VERSION "dbc-export 1 2025.20.8"

NS_ :

BS_:

BU_: ADSP APB APP APS APSB BB BMS CC CMP CMPD CP DAS DI DIF DIR DPB EPAS3P EPAS3S EPASTP EPASTS EPBL EPBR ESP EVSE FC GTW HCML HCMR HVP IBST ICR IDB LS OCS1P PARK PCS PM PMF PMR PNCD PTC RADC RCM RCM2 RCM3 RCU SCCM SCM SCS SDCR TAS TCU TPMS TRCM UI UIS UMC USM VC VCFRONT VCLEFT VCRIGHT VCSEC VEH

BO_ 609 VCFRONT_12VBatteryStatus: 8 VCFRONT
 SG_ VCFRONT_12VBatteryStatusIndex M : 0|3@1+ (1,0) [0|7] "" Vector__XXX
 SG_ VCFRONT_good12VforUpdate : 46|1@1+ (1,0) [0|1] "" Vector__XXX
 SG_ VCFRONT_LVLoadRequest : 47|1@1+ (1,0) [0|1] "" Vector__XXX
 SG_ VCFRONT_12VBatteryStatusCounter : 52|4@1+ (1,0) [0|15] "" Vector__XXX
 SG_ VCFRONT_12VBatteryStatusChecksum : 56|8@1+ (1,0) [0|255] "" Vector__XXX
 SG_ VCFRONT_batterySupportRequest m1 : 3|1@1+ (1,0) [0|1] "" Vector__XXX
 SG_ VCFRONT_batterySMState m1 : 4|4@1+ (1,0) [0|15] "" Vector__XXX
 SG_ VCFRONT_eFuseRecoveryStateDBG m1 : 8|3@1+ (1,0) [0|7] "" Vector__XXX
 SG_ VCFRONT_batteryLINScheduleDBG m1 : 11|3@1+ (1,0) [0|7] "" Vector__XXX
 SG_ VCFRONT_resistanceEstimationTest m1 : 14|2@1+ (1,0) [0|3] "" Vector__XXX
 SG_ VCFRONT_IBSCurrent m1 : 16|16@1- (0.005,0) [-163.84|163.835] "A" Vector__XXX
 SG_ VCFRONT_IBSVoltage m1 : 32|14@1+ (0.005443676,0) [0|65.535] "V" Vector__XXX
 SG_ VCFRONT_reverseBatteryFault m1 : 48|1@1+ (1,0) [0|1] "" Vector__XXX
 SG_ VCFRONT_LVBatterySupported m1 : 49|1@1+ (1,0) [0|1] "" Vector__XXX
 SG_ VCFRONT_LVBatteryCannotSupportVe m1 : 50|1@1+ (1,0) [0|1] "" Vector__XXX
 SG_ VCFRONT_goodTemp12VforUpdate m1 : 51|1@1+ (1,0) [0|1] "" Vector__XXX
 SG_ VCFRONT_12VBatteryTargetVoltage m2 : 3|13@1+ (0.01,0) [0|65.535] "V" Vector__XXX
 SG_ VCFRONT_IBSTemperature m2 : 16|11@1+ (0.1,-24) [-24|124] "degC" Vector__XXX
 SG_ VCFRONT_currentSensorMismatchLea m2 : 27|7@1+ (2,0) [0|254] "PCT" Vector__XXX
 SG_ VCFRONT_LVBatteryEnergyRemaining m2 : 37|7@1+ (1,0) [0|127] "%" Vector__XXX
 SG_ VCFRONT_LVBatteryStatusForDrive m2 : 44|2@1+ (1,0) [0|3] "" Vector__XXX
 SG_ VCFRONT_LVBatteryType m2 : 48|3@1+ (1,0) [0|7] "" Vector__XXX
 SG_ VCFRONT_resistanceEstimationNeed m2 : 51|1@1+ (1,0) [0|1] "" Vector__XXX
 SG_ VCFRONT_IBSVoltageFiltered m3 : 3|14@1+ (0.005443676,0) [0|65.535] "V" Vector__XXX
 SG_ VCFRONT_LVBMS_LVBusVoltageSource m3 : 17|2@1+ (1,0) [0|3] "" Vector__XXX
 SG_ VCFRONT_LVBMS_LVPackCurrentSourc m3 : 19|2@1+ (1,0) [0|3] "" Vector__XXX
 SG_ VCFRONT_LVBatterySupportRqrdTrig m3 : 24|14@1+ (1,0) [0|16383] "" Vector__XXX
 SG_ VCFRONT_goodForPCSPowerCycleLeak m3 : 40|5@1+ (0.0005,0) [0|0.0155] "Ah" Vector__XXX
 SG_ VCFRONT_LVBusControlsFutile m3 : 45|1@1+ (1,0) [0|1] "" Vector__XXX
 SG_ VCFRONT_resistanceEstimatio_0001 m3 : 48|1@1+ (1,0) [0|1] "" Vector__XXX
 SG_ VCFRONT_resistanceEstimatio_0002 m3 : 49|1@1+ (1,0) [0|1] "" Vector__XXX
 SG_ VCFRONT_goodLVChargeForUpdate m3 : 50|1@1+ (1,0) [0|1] "" Vector__XXX
 SG_ VCFRONT_opportunisticDCRTestNeed m3 : 51|1@1+ (1,0) [0|1] "" Vector__XXX
 SG_ VCFRONT_voltageProfile m4 : 3|2@1+ (1,0) [0|3] "" Vector__XXX
 SG_ VCFRONT_IBSAmpHours m4 : 5|14@1- (0.005,0) [-40.96|40.955] "Ah" Vector__XXX
 SG_ VCFRONT_IBSVoltageRawDBG m4 : 19|14@1+ (0.005443676,0) [0|65.535] "V" Vector__XXX
 SG_ VCFRONT_LVBatteryLINCommsDetecte m4 : 33|1@1+ (1,0) [0|1] "" Vector__XXX
 SG_ VCFRONT_voltageSensorMismatchLea m4 : 34|7@1+ (2,0) [0|254] "PCT" Vector__XXX
 SG_ VCFRONT_LVBatteryFctryLimOverrid m4 : 50|1@1+ (1,0) [0|1] "" Vector__XXX
 SG_ VCFRONT_LVBatterySPICommsDetecte m4 : 51|1@1+ (1,0) [0|1] "" Vector__XXX
 SG_ VCFRONT_targetCurrent m5 : 3|11@1+ (0.125,-127) [0|120] "A" Vector__XXX
 SG_ VCFRONT_PCSMia m5 : 14|1@1+ (1,0) [0|1] "" Vector__XXX
 SG_ VCFRONT_chargeNeeded m5 : 15|1@1+ (1,0) [0|1] "" Vector__XXX
 SG_ VCFRONT_voltageControlLoopIntegr m5 : 16|14@1+ (0.006,0) [0|65.535] "V" Vector__XXX
 SG_ VCFRONT_currentControlLoopIntegr m5 : 30|14@1+ (0.006,0) [0|65.535] "V" Vector__XXX

BO_ 1847 VCFRONT_LVBMS_info: 8 VCFRONT
 SG_ VCFRONT_LVBMS_InfoIndex M : 0|8@1+ (1,0) [0|255] "" Vector__XXX
 SG_ VCFRONT_LVBMS_PcbaId m0 : 8|16@1+ (1,0) [0|65535] "" Vector__XXX
 SG_ VCFRONT_LVBMS_AssemblyId m0 : 24|16@1+ (1,0) [0|65535] "" Vector__XXX
 SG_ VCFRONT_LVBMS_SubUsageId m0 : 40|16@1+ (1,0) [0|65535] "" Vector__XXX
 SG_ VCFRONT_LVBMS_UsageId m1 : 8|16@1+ (1,0) [0|65535] "" Vector__XXX
 SG_ VCFRONT_LVBMS_AppCRC m1 : 24|32@1+ (1,0) [0|4294967295] "" Vector__XXX
 SG_ VCFRONT_LVBMS_FWBuildType m3 : 8|8@1+ (1,0) [0|255] "" Vector__XXX

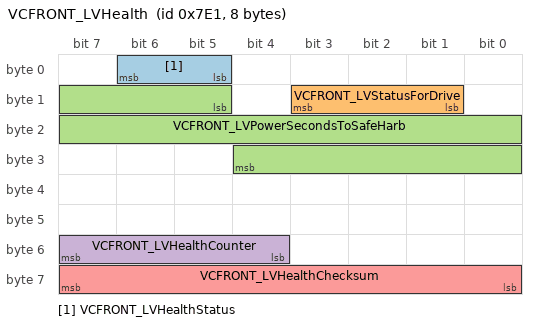
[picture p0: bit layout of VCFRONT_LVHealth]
BO_ 2017 VCFRONT_LVHealth: 8 VCFRONT
 SG_ VCFRONT_LVHealthStatus : 5|2@1+ (1,0) [0|3] "" Vector__XXX
 SG_ VCFRONT_LVStatusForDrive : 9|3@1+ (1,0) [0|7] "" Vector__XXX
 SG_ VCFRONT_LVPowerSecondsToSafeHarb : 13|16@1+ (1,0) [0|65535] "" Vector__XXX
 SG_ VCFRONT_LVHealthCounter : 52|4@1+ (1,0) [0|15] "" Vector__XXX
 SG_ VCFRONT_LVHealthChecksum : 56|8@1+ (1,0) [0|255] "" Vector__XXX

BO_ 2016 VCFRONT_LVHealthDebug: 8 VCFRONT
 SG_ VCFRONT_LVHealthDebugIndex M : 0|4@1+ (1,0) [0|15] "" Vector__XXX
 SG_ VCFRONT_LVHEALTH_placeholder m0 : 8|1@1+ (1,0) [0|1] "" Vector__XXX
 SG_ VCFRONT_LVHEALTH_activeDecelEner m0 : 9|1@1+ (1,0) [0|1] "" Vector__XXX
 SG_ VCFRONT_LVHEALTH_criticalPullove m0 : 10|1@1+ (1,0) [0|1] "" Vector__XXX
 SG_ VCFRONT_LVHEALTH_revBattEFuseOff m0 : 11|1@1+ (1,0) [0|1] "" Vector__XXX
 SG_ VCFRONT_LVHEALTH_LVBMBEFuseOpen m0 : 12|1@1+ (1,0) [0|1] "" Vector__XXX
 SG_ VCFRONT_LVHEALTH_lvBatteryCommsM m0 : 13|1@1+ (1,0) [0|1] "" Vector__XXX
 SG_ VCFRONT_LVHEALTH_pcsEFuseOff m0 : 14|1@1+ (1,0) [0|1] "" Vector__XXX
 SG_ VCFRONT_LVHEALTH_pcsNotActive m0 : 15|1@1+ (1,0) [0|1] "" Vector__XXX
 SG_ VCFRONT_LVHEALTH_pcsMIA m0 : 16|1@1+ (1,0) [0|1] "" Vector__XXX
 SG_ VCFRONT_LVHEALTH_IBSMIA m0 : 17|1@1+ (1,0) [0|1] "" Vector__XXX
 SG_ VCFRONT_LVHEALTH_LVBatteryElecDi m0 : 18|1@1+ (1,0) [0|1] "" Vector__XXX
 SG_ VCFRONT_LVHEALTH_LVBatteryE_0001 m0 : 19|1@1+ (1,0) [0|1] "" Vector__XXX
 SG_ VCFRONT_LVHEALTH_pcsOpenCircuit m0 : 20|1@1+ (1,0) [0|1] "" Vector__XXX
 SG_ VCFRONT_LVHEALTH_activeDecelPowe m0 : 21|1@1+ (1,0) [0|1] "" Vector__XXX
 SG_ VCFRONT_LVHEALTH_lvBatteryCapabi m0 : 22|1@1+ (1,0) [0|1] "" Vector__XXX
 SG_ VCFRONT_LVHEALTH_lvBatteryConfig m0 : 23|1@1+ (1,0) [0|1] "" Vector__XXX
 SG_ VCFRONT_LVHEALTH_lvBatteryImpeda m0 : 24|1@1+ (1,0) [0|1] "" Vector__XXX

BO_ 545 VCFRONT_LVPowerState: 8 VCFRONT
 SG_ VCFRONT_LVPowerStateIndex M : 0|5@1+ (1,0) [0|31] "" Vector__XXX
 SG_ VCFRONT_vehiclePowerState : 5|2@1+ (1,0) [0|3] "" Vector__XXX
 SG_ VCFRONT_inAccessoryPlus : 50|1@1+ (1,0) [0|1] "" Vector__XXX
 SG_ VCFRONT_LVShuttingDown : 51|1@1+ (1,0) [0|1] "" Vector__XXX
 SG_ VCFRONT_LVPowerStateCounter : 52|4@1+ (1,0) [0|15] "" Vector__XXX
 SG_ VCFRONT_LVPowerStateChecksum : 56|8@1+ (1,0) [0|255] "" Vector__XXX
 SG_ VCFRONT_cpLVRequest m1 : 8|2@1+ (1,0) [0|3] "" Vector__XXX
 SG_ VCFRONT_epasLVState m1 : 10|2@1+ (1,0) [0|3] "" Vector__XXX
 SG_ VCFRONT_hvcLVRequest m1 : 12|2@1+ (1,0) [0|3] "" Vector__XXX
 SG_ VCFRONT_tasLVState m1 : 14|2@1+ (1,0) [0|3] "" Vector__XXX
 SG_ VCFRONT_pcsLVState m1 : 16|2@1+ (1,0) [0|3] "" Vector__XXX
 SG_ VCFRONT_CMPDLVState m1 : 18|2@1+ (1,0) [0|3] "" Vector__XXX
 SG_ VCFRONT_hcmlLVState m1 : 20|2@1+ (1,0) [0|3] "" Vector__XXX
 SG_ VCFRONT_hcmrLVState m1 : 22|2@1+ (1,0) [0|3] "" Vector__XXX
 SG_ VCFRONT_MCUAudioLVState m1 : 24|2@1+ (1,0) [0|3] "" Vector__XXX
 SG_ VCFRONT_espValveLVState m1 : 26|2@1+ (1,0) [0|3] "" Vector__XXX
 SG_ VCFRONT_MCUGraphicsLVState m1 : 28|2@1+ (1,0) [0|3] "" Vector__XXX
 SG_ VC_dcdcSupportRequest m1 : 30|1@1+ (1,0) [0|1] "" Vector__XXX
 SG_ VC_hvStateRequest m1 : 31|3@1+ (1,0) [0|7] "" Vector__XXX
 SG_ VC_persistAccPowerRequestOverrid m1 : 39|1@1+ (1,0) [0|1] "" Vector__XXX
 SG_ VC_accPortPowerRequest m1 : 40|1@1+ (1,0) [0|1] "" Vector__XXX
 SG_ VC_persistAccPortPowerState m1 : 41|3@1+ (1,0) [0|7] "" Vector__XXX

BO_ 700 VCFRONT_LVThermalMotors10Hz: 8 VCFRONT
 SG_ VCFRONT_LVThermalMotorsIndex M : 0|4@1+ (1,0) [0|15] "" Vector__XXX
 SG_ VCFRONT_radiatorFanState m0 : 4|3@1+ (1,0) [0|7] "" Vector__XXX
 SG_ VCFRONT_radiatorFanTorque m0 : 8|10@1+ (0.006,-1.5) [-1.5|4.5] "Nm" Vector__XXX
 SG_ VCFRONT_radiatorFanIDc m0 : 24|7@1+ (0.5,0) [0|63] "A" Vector__XXX
 SG_ VCFRONT_mlxLINCurrentSchedule m0 : 32|2@1+ (1,0) [0|3] "" Vector__XXX
 SG_ VCFRONT_pumpPowertrainState m3 : 4|3@1+ (1,0) [0|7] "" Vector__XXX
 SG_ VCFRONT_pumpPowertrainTorque m3 : 8|10@1+ (0.006,-1.5) [-1.5|4.5] "Nm" Vector__XXX
 SG_ VCFRONT_pumpPowertrainIDc m3 : 24|7@1+ (0.5,0) [0|63] "A" Vector__XXX
 SG_ VCFRONT_pumpBatteryState m6 : 4|3@1+ (1,0) [0|7] "" Vector__XXX
 SG_ VCFRONT_pumpBatteryTorque m6 : 8|10@1+ (0.006,-1.5) [-1.5|4.5] "Nm" Vector__XXX
 SG_ VCFRONT_pumpBatteryIDc m6 : 24|7@1+ (0.5,0) [0|63] "A" Vector__XXX

BO_ 1332 VCFRONT_alertLog: 8 VCFRONT
 SG_ VCFRONT_alertID M : 0|10@1+ (1,0) [0|1023] "" Vector__XXX
 SG_ VCFRONT_alertState : 15|1@1+ (1,0) [0|1] "" Vector__XXX
 SG_ VCFRONT_a001_InternalWatchdog m1 : 16|1@1+ (1,0) [0|1] "" Vector__XXX
 SG_ VCFRONT_a002_CPUUndervoltage m2 : 16|1@1+ (1,0) [0|1] "" Vector__XXX
 SG_ VCFRONT_a002_PowerOnReset m2 : 17|1@1+ (1,0) [0|1] "" Vector__XXX
 SG_ VCFRONT_a004_APPWatchdogFaultOrM m4 : 16|1@1+ (1,0) [0|1] "" Vector__XXX
 SG_ VCFRONT_a004_DASHighLowBeamDecis m4 : 17|1@1+ (1,0) [0|1] "" Vector__XXX
 SG_ VCFRONT_a004_DASAdaptiveHighBeam m4 : 18|1@1+ (1,0) [0|1] "" Vector__XXX
 SG_ VCFRONT_a004_DASMatrixColumnMsgM m4 : 19|1@1+ (1,0) [0|1] "" Vector__XXX
 SG_ VCFRONT_a004_DASBendAngleMsgMIA m4 : 20|1@1+ (1,0) [0|1] "" Vector__XXX
 SG_ VCFRONT_a004_EPAS3PNotInSpecOrMI m4 : 21|1@1+ (1,0) [0|1] "" Vector__XXX
 SG_ VCFRONT_a008_APPWatchdogFaultOrM m8 : 16|1@1+ (1,0) [0|1] "" Vector__XXX
 SG_ VCFRONT_a008_DASHighLowBeamDecis m8 : 17|1@1+ (1,0) [0|1] "" Vector__XXX
 SG_ VCFRONT_a008_DASAdaptiveHighBeam m8 : 18|1@1+ (1,0) [0|1] "" Vector__XXX
 SG_ VCFRONT_a008_DASMatrixColumnMsgM m8 : 19|1@1+ (1,0) [0|1] "" Vector__XXX
 SG_ VCFRONT_a008_DASBendAngleMsgMIA m8 : 20|1@1+ (1,0) [0|1] "" Vector__XXX
 SG_ VCFRONT_a008_EPAS3PNotInSpecOrMI m8 : 21|1@1+ (1,0) [0|1] "" Vector__XXX
 SG_ VCFRONT_a010_UnderVoltageDetecte m10 : 16|1@1+ (1,0) [0|1] "" Vector__XXX
 SG_ VCFRONT_a010_UnderVoltageTimeout m10 : 17|1@1+ (1,0) [0|1] "" Vector__XXX
 SG_ VCFRONT_a015_NVMMMemOverflow m15 : 16|1@1+ (1,0) [0|1] "" Vector__XXX
 SG_ VCFRONT_a015_NVMMFilesystemError m15 : 17|1@1+ (1,0) [0|1] "" Vector__XXX
 SG_ VCFRONT_a015_NVMMRecordIDError m15 : 18|1@1+ (1,0) [0|1] "" Vector__XXX
 SG_ VCFRONT_a057_VEH_cpControl m57 : 16|1@1+ (1,0) [0|1] "" Vector__XXX
 SG_ VCFRONT_a059_voltageDrop m59 : 16|12@1+ (0.005443676,0) [0|22.29185322] "" Vector__XXX
 SG_ VCFRONT_a059_resistanceEstimate m59 : 28|12@1+ (0.00244,0) [0|9.9918] "" Vector__XXX
 SG_ VCFRONT_a059_current m59 : 40|12@1+ (0.05,0) [0|204.75] "" Vector__XXX
 SG_ VCFRONT_a063_switchChannel m63 : 16|8@1+ (1,0) [0|255] "" Vector__XXX
 SG_ VCFRONT_a063_switchType m63 : 24|8@1+ (1,0) [0|255] "" Vector__XXX
 SG_ VCFRONT_a063_ADCVoltage m63 : 32|8@1+ (0.025,0) [0|6.375] "" Vector__XXX
 SG_ VCFRONT_a063_disconnected m63 : 40|1@1+ (1,0) [0|1] "" Vector__XXX
 SG_ VCFRONT_a063_indeterminate m63 : 41|1@1+ (1,0) [0|1] "" Vector__XXX
 SG_ VCFRONT_a063_stuckActive m63 : 42|1@1+ (1,0) [0|1] "" Vector__XXX
 SG_ VCFRONT_a063_faulted m63 : 43|1@1+ (1,0) [0|1] "" Vector__XXX
 SG_ VCFRONT_a082_RIPC_epbPrivateStat m82 : 16|1@1+ (1,0) [0|1] "" Vector__XXX
 SG_ VCFRONT_a082_RIPC_remoteHSD m82 : 17|1@1+ (1,0) [0|1] "" Vector__XXX
 SG_ VCFRONT_a082_RIPC_railStatus m82 : 18|1@1+ (1,0) [0|1] "" Vector__XXX
 SG_ VCFRONT_a082_RIPC_remoteMux m82 : 19|1@1+ (1,0) [0|1] "" Vector__XXX
 SG_ VCFRONT_a083_LIPC_epbPrivateStat m83 : 16|1@1+ (1,0) [0|1] "" Vector__XXX
 SG_ VCFRONT_a083_LIPC_remoteHSD m83 : 17|1@1+ (1,0) [0|1] "" Vector__XXX
 SG_ VCFRONT_a083_LIPC_railStatus m83 : 18|1@1+ (1,0) [0|1] "" Vector__XXX
 SG_ VCFRONT_a083_LIPC_HSDFaults m83 : 19|1@1+ (1,0) [0|1] "" Vector__XXX
 SG_ VCFRONT_a084_CH_StatusC m84 : 16|1@1+ (1,0) [0|1] "" Vector__XXX
 SG_ VCFRONT_a085_PARTY_buttonStatus m85 : 16|1@1+ (1,0) [0|1] "" Vector__XXX
 SG_ VCFRONT_a086_VEH_LVBMS_statusHig m86 : 16|1@1+ (1,0) [0|1] "" Vector__XXX
 SG_ VCFRONT_a086_VEH_LVBMS_statusLow m86 : 17|1@1+ (1,0) [0|1] "" Vector__XXX
 SG_ VCFRONT_a086_VEH_status m86 : 18|1@1+ (1,0) [0|1] "" Vector__XXX
 SG_ VCFRONT_a086_VEH_12VBatteryStatu m86 : 19|1@1+ (1,0) [0|1] "" Vector__XXX
 SG_ VCFRONT_a086_VEH_LVPowerState m86 : 20|1@1+ (1,0) [0|1] "" Vector__XXX
 SG_ VCFRONT_a086_VEH_lightStatus m86 : 21|1@1+ (1,0) [0|1] "" Vector__XXX
 SG_ VCFRONT_a086_VEH_systemStatus m86 : 22|1@1+ (1,0) [0|1] "" Vector__XXX
 SG_ VCFRONT_a086_VEH_thermalStatus m86 : 23|1@1+ (1,0) [0|1] "" Vector__XXX
 SG_ VCFRONT_a086_VEH_vehNm m86 : 24|1@1+ (1,0) [0|1] "" Vector__XXX
 SG_ VCFRONT_a087_VEH_temperature m87 : 16|1@1+ (1,0) [0|1] "" Vector__XXX
 SG_ VCFRONT_a087_VEH_thermalControl m87 : 17|1@1+ (1,0) [0|1] "" Vector__XXX
 SG_ VCFRONT_a087_VEH_torque m87 : 18|1@1+ (1,0) [0|1] "" Vector__XXX
 SG_ VCFRONT_a087_VEH_status m87 : 19|1@1+ (1,0) [0|1] "" Vector__XXX
 SG_ VCFRONT_a087_PARTY_torque m87 : 20|1@1+ (1,0) [0|1] "" Vector__XXX
 SG_ VCFRONT_a087_PARTY_status m87 : 21|1@1+ (1,0) [0|1] "" Vector__XXX
 SG_ VCFRONT_a087_PARTY_temperature m87 : 22|1@1+ (1,0) [0|1] "" Vector__XXX
 SG_ VCFRONT_a087_PARTY_thermalContro m87 : 23|1@1+ (1,0) [0|1] "" Vector__XXX
 SG_ VCFRONT_a088_VEH_temperature m88 : 16|1@1+ (1,0) [0|1] "" Vector__XXX
 SG_ VCFRONT_a088_VEH_thermalControl m88 : 17|1@1+ (1,0) [0|1] "" Vector__XXX
 SG_ VCFRONT_a088_VEH_torque m88 : 18|1@1+ (1,0) [0|1] "" Vector__XXX
 SG_ VCFRONT_a088_VEH_status m88 : 19|1@1+ (1,0) [0|1] "" Vector__XXX
 SG_ VCFRONT_a088_PARTY_torque m88 : 20|1@1+ (1,0) [0|1] "" Vector__XXX
 SG_ VCFRONT_a088_PARTY_status m88 : 21|1@1+ (1,0) [0|1] "" Vector__XXX
 SG_ VCFRONT_a088_PARTY_temperature m88 : 22|1@1+ (1,0) [0|1] "" Vector__XXX
 SG_ VCFRONT_a088_PARTY_thermalContro m88 : 23|1@1+ (1,0) [0|1] "" Vector__XXX
 SG_ VCFRONT_a089_PARTY_party1 m89 : 16|1@1+ (1,0) [0|1] "" Vector__XXX
 SG_ VCFRONT_a089_PARTY_status m89 : 17|1@1+ (1,0) [0|1] "" Vector__XXX
 SG_ VCFRONT_a089_VEH_status m89 : 18|1@1+ (1,0) [0|1] "" Vector__XXX
 SG_ VCFRONT_a089_BDY_party1 m89 : 19|1@1+ (1,0) [0|1] "" Vector__XXX
 SG_ VCFRONT_a089_BDY_status m89 : 20|1@1+ (1,0) [0|1] "" Vector__XXX
 SG_ VCFRONT_a089_CH_status m89 : 21|1@1+ (1,0) [0|1] "" Vector__XXX
 SG_ VCFRONT_a089_CH_party1 m89 : 22|1@1+ (1,0) [0|1] "" Vector__XXX
 SG_ VCFRONT_a089_CH_party3 m89 : 23|1@1+ (1,0) [0|1] "" Vector__XXX
 SG_ VCFRONT_a089_VEH_party1 m89 : 24|1@1+ (1,0) [0|1] "" Vector__XXX
 SG_ VCFRONT_a089_VEH_party3 m89 : 25|1@1+ (1,0) [0|1] "" Vector__XXX
 SG_ VCFRONT_a091_VEH_faultsAndExtras m91 : 16|1@1+ (1,0) [0|1] "" Vector__XXX
 SG_ VCFRONT_a091_VEH_info m91 : 17|1@1+ (1,0) [0|1] "" Vector__XXX
 SG_ VCFRONT_a091_VEH_state m91 : 18|1@1+ (1,0) [0|1] "" Vector__XXX
 SG_ VCFRONT_a092_VEH_restraintStatus m92 : 16|1@1+ (1,0) [0|1] "" Vector__XXX
 SG_ VCFRONT_a092_VEH_switchStatus m92 : 17|1@1+ (1,0) [0|1] "" Vector__XXX
 SG_ VCFRONT_a092_VEH_seatStatus2 m92 : 18|1@1+ (1,0) [0|1] "" Vector__XXX
 SG_ VCFRONT_a092_VEH_vehNm m92 : 19|1@1+ (1,0) [0|1] "" Vector__XXX
 SG_ VCFRONT_a093_VEH_restraintStatus m93 : 16|1@1+ (1,0) [0|1] "" Vector__XXX
 SG_ VCFRONT_a093_VEH_switchStatus m93 : 17|1@1+ (1,0) [0|1] "" Vector__XXX
 SG_ VCFRONT_a093_VEH_seatStatus2 m93 : 18|1@1+ (1,0) [0|1] "" Vector__XXX
 SG_ VCFRONT_a093_VEH_vehNm m93 : 19|1@1+ (1,0) [0|1] "" Vector__XXX
 SG_ VCFRONT_a094_VEH_sysStatus m94 : 16|1@1+ (1,0) [0|1] "" Vector__XXX
 SG_ VCFRONT_a094_PARTY_sysStatus m94 : 17|1@1+ (1,0) [0|1] "" Vector__XXX
 SG_ VCFRONT_a095_PT_ptNm m95 : 16|1@1+ (1,0) [0|1] "" Vector__XXX
 SG_ VCFRONT_a095_PT_status m95 : 17|1@1+ (1,0) [0|1] "" Vector__XXX
 SG_ VCFRONT_a096_VEH_status m96 : 16|1@1+ (1,0) [0|1] "" Vector__XXX
 SG_ VCFRONT_a096_CH_status m96 : 17|1@1+ (1,0) [0|1] "" Vector__XXX
 SG_ VCFRONT_a098_CH_torque m98 : 16|1@1+ (1,0) [0|1] "" Vector__XXX
 SG_ VCFRONT_a098_VEH_hvStatus m98 : 17|1@1+ (1,0) [0|1] "" Vector__XXX
 SG_ VCFRONT_a098_VEH_status m98 : 18|1@1+ (1,0) [0|1] "" Vector__XXX
 SG_ VCFRONT_a098_VEH_thermalControl m98 : 19|1@1+ (1,0) [0|1] "" Vector__XXX
 SG_ VCFRONT_a098_VEH_temperature m98 : 20|1@1+ (1,0) [0|1] "" Vector__XXX
 SG_ VCFRONT_a098_VEH_torque m98 : 21|1@1+ (1,0) [0|1] "" Vector__XXX
 SG_ VCFRONT_a098_PARTY_status m98 : 22|1@1+ (1,0) [0|1] "" Vector__XXX
 SG_ VCFRONT_a098_PARTY_temperature m98 : 23|1@1+ (1,0) [0|1] "" Vector__XXX
 SG_ VCFRONT_a098_PARTY_thermalContro m98 : 24|1@1+ (1,0) [0|1] "" Vector__XXX
 SG_ VCFRONT_a098_PARTY_torque m98 : 25|1@1+ (1,0) [0|1] "" Vector__XXX
 SG_ VCFRONT_a098_PT_thermalControl m98 : 26|1@1+ (1,0) [0|1] "" Vector__XXX
 SG_ VCFRONT_a098_PT_temperature m98 : 27|1@1+ (1,0) [0|1] "" Vector__XXX
 SG_ VCFRONT_a099_VEH_oocStatus m99 : 16|1@1+ (1,0) [0|1] "" Vector__XXX
 SG_ VCFRONT_a100_VEH m100 : 16|1@1+ (1,0) [0|1] "" Vector__XXX
 SG_ VCFRONT_a100_PARTY m100 : 17|1@1+ (1,0) [0|1] "" Vector__XXX
 SG_ VCFRONT_a100_PT m100 : 18|1@1+ (1,0) [0|1] "" Vector__XXX
 SG_ VCFRONT_a100_CH m100 : 19|1@1+ (1,0) [0|1] "" Vector__XXX
 SG_ VCFRONT_a100_OBD m100 : 20|1@1+ (1,0) [0|1] "" Vector__XXX
 SG_ VCFRONT_a101_VEH_state m101 : 16|1@1+ (1,0) [0|1] "" Vector__XXX
 SG_ VCFRONT_a101_PARTY_locState m101 : 17|1@1+ (1,0) [0|1] "" Vector__XXX
 SG_ VCFRONT_a101_LIPC_externalWatchd m101 : 18|1@1+ (1,0) [0|1] "" Vector__XXX
 SG_ VCFRONT_a101_VEH_locState m101 : 19|1@1+ (1,0) [0|1] "" Vector__XXX
 SG_ VCFRONT_a101_BDY_locState m101 : 20|1@1+ (1,0) [0|1] "" Vector__XXX
 SG_ VCFRONT_a102_VEH_faultsAndExtras m102 : 16|1@1+ (1,0) [0|1] "" Vector__XXX
 SG_ VCFRONT_a102_VEH_feedbackStatus m102 : 17|1@1+ (1,0) [0|1] "" Vector__XXX
 SG_ VCFRONT_a102_VEH_sensorStatus m102 : 18|1@1+ (1,0) [0|1] "" Vector__XXX
 SG_ VCFRONT_a102_VEH_rods m102 : 19|1@1+ (1,0) [0|1] "" Vector__XXX
 SG_ VCFRONT_a103_VEH_hvsNm m103 : 16|1@1+ (1,0) [0|1] "" Vector__XXX
 SG_ VCFRONT_a103_VEH_vehNm m103 : 17|1@1+ (1,0) [0|1] "" Vector__XXX
 SG_ VCFRONT_a103_VEH_status m103 : 18|1@1+ (1,0) [0|1] "" Vector__XXX
 SG_ VCFRONT_a103_PT_ptNm m103 : 19|1@1+ (1,0) [0|1] "" Vector__XXX
 SG_ VCFRONT_a103_PT_status m103 : 20|1@1+ (1,0) [0|1] "" Vector__XXX
 SG_ VCFRONT_a103_VEH_evseStatus m103 : 21|1@1+ (1,0) [0|1] "" Vector__XXX
 SG_ VCFRONT_a105_VEH_states m105 : 16|1@1+ (1,0) [0|1] "" Vector__XXX
 SG_ VCFRONT_a105_VEH_chNm m105 : 17|1@1+ (1,0) [0|1] "" Vector__XXX
 SG_ VCFRONT_a105_VEH_dampingStates m105 : 18|1@1+ (1,0) [0|1] "" Vector__XXX
 SG_ VCFRONT_a106_VEH_dcdcStatus m106 : 16|1@1+ (1,0) [0|1] "" Vector__XXX
 SG_ VCFRONT_a106_VEH_thermalControl m106 : 17|1@1+ (1,0) [0|1] "" Vector__XXX
 SG_ VCFRONT_a106_VEH_thermalInterfac m106 : 18|1@1+ (1,0) [0|1] "" Vector__XXX
 SG_ VCFRONT_a106_VEH_dcdcRailStatus m106 : 19|1@1+ (1,0) [0|1] "" Vector__XXX
 SG_ VCFRONT_a106_CH_dcdcRailStatus m106 : 20|1@1+ (1,0) [0|1] "" Vector__XXX
 SG_ VCFRONT_a106_CH_alertMatrix m106 : 21|1@1+ (1,0) [0|1] "" Vector__XXX
 SG_ VCFRONT_a107_VEH_hvsNm m107 : 16|1@1+ (1,0) [0|1] "" Vector__XXX
 SG_ VCFRONT_a107_VEH_vehNm m107 : 17|1@1+ (1,0) [0|1] "" Vector__XXX
 SG_ VCFRONT_a107_VEH_status m107 : 18|1@1+ (1,0) [0|1] "" Vector__XXX
 SG_ VCFRONT_a107_VEH_thermalStatus m107 : 19|1@1+ (1,0) [0|1] "" Vector__XXX
 SG_ VCFRONT_a107_VEH_thermalStatus2 m107 : 20|1@1+ (1,0) [0|1] "" Vector__XXX
 SG_ VCFRONT_a107_VEH_bmbMinMax m107 : 21|1@1+ (1,0) [0|1] "" Vector__XXX
 SG_ VCFRONT_a107_VEH_powerAvailable m107 : 22|1@1+ (1,0) [0|1] "" Vector__XXX
 SG_ VCFRONT_a107_PT_ptNm m107 : 23|1@1+ (1,0) [0|1] "" Vector__XXX
 SG_ VCFRONT_a107_PT_status m107 : 24|1@1+ (1,0) [0|1] "" Vector__XXX
 SG_ VCFRONT_a107_PT_thermalStatus m107 : 25|1@1+ (1,0) [0|1] "" Vector__XXX
 SG_ VCFRONT_a107_PT_socStatus m107 : 26|1@1+ (1,0) [0|1] "" Vector__XXX
 SG_ VCFRONT_a107_VEH_socStatus m107 : 27|1@1+ (1,0) [0|1] "" Vector__XXX
 SG_ VCFRONT_a107_VEH_packConfig m107 : 28|1@1+ (1,0) [0|1] "" Vector__XXX
 SG_ VCFRONT_a107_VEH_energyStatus m107 : 29|1@1+ (1,0) [0|1] "" Vector__XXX
 SG_ VCFRONT_a107_VEH_chargeInfo m107 : 30|1@1+ (1,0) [0|1] "" Vector__XXX
 SG_ VCFRONT_a108_VEH_hvStatus m108 : 16|1@1+ (1,0) [0|1] "" Vector__XXX
 SG_ VCFRONT_a108_VEH_temperature m108 : 17|1@1+ (1,0) [0|1] "" Vector__XXX
 SG_ VCFRONT_a108_VEH_thermalControl m108 : 18|1@1+ (1,0) [0|1] "" Vector__XXX
 SG_ VCFRONT_a108_VEH_torque m108 : 19|1@1+ (1,0) [0|1] "" Vector__XXX
 SG_ VCFRONT_a108_VEH_status m108 : 20|1@1+ (1,0) [0|1] "" Vector__XXX
 SG_ VCFRONT_a108_PARTY_torque m108 : 21|1@1+ (1,0) [0|1] "" Vector__XXX
 SG_ VCFRONT_a108_PARTY_status m108 : 22|1@1+ (1,0) [0|1] "" Vector__XXX
 SG_ VCFRONT_a108_PARTY_temperature m108 : 23|1@1+ (1,0) [0|1] "" Vector__XXX
 SG_ VCFRONT_a108_PARTY_thermalContro m108 : 24|1@1+ (1,0) [0|1] "" Vector__XXX
 SG_ VCFRONT_a108_PT_temperature m108 : 25|1@1+ (1,0) [0|1] "" Vector__XXX
 SG_ VCFRONT_a108_PT_thermalControl m108 : 26|1@1+ (1,0) [0|1] "" Vector__XXX
 SG_ VCFRONT_a109_PARTY_status m109 : 16|1@1+ (1,0) [0|1] "" Vector__XXX
 SG_ VCFRONT_a109_PARTY_inertial2 m109 : 17|1@1+ (1,0) [0|1] "" Vector__XXX
 SG_ VCFRONT_a109_PARTY_nearDeploy m109 : 18|1@1+ (1,0) [0|1] "" Vector__XXX
 SG_ VCFRONT_a109_PARTY_collision m109 : 19|1@1+ (1,0) [0|1] "" Vector__XXX
 SG_ VCFRONT_a109_VEH_status m109 : 20|1@1+ (1,0) [0|1] "" Vector__XXX
 SG_ VCFRONT_a109_VEH_imuOffsets m109 : 21|1@1+ (1,0) [0|1] "" Vector__XXX
 SG_ VCFRONT_a109_PARTY_inertial1 m109 : 22|1@1+ (1,0) [0|1] "" Vector__XXX
 SG_ VCFRONT_a109_BDY_imuOffsets m109 : 23|1@1+ (1,0) [0|1] "" Vector__XXX
 SG_ VCFRONT_a109_BDY_inertial1 m109 : 24|1@1+ (1,0) [0|1] "" Vector__XXX
 SG_ VCFRONT_a109_BDY_inertial2 m109 : 25|1@1+ (1,0) [0|1] "" Vector__XXX
 SG_ VCFRONT_a109_BDY_status m109 : 26|1@1+ (1,0) [0|1] "" Vector__XXX
 SG_ VCFRONT_a109_VEH_inertial1 m109 : 27|1@1+ (1,0) [0|1] "" Vector__XXX
 SG_ VCFRONT_a109_VEH_inertial2 m109 : 28|1@1+ (1,0) [0|1] "" Vector__XXX
 SG_ VCFRONT_a109_CH_inertial1 m109 : 29|1@1+ (1,0) [0|1] "" Vector__XXX
 SG_ VCFRONT_a109_CH_inertial2 m109 : 30|1@1+ (1,0) [0|1] "" Vector__XXX
 SG_ VCFRONT_a109_CH_status m109 : 31|1@1+ (1,0) [0|1] "" Vector__XXX
 SG_ VCFRONT_a110_VEH_status m110 : 16|1@1+ (1,0) [0|1] "" Vector__XXX
 SG_ VCFRONT_a110_VEH_carState m110 : 17|1@1+ (1,0) [0|1] "" Vector__XXX
 SG_ VCFRONT_a110_VEH_carConfig m110 : 18|1@1+ (1,0) [0|1] "" Vector__XXX
 SG_ VCFRONT_a110_VEH_time m110 : 19|1@1+ (1,0) [0|1] "" Vector__XXX
 SG_ VCFRONT_a110_VEH_updateStatus m110 : 20|1@1+ (1,0) [0|1] "" Vector__XXX
 SG_ VCFRONT_a110_VEH_vehNm m110 : 21|1@1+ (1,0) [0|1] "" Vector__XXX
 SG_ VCFRONT_a110_VEH_mismatchFault m110 : 22|1@1+ (1,0) [0|1] "" Vector__XXX
 SG_ VCFRONT_a110_VEH_vin m110 : 23|1@1+ (1,0) [0|1] "" Vector__XXX
 SG_ VCFRONT_a110_VEH_bmpDebug m110 : 24|1@1+ (1,0) [0|1] "" Vector__XXX
 SG_ VCFRONT_a110_VEH_gearControl m110 : 25|1@1+ (1,0) [0|1] "" Vector__XXX
 SG_ VCFRONT_a110_VEH_canLogAvailabil m110 : 26|1@1+ (1,0) [0|1] "" Vector__XXX
 SG_ VCFRONT_a110_CH_airbagCutoffStat m110 : 27|1@1+ (1,0) [0|1] "" Vector__XXX
 SG_ VCFRONT_a110_CH_carConfig m110 : 28|1@1+ (1,0) [0|1] "" Vector__XXX
 SG_ VCFRONT_a110_CH_carState m110 : 29|1@1+ (1,0) [0|1] "" Vector__XXX
 SG_ VCFRONT_a110_CH_vin m110 : 30|1@1+ (1,0) [0|1] "" Vector__XXX
 SG_ VCFRONT_a110_CH_chNm m110 : 31|1@1+ (1,0) [0|1] "" Vector__XXX
 SG_ VCFRONT_a110_CH_epochTimeGtw m110 : 32|1@1+ (1,0) [0|1] "" Vector__XXX
 SG_ VCFRONT_a111_VEH_internalStatus m111 : 16|1@1+ (1,0) [0|1] "" Vector__XXX
 SG_ VCFRONT_a111_VEH_status m111 : 17|1@1+ (1,0) [0|1] "" Vector__XXX
 SG_ VCFRONT_a111_VEH_vehNm m111 : 18|1@1+ (1,0) [0|1] "" Vector__XXX
 SG_ VCFRONT_a111_RIPC_LVPowerState m111 : 19|1@1+ (1,0) [0|1] "" Vector__XXX
 SG_ VCFRONT_a111_RIPC_epbPrivateStat m111 : 20|1@1+ (1,0) [0|1] "" Vector__XXX
 SG_ VCFRONT_a111_RIPC_railStatus m111 : 21|1@1+ (1,0) [0|1] "" Vector__XXX
 SG_ VCFRONT_a111_RIPC_remoteADC m111 : 22|1@1+ (1,0) [0|1] "" Vector__XXX
 SG_ VCFRONT_a111_RIPC_switchStatus m111 : 23|1@1+ (1,0) [0|1] "" Vector__XXX
 SG_ VCFRONT_a111_VEH_LVPowerState m111 : 24|1@1+ (1,0) [0|1] "" Vector__XXX
 SG_ VCFRONT_a111_VEH_seatStatus m111 : 25|1@1+ (1,0) [0|1] "" Vector__XXX
 SG_ VCFRONT_a111_PARTY_status m111 : 26|1@1+ (1,0) [0|1] "" Vector__XXX
 SG_ VCFRONT_a111_CH_status m111 : 27|1@1+ (1,0) [0|1] "" Vector__XXX
 SG_ VCFRONT_a112_VEH_internalStatus m112 : 16|1@1+ (1,0) [0|1] "" Vector__XXX
 SG_ VCFRONT_a112_VEH_status m112 : 17|1@1+ (1,0) [0|1] "" Vector__XXX
 SG_ VCFRONT_a112_VEH_vehNm m112 : 18|1@1+ (1,0) [0|1] "" Vector__XXX
 SG_ VCFRONT_a112_LIPC_LVPowerState m112 : 19|1@1+ (1,0) [0|1] "" Vector__XXX
 SG_ VCFRONT_a112_LIPC_epbPrivateStat m112 : 20|1@1+ (1,0) [0|1] "" Vector__XXX
 SG_ VCFRONT_a112_LIPC_railStatus m112 : 21|1@1+ (1,0) [0|1] "" Vector__XXX
 SG_ VCFRONT_a112_LIPC_remoteADC m112 : 22|1@1+ (1,0) [0|1] "" Vector__XXX
 SG_ VCFRONT_a112_LIPC_switchStatus m112 : 23|1@1+ (1,0) [0|1] "" Vector__XXX
 SG_ VCFRONT_a112_VEH_LVPowerState m112 : 24|1@1+ (1,0) [0|1] "" Vector__XXX
 SG_ VCFRONT_a112_PARTY_status m112 : 25|1@1+ (1,0) [0|1] "" Vector__XXX
 SG_ VCFRONT_a112_CH_status m112 : 26|1@1+ (1,0) [0|1] "" Vector__XXX
 SG_ VCFRONT_a114_PARTY_status m114 : 16|1@1+ (1,0) [0|1] "" Vector__XXX
 SG_ VCFRONT_a114_PARTY_wheelSpeeds m114 : 17|1@1+ (1,0) [0|1] "" Vector__XXX
 SG_ VCFRONT_a114_VEH_wheelSpeeds m114 : 18|1@1+ (1,0) [0|1] "" Vector__XXX
 SG_ VCFRONT_a114_CH_wheelSpeeds m114 : 19|1@1+ (1,0) [0|1] "" Vector__XXX
 SG_ VCFRONT_a114_PARTY_party3 m114 : 20|1@1+ (1,0) [0|1] "" Vector__XXX
 SG_ VCFRONT_a114_VEH_party3 m114 : 21|1@1+ (1,0) [0|1] "" Vector__XXX
 SG_ VCFRONT_a114_VEH_status m114 : 22|1@1+ (1,0) [0|1] "" Vector__XXX
 SG_ VCFRONT_a114_PARTY_wheelRotation m114 : 23|1@1+ (1,0) [0|1] "" Vector__XXX
 SG_ VCFRONT_a114_CH_wheelRotation m114 : 24|1@1+ (1,0) [0|1] "" Vector__XXX
 SG_ VCFRONT_a114_VEH_wheelRotation m114 : 25|1@1+ (1,0) [0|1] "" Vector__XXX
 SG_ VCFRONT_a114_PARTY_brakeTorque m114 : 26|1@1+ (1,0) [0|1] "" Vector__XXX
 SG_ VCFRONT_a114_PARTY_offsets m114 : 27|1@1+ (1,0) [0|1] "" Vector__XXX
 SG_ VCFRONT_a114_BDY_offsets m114 : 28|1@1+ (1,0) [0|1] "" Vector__XXX
 SG_ VCFRONT_a114_BDY_party3 m114 : 29|1@1+ (1,0) [0|1] "" Vector__XXX
 SG_ VCFRONT_a114_BDY_status m114 : 30|1@1+ (1,0) [0|1] "" Vector__XXX
 SG_ VCFRONT_a114_BDY_wheelRotation m114 : 31|1@1+ (1,0) [0|1] "" Vector__XXX
 SG_ VCFRONT_a114_BDY_wheelSpeeds m114 : 32|1@1+ (1,0) [0|1] "" Vector__XXX
 SG_ VCFRONT_a114_CH_party1 m114 : 33|1@1+ (1,0) [0|1] "" Vector__XXX
 SG_ VCFRONT_a114_CH_party3 m114 : 34|1@1+ (1,0) [0|1] "" Vector__XXX
 SG_ VCFRONT_a114_CH_status m114 : 35|1@1+ (1,0) [0|1] "" Vector__XXX
 SG_ VCFRONT_a115_VEH_vehNm m115 : 16|1@1+ (1,0) [0|1] "" Vector__XXX
 SG_ VCFRONT_a115_VEH_authentication m115 : 17|1@1+ (1,0) [0|1] "" Vector__XXX
 SG_ VCFRONT_a115_VEH_BLEResetRequest m115 : 18|1@1+ (1,0) [0|1] "" Vector__XXX
 SG_ VCFRONT_a115_VEH_requests m115 : 19|1@1+ (1,0) [0|1] "" Vector__XXX
 SG_ VCFRONT_a115_VEH_requests2 m115 : 20|1@1+ (1,0) [0|1] "" Vector__XXX
 SG_ VCFRONT_a115_REM_authentication m115 : 21|1@1+ (1,0) [0|1] "" Vector__XXX
 SG_ VCFRONT_a115_UI_corianderVehicle m115 : 22|1@1+ (1,0) [0|1] "" Vector__XXX
 SG_ VCFRONT_a115_CH_TPMSDisplay m115 : 23|1@1+ (1,0) [0|1] "" Vector__XXX
 SG_ VCFRONT_a116_PARTY_epbmStatus m116 : 16|1@1+ (1,0) [0|1] "" Vector__XXX
 SG_ VCFRONT_a116_VEH_vehNm m116 : 17|1@1+ (1,0) [0|1] "" Vector__XXX
 SG_ VCFRONT_a116_VEH_hvacRequest m116 : 18|1@1+ (1,0) [0|1] "" Vector__XXX
 SG_ VCFRONT_a116_VEH_hvacStatus m116 : 19|1@1+ (1,0) [0|1] "" Vector__XXX
 SG_ VCFRONT_a116_VEH_LVPowerState m116 : 20|1@1+ (1,0) [0|1] "" Vector__XXX
 SG_ VCFRONT_a116_VEH_lightStatus m116 : 21|1@1+ (1,0) [0|1] "" Vector__XXX
 SG_ VCFRONT_a116_VEH_seatStatus m116 : 22|1@1+ (1,0) [0|1] "" Vector__XXX
 SG_ VCFRONT_a116_VEH_thsStatus m116 : 23|1@1+ (1,0) [0|1] "" Vector__XXX
 SG_ VCFRONT_a116_VEH_doorStatus m116 : 24|1@1+ (1,0) [0|1] "" Vector__XXX
 SG_ VCFRONT_a116_VEH_seatHeatStatus m116 : 25|1@1+ (1,0) [0|1] "" Vector__XXX
 SG_ VCFRONT_a116_VEH_restraintStatus m116 : 26|1@1+ (1,0) [0|1] "" Vector__XXX
 SG_ VCFRONT_a116_VEH_switchStatus m116 : 27|1@1+ (1,0) [0|1] "" Vector__XXX
 SG_ VCFRONT_a116_VEH_logging1Hz m116 : 28|1@1+ (1,0) [0|1] "" Vector__XXX
 SG_ VCFRONT_a116_VEH_seatStatus2 m116 : 29|1@1+ (1,0) [0|1] "" Vector__XXX
 SG_ VCFRONT_a116_VEH_status m116 : 30|1@1+ (1,0) [0|1] "" Vector__XXX
 SG_ VCFRONT_a116_VEH_thermalCommand m116 : 31|1@1+ (1,0) [0|1] "" Vector__XXX
 SG_ VCFRONT_a116_VEH_windowStatus m116 : 32|1@1+ (1,0) [0|1] "" Vector__XXX
 SG_ VCFRONT_a116_PARTY_restraintStat m116 : 33|1@1+ (1,0) [0|1] "" Vector__XXX
 SG_ VCFRONT_a116_PARTY_doorStatus m116 : 34|1@1+ (1,0) [0|1] "" Vector__XXX
 SG_ VCFRONT_a116_BDY_epbmStatus m116 : 35|1@1+ (1,0) [0|1] "" Vector__XXX
 SG_ VCFRONT_a116_BDY_restraintStatus m116 : 36|1@1+ (1,0) [0|1] "" Vector__XXX
 SG_ VCFRONT_a117_BDY_epbmStatus m117 : 16|1@1+ (1,0) [0|1] "" Vector__XXX
 SG_ VCFRONT_a117_BDY_restraintStatus m117 : 17|1@1+ (1,0) [0|1] "" Vector__XXX
 SG_ VCFRONT_a117_VEH_prndStatus m117 : 18|1@1+ (1,0) [0|1] "" Vector__XXX
 SG_ VCFRONT_a117_PARTY_epbmStatus m117 : 19|1@1+ (1,0) [0|1] "" Vector__XXX
 SG_ VCFRONT_a117_VEH_vehNm m117 : 20|1@1+ (1,0) [0|1] "" Vector__XXX
 SG_ VCFRONT_a117_VEH_hvacBlowerFdb m117 : 21|1@1+ (1,0) [0|1] "" Vector__XXX
 SG_ VCFRONT_a117_VEH_LVPowerState m117 : 22|1@1+ (1,0) [0|1] "" Vector__XXX
 SG_ VCFRONT_a117_VEH_restraintStatus m117 : 23|1@1+ (1,0) [0|1] "" Vector__XXX
 SG_ VCFRONT_a117_VEH_lightStatus m117 : 24|1@1+ (1,0) [0|1] "" Vector__XXX
 SG_ VCFRONT_a117_VEH_seatStatus m117 : 25|1@1+ (1,0) [0|1] "" Vector__XXX
 SG_ VCFRONT_a117_BDY_falconSwitchSta m117 : 26|1@1+ (1,0) [0|1] "" Vector__XXX
 SG_ VCFRONT_a117_VEH_doorStatus m117 : 27|1@1+ (1,0) [0|1] "" Vector__XXX
 SG_ VCFRONT_a117_VEH_doorStatus2 m117 : 28|1@1+ (1,0) [0|1] "" Vector__XXX
 SG_ VCFRONT_a117_VEH_windowStatus m117 : 29|1@1+ (1,0) [0|1] "" Vector__XXX
 SG_ VCFRONT_a117_VEH_switchStatus m117 : 30|1@1+ (1,0) [0|1] "" Vector__XXX
 SG_ VCFRONT_a117_VEH_intrusionSensor m117 : 31|1@1+ (1,0) [0|1] "" Vector__XXX
 SG_ VCFRONT_a117_VEH_liftgateStatus m117 : 32|1@1+ (1,0) [0|1] "" Vector__XXX
 SG_ VCFRONT_a117_VEH_seatStatus2 m117 : 33|1@1+ (1,0) [0|1] "" Vector__XXX
 SG_ VCFRONT_a117_PARTY_restraintStat m117 : 34|1@1+ (1,0) [0|1] "" Vector__XXX
 SG_ VCFRONT_a117_VEH_thermalStatus m117 : 35|1@1+ (1,0) [0|1] "" Vector__XXX
 SG_ VCFRONT_a117_PARTY_doorStatus m117 : 36|1@1+ (1,0) [0|1] "" Vector__XXX
 SG_ VCFRONT_a117_VEH_status m117 : 37|1@1+ (1,0) [0|1] "" Vector__XXX
 SG_ VCFRONT_a117_PARTY_prndStatus m117 : 38|1@1+ (1,0) [0|1] "" Vector__XXX
 SG_ VCFRONT_a118_VEH_vehNm m118 : 16|1@1+ (1,0) [0|1] "" Vector__XXX
 SG_ VCFRONT_a118_VEH_lighting m118 : 17|1@1+ (1,0) [0|1] "" Vector__XXX
 SG_ VCFRONT_a118_VEH_sensors m118 : 18|1@1+ (1,0) [0|1] "" Vector__XXX
 SG_ VCFRONT_a118_VEH_status m118 : 19|1@1+ (1,0) [0|1] "" Vector__XXX
 SG_ VCFRONT_a118_VEH_okToUseHighPwr m118 : 20|1@1+ (1,0) [0|1] "" Vector__XXX
 SG_ VCFRONT_a118_VEH_LVPowerState m118 : 21|1@1+ (1,0) [0|1] "" Vector__XXX
 SG_ VCFRONT_a118_VEH_coolant m118 : 22|1@1+ (1,0) [0|1] "" Vector__XXX
 SG_ VCFRONT_a118_VEH_vehicleStatus m118 : 23|1@1+ (1,0) [0|1] "" Vector__XXX
 SG_ VCFRONT_a118_VEH_12VBatteryStatu m118 : 24|1@1+ (1,0) [0|1] "" Vector__XXX
 SG_ VCFRONT_a118_VEH_systemStatus m118 : 25|1@1+ (1,0) [0|1] "" Vector__XXX
 SG_ VCFRONT_a118_PARTY_LVPowerState m118 : 26|1@1+ (1,0) [0|1] "" Vector__XXX
 SG_ VCFRONT_a118_PARTY_outputPowerSt m118 : 27|1@1+ (1,0) [0|1] "" Vector__XXX
 SG_ VCFRONT_a118_PARTY_vehicleTime m118 : 28|1@1+ (1,0) [0|1] "" Vector__XXX
 SG_ VCFRONT_a118_VEH_thermalCommand m118 : 29|1@1+ (1,0) [0|1] "" Vector__XXX
 SG_ VCFRONT_a118_CH_LVPowerState m118 : 30|1@1+ (1,0) [0|1] "" Vector__XXX
 SG_ VCFRONT_a118_PARTY_sensors m118 : 31|1@1+ (1,0) [0|1] "" Vector__XXX
 SG_ VCFRONT_a118_CH_sensors m118 : 32|1@1+ (1,0) [0|1] "" Vector__XXX
 SG_ VCFRONT_a118_VEH_interNodeResist m118 : 33|1@1+ (1,0) [0|1] "" Vector__XXX
 SG_ VCFRONT_a118_CH_lighting m118 : 34|1@1+ (1,0) [0|1] "" Vector__XXX
 SG_ VCFRONT_a118_VEH_lightStatus m118 : 35|1@1+ (1,0) [0|1] "" Vector__XXX
 SG_ VCFRONT_a118_PARTY_vehNm m118 : 36|1@1+ (1,0) [0|1] "" Vector__XXX
 SG_ VCFRONT_a118_CH_12VBatteryStatus m118 : 37|1@1+ (1,0) [0|1] "" Vector__XXX
 SG_ VCFRONT_a118_CH_LVBMS_statusHigh m118 : 38|1@1+ (1,0) [0|1] "" Vector__XXX
 SG_ VCFRONT_a118_CH_alertMatrix m118 : 39|1@1+ (1,0) [0|1] "" Vector__XXX
 SG_ VCFRONT_a118_BDY_outputPowerStat m118 : 40|1@1+ (1,0) [0|1] "" Vector__XXX
 SG_ VCFRONT_a118_BDY_vehicleTime m118 : 41|1@1+ (1,0) [0|1] "" Vector__XXX
 SG_ VCFRONT_a118_PARTY_AP_vehicleSta m118 : 42|1@1+ (1,0) [0|1] "" Vector__XXX
 SG_ VCFRONT_a118_BDY_AP_vehicleState m118 : 43|1@1+ (1,0) [0|1] "" Vector__XXX
 SG_ VCFRONT_a119_VEH_steerAngle m119 : 16|1@1+ (1,0) [0|1] "" Vector__XXX
 SG_ VCFRONT_a119_VEH_leftStalk m119 : 17|1@1+ (1,0) [0|1] "" Vector__XXX
 SG_ VCFRONT_a119_VEH_rightStalk m119 : 18|1@1+ (1,0) [0|1] "" Vector__XXX
 SG_ VCFRONT_a119_PARTY_rightStalk m119 : 19|1@1+ (1,0) [0|1] "" Vector__XXX
 SG_ VCFRONT_a119_CH_steerAngle m119 : 20|1@1+ (1,0) [0|1] "" Vector__XXX
 SG_ VCFRONT_a119_PARTY_steerAngle m119 : 21|1@1+ (1,0) [0|1] "" Vector__XXX
 SG_ VCFRONT_a120_PARTY_chassisCntl m120 : 16|1@1+ (1,0) [0|1] "" Vector__XXX
 SG_ VCFRONT_a120_VEH_systemStatus m120 : 17|1@1+ (1,0) [0|1] "" Vector__XXX
 SG_ VCFRONT_a120_CH_chassisCntl m120 : 18|1@1+ (1,0) [0|1] "" Vector__XXX
 SG_ VCFRONT_a120_PARTY_systemStatus m120 : 19|1@1+ (1,0) [0|1] "" Vector__XXX
 SG_ VCFRONT_a120_PARTY_torque m120 : 20|1@1+ (1,0) [0|1] "" Vector__XXX
 SG_ VCFRONT_a120_VEH_torque m120 : 21|1@1+ (1,0) [0|1] "" Vector__XXX
 SG_ VCFRONT_a120_PARTY_locStatus m120 : 22|1@1+ (1,0) [0|1] "" Vector__XXX
 SG_ VCFRONT_a120_PARTY_speed m120 : 23|1@1+ (1,0) [0|1] "" Vector__XXX
 SG_ VCFRONT_a120_VEH_speed m120 : 24|1@1+ (1,0) [0|1] "" Vector__XXX
 SG_ VCFRONT_a120_PARTY_status m120 : 25|1@1+ (1,0) [0|1] "" Vector__XXX
 SG_ VCFRONT_a120_PT_speed m120 : 26|1@1+ (1,0) [0|1] "" Vector__XXX
 SG_ VCFRONT_a120_PT_systemStatus m120 : 27|1@1+ (1,0) [0|1] "" Vector__XXX
 SG_ VCFRONT_a120_PARTY_vehicleEstima m120 : 28|1@1+ (1,0) [0|1] "" Vector__XXX
 SG_ VCFRONT_a120_VEH_aggregatedAxleS m120 : 29|1@1+ (1,0) [0|1] "" Vector__XXX
 SG_ VCFRONT_a120_PARTY_aggregatedAxl m120 : 30|1@1+ (1,0) [0|1] "" Vector__XXX
 SG_ VCFRONT_a120_VEH_systemPower m120 : 31|1@1+ (1,0) [0|1] "" Vector__XXX
 SG_ VCFRONT_a120_PT_systemPower m120 : 32|1@1+ (1,0) [0|1] "" Vector__XXX
 SG_ VCFRONT_a120_PARTY_stalklessInte m120 : 33|1@1+ (1,0) [0|1] "" Vector__XXX
 SG_ VCFRONT_a120_CH_speed m120 : 34|1@1+ (1,0) [0|1] "" Vector__XXX
 SG_ VCFRONT_a120_VEH_estimatedBrakeT m120 : 35|1@1+ (1,0) [0|1] "" Vector__XXX
 SG_ VCFRONT_a120_PARTY_prndControl m120 : 36|1@1+ (1,0) [0|1] "" Vector__XXX
 SG_ VCFRONT_a120_PARTY_locStatus2 m120 : 37|1@1+ (1,0) [0|1] "" Vector__XXX
 SG_ VCFRONT_a120_VEH_chassisCntl m120 : 38|1@1+ (1,0) [0|1] "" Vector__XXX
 SG_ VCFRONT_a120_VEH_locStatus m120 : 39|1@1+ (1,0) [0|1] "" Vector__XXX
 SG_ VCFRONT_a120_VEH_locStatus2 m120 : 40|1@1+ (1,0) [0|1] "" Vector__XXX
 SG_ VCFRONT_a120_VEH_prndControl m120 : 41|1@1+ (1,0) [0|1] "" Vector__XXX
 SG_ VCFRONT_a120_VEH_vehicleEstimate m120 : 42|1@1+ (1,0) [0|1] "" Vector__XXX
 SG_ VCFRONT_a121_overCurrentError m121 : 16|1@1+ (1,0) [0|1] "" Vector__XXX
 SG_ VCFRONT_a121_fetShortCircuit m121 : 17|1@1+ (1,0) [0|1] "" Vector__XXX
 SG_ VCFRONT_a121_lockedRotor m121 : 18|1@1+ (1,0) [0|1] "" Vector__XXX
 SG_ VCFRONT_a122_junctionTempWarning m122 : 16|1@1+ (1,0) [0|1] "" Vector__XXX
 SG_ VCFRONT_a122_junctionOverTemp m122 : 17|1@1+ (1,0) [0|1] "" Vector__XXX
 SG_ VCFRONT_a122_startUpOperation m122 : 18|1@1+ (1,0) [0|1] "" Vector__XXX
 SG_ VCFRONT_a122_lossOfSpeedLock m122 : 19|1@1+ (1,0) [0|1] "" Vector__XXX
 SG_ VCFRONT_a122_vccUnderVoltage m122 : 20|1@1+ (1,0) [0|1] "" Vector__XXX
 SG_ VCFRONT_a123_overCurrentError m123 : 16|1@1+ (1,0) [0|1] "" Vector__XXX
 SG_ VCFRONT_a123_fetShortCircuit m123 : 17|1@1+ (1,0) [0|1] "" Vector__XXX
 SG_ VCFRONT_a123_lockedRotor m123 : 18|1@1+ (1,0) [0|1] "" Vector__XXX
 SG_ VCFRONT_a124_junctionTempWarning m124 : 16|1@1+ (1,0) [0|1] "" Vector__XXX
 SG_ VCFRONT_a124_junctionOverTemp m124 : 17|1@1+ (1,0) [0|1] "" Vector__XXX
 SG_ VCFRONT_a124_startUpOperation m124 : 18|1@1+ (1,0) [0|1] "" Vector__XXX
 SG_ VCFRONT_a124_lossOfSpeedLock m124 : 19|1@1+ (1,0) [0|1] "" Vector__XXX
 SG_ VCFRONT_a124_vccUnderVoltage m124 : 20|1@1+ (1,0) [0|1] "" Vector__XXX
 SG_ VCFRONT_a125_overCurrentError m125 : 16|1@1+ (1,0) [0|1] "" Vector__XXX
 SG_ VCFRONT_a125_fetShortCircuit m125 : 17|1@1+ (1,0) [0|1] "" Vector__XXX
 SG_ VCFRONT_a125_lockedRotor m125 : 18|1@1+ (1,0) [0|1] "" Vector__XXX
 SG_ VCFRONT_a126_junctionTempWarning m126 : 16|1@1+ (1,0) [0|1] "" Vector__XXX
 SG_ VCFRONT_a126_junctionOverTemp m126 : 17|1@1+ (1,0) [0|1] "" Vector__XXX
 SG_ VCFRONT_a126_startUpOperation m126 : 18|1@1+ (1,0) [0|1] "" Vector__XXX
 SG_ VCFRONT_a126_lossOfSpeedLock m126 : 19|1@1+ (1,0) [0|1] "" Vector__XXX
 SG_ VCFRONT_a126_vccUnderVoltage m126 : 20|1@1+ (1,0) [0|1] "" Vector__XXX
 SG_ VCFRONT_a127_vcleftEFuseCurrent m127 : 16|16@1+ (0.1,0) [0|6553.5] "" Vector__XXX
 SG_ VCFRONT_a127_vcleftEFuseVoltage m127 : 32|16@1+ (0.1,0) [0|6553.5] "" Vector__XXX
 SG_ VCFRONT_a127_vcleftEFuseTemp m127 : 48|11@1+ (0.125,-40) [-40|215.875] "" Vector__XXX
 SG_ VCFRONT_a127_vcleftEFuseRemainin m127 : 59|4@1+ (1,0) [0|15] "" Vector__XXX
 SG_ VCFRONT_a128_vcrightEFuseCurrent m128 : 16|16@1+ (0.1,0) [0|6553.5] "" Vector__XXX
 SG_ VCFRONT_a128_vcrightEFuseVoltage m128 : 32|16@1+ (0.1,0) [0|6553.5] "" Vector__XXX
 SG_ VCFRONT_a128_vcrightEFuseTemp m128 : 48|11@1+ (0.125,-40) [-40|215.875] "" Vector__XXX
 SG_ VCFRONT_a128_vcrightEFuseRemaini m128 : 59|4@1+ (1,0) [0|15] "" Vector__XXX
 SG_ VCFRONT_a129_pcsEFuseCurrent m129 : 16|16@1+ (0.1,0) [0|6553.5] "" Vector__XXX
 SG_ VCFRONT_a129_pcsEFuseVoltage m129 : 32|16@1+ (0.1,0) [0|6553.5] "" Vector__XXX
 SG_ VCFRONT_a129_pcsEFuseTemp m129 : 48|11@1+ (0.125,-40) [-40|215.875] "" Vector__XXX
 SG_ VCFRONT_a129_pcsEFuseRemainingRe m129 : 59|4@1+ (1,0) [0|15] "" Vector__XXX
 SG_ VCFRONT_a130_epas3pEFuseCurrent m130 : 16|16@1+ (0.1,0) [0|6553.5] "" Vector__XXX
 SG_ VCFRONT_a130_epas3pEFuseVoltage m130 : 32|16@1+ (0.1,0) [0|6553.5] "" Vector__XXX
 SG_ VCFRONT_a130_epas3pEFuseTemp m130 : 48|11@1+ (0.125,-40) [-40|215.875] "" Vector__XXX
 SG_ VCFRONT_a131_epas3sEFuseCurrent m131 : 16|16@1+ (0.1,0) [0|6553.5] "" Vector__XXX
 SG_ VCFRONT_a131_epas3sEFuseVoltage m131 : 32|16@1+ (0.1,0) [0|6553.5] "" Vector__XXX
 SG_ VCFRONT_a131_epas3sEFuseTemp m131 : 48|11@1+ (0.125,-40) [-40|215.875] "" Vector__XXX
 SG_ VCFRONT_a132_iBoosterCurrent m132 : 16|16@1+ (0.1,0) [0|6553.5] "" Vector__XXX
 SG_ VCFRONT_a132_iBoosterVoltage m132 : 32|16@1+ (0.1,0) [0|6553.5] "" Vector__XXX
 SG_ VCFRONT_a132_iBoosterEFuseTemp m132 : 48|11@1+ (0.125,-40) [-40|215.875] "" Vector__XXX
 SG_ VCFRONT_a133_espEFuseCurrent m133 : 16|16@1+ (0.1,0) [0|6553.5] "" Vector__XXX
 SG_ VCFRONT_a133_espEFuseVoltage m133 : 32|16@1+ (0.1,0) [0|6553.5] "" Vector__XXX
 SG_ VCFRONT_a133_espEFuseTemp m133 : 48|11@1+ (0.125,-40) [-40|215.875] "" Vector__XXX
 SG_ VCFRONT_a134_fusedHighCurrent m134 : 16|16@1+ (0.1,0) [0|6553.5] "" Vector__XXX
 SG_ VCFRONT_a134_fusedHighVoltage m134 : 32|16@1+ (0.1,0) [0|6553.5] "" Vector__XXX
 SG_ VCFRONT_a134_fusedHighTemp m134 : 48|11@1+ (0.125,-40) [-40|215.875] "" Vector__XXX
 SG_ VCFRONT_a134_vbatFusedEFuseRemai m134 : 59|4@1+ (1,0) [0|15] "" Vector__XXX
 SG_ VCFRONT_a136_snsShortCircuit m136 : 16|1@1+ (1,0) [0|1] "" Vector__XXX
 SG_ VCFRONT_a136_snsDisconnect m136 : 17|1@1+ (1,0) [0|1] "" Vector__XXX
 SG_ VCFRONT_a136_snsRateChangeUp m136 : 18|1@1+ (1,0) [0|1] "" Vector__XXX
 SG_ VCFRONT_a136_snsRateChangeDown m136 : 19|1@1+ (1,0) [0|1] "" Vector__XXX
 SG_ VCFRONT_a137_snsShortCircuit m137 : 16|1@1+ (1,0) [0|1] "" Vector__XXX
 SG_ VCFRONT_a137_snsDisconnect m137 : 17|1@1+ (1,0) [0|1] "" Vector__XXX
 SG_ VCFRONT_a137_snsRateChangeUp m137 : 18|1@1+ (1,0) [0|1] "" Vector__XXX
 SG_ VCFRONT_a137_snsRateChangeDown m137 : 19|1@1+ (1,0) [0|1] "" Vector__XXX
 SG_ VCFRONT_a138_snsShortCircuit m138 : 16|1@1+ (1,0) [0|1] "" Vector__XXX
 SG_ VCFRONT_a138_snsDisconnect m138 : 17|1@1+ (1,0) [0|1] "" Vector__XXX
 SG_ VCFRONT_a138_snsRateChangeUp m138 : 18|1@1+ (1,0) [0|1] "" Vector__XXX
 SG_ VCFRONT_a138_snsRateChangeDown m138 : 19|1@1+ (1,0) [0|1] "" Vector__XXX
 SG_ VCFRONT_a139_snsShortCircuit m139 : 16|1@1+ (1,0) [0|1] "" Vector__XXX
 SG_ VCFRONT_a139_snsDisconnect m139 : 17|1@1+ (1,0) [0|1] "" Vector__XXX
 SG_ VCFRONT_a139_snsRateChangeUp m139 : 18|1@1+ (1,0) [0|1] "" Vector__XXX
 SG_ VCFRONT_a139_snsRateChangeDown m139 : 19|1@1+ (1,0) [0|1] "" Vector__XXX
 SG_ VCFRONT_a140_snsShortCircuit m140 : 16|1@1+ (1,0) [0|1] "" Vector__XXX
 SG_ VCFRONT_a140_snsDisconnect m140 : 17|1@1+ (1,0) [0|1] "" Vector__XXX
 SG_ VCFRONT_a140_snsRateChangeUp m140 : 18|1@1+ (1,0) [0|1] "" Vector__XXX
 SG_ VCFRONT_a140_snsRateChangeDown m140 : 19|1@1+ (1,0) [0|1] "" Vector__XXX
 SG_ VCFRONT_a141_snsShortCircuit m141 : 16|1@1+ (1,0) [0|1] "" Vector__XXX
 SG_ VCFRONT_a141_snsDisconnect m141 : 17|1@1+ (1,0) [0|1] "" Vector__XXX
 SG_ VCFRONT_a141_snsRateChangeUp m141 : 18|1@1+ (1,0) [0|1] "" Vector__XXX
 SG_ VCFRONT_a141_snsRateChangeDown m141 : 19|1@1+ (1,0) [0|1] "" Vector__XXX
 SG_ VCFRONT_a142_driverState m142 : 16|4@1+ (1,0) [0|15] "" Vector__XXX
 SG_ VCFRONT_a142_driverThermWarn m142 : 20|1@1+ (1,0) [0|1] "" Vector__XXX
 SG_ VCFRONT_a142_driverThermShutdown m142 : 21|1@1+ (1,0) [0|1] "" Vector__XXX
 SG_ VCFRONT_a142_undervoltage m142 : 22|1@1+ (1,0) [0|1] "" Vector__XXX
 SG_ VCFRONT_a142_chargePumpUndervolt m142 : 23|1@1+ (1,0) [0|1] "" Vector__XXX
 SG_ VCFRONT_a142_isCoilOpenX m142 : 24|1@1+ (1,0) [0|1] "" Vector__XXX
 SG_ VCFRONT_a142_isCoilOpenY m142 : 25|1@1+ (1,0) [0|1] "" Vector__XXX
 SG_ VCFRONT_a142_isCoilShortXPGnd m142 : 26|1@1+ (1,0) [0|1] "" Vector__XXX
 SG_ VCFRONT_a142_isCoilShortXPVbb m142 : 27|1@1+ (1,0) [0|1] "" Vector__XXX
 SG_ VCFRONT_a142_isCoilShortXNGnd m142 : 28|1@1+ (1,0) [0|1] "" Vector__XXX
 SG_ VCFRONT_a142_isCoilShortXNVbb m142 : 29|1@1+ (1,0) [0|1] "" Vector__XXX
 SG_ VCFRONT_a142_isCoilShortYPGnd m142 : 30|1@1+ (1,0) [0|1] "" Vector__XXX
 SG_ VCFRONT_a142_isCoilShortYPVbb m142 : 31|1@1+ (1,0) [0|1] "" Vector__XXX
 SG_ VCFRONT_a142_isCoilShortYNGnd m142 : 32|1@1+ (1,0) [0|1] "" Vector__XXX
 SG_ VCFRONT_a142_isCoilShortYNVbb m142 : 33|1@1+ (1,0) [0|1] "" Vector__XXX
 SG_ VCFRONT_a142_driverHasCommError m142 : 34|1@1+ (1,0) [0|1] "" Vector__XXX
 SG_ VCFRONT_a143_vsUnderVoltage m143 : 16|1@1+ (1,0) [0|1] "" Vector__XXX
 SG_ VCFRONT_a143_vsOverVoltage m143 : 17|1@1+ (1,0) [0|1] "" Vector__XXX
 SG_ VCFRONT_a143_chpUnderVoltage m143 : 18|1@1+ (1,0) [0|1] "" Vector__XXX
 SG_ VCFRONT_a143_vglUnderVoltage m143 : 19|1@1+ (1,0) [0|1] "" Vector__XXX
 SG_ VCFRONT_a143_thOverTemperature m143 : 20|1@1+ (1,0) [0|1] "" Vector__XXX
 SG_ VCFRONT_a144_vsUnderVoltage m144 : 16|1@1+ (1,0) [0|1] "" Vector__XXX
 SG_ VCFRONT_a144_vsOverVoltage m144 : 17|1@1+ (1,0) [0|1] "" Vector__XXX
 SG_ VCFRONT_a144_chpUnderVoltage m144 : 18|1@1+ (1,0) [0|1] "" Vector__XXX
 SG_ VCFRONT_a144_vglUnderVoltage m144 : 19|1@1+ (1,0) [0|1] "" Vector__XXX
 SG_ VCFRONT_a144_thOverTemperature m144 : 20|1@1+ (1,0) [0|1] "" Vector__XXX
 SG_ VCFRONT_a145_vsUnderVoltage m145 : 16|1@1+ (1,0) [0|1] "" Vector__XXX
 SG_ VCFRONT_a145_vsOverVoltage m145 : 17|1@1+ (1,0) [0|1] "" Vector__XXX
 SG_ VCFRONT_a145_chpUnderVoltage m145 : 18|1@1+ (1,0) [0|1] "" Vector__XXX
 SG_ VCFRONT_a145_vglUnderVoltage m145 : 19|1@1+ (1,0) [0|1] "" Vector__XXX
 SG_ VCFRONT_a145_thOverTemperature m145 : 20|1@1+ (1,0) [0|1] "" Vector__XXX
 SG_ VCFRONT_a146_RPMActual m146 : 16|10@1+ (10,0) [0|10230] "" Vector__XXX
 SG_ VCFRONT_a146_RPMTarget m146 : 26|10@1+ (10,0) [0|10230] "" Vector__XXX
 SG_ VCFRONT_a147_RPMActual m147 : 16|10@1+ (10,0) [0|10230] "" Vector__XXX
 SG_ VCFRONT_a147_RPMTarget m147 : 26|10@1+ (10,0) [0|10230] "" Vector__XXX
 SG_ VCFRONT_a148_RPMActual m148 : 16|10@1+ (10,0) [0|10230] "" Vector__XXX
 SG_ VCFRONT_a148_RPMTarget m148 : 26|10@1+ (10,0) [0|10230] "" Vector__XXX
 SG_ VCFRONT_a150_RPMActual m150 : 16|10@1+ (10,0) [0|10230] "" Vector__XXX
 SG_ VCFRONT_a150_RPMTarget m150 : 26|10@1+ (10,0) [0|10230] "" Vector__XXX
 SG_ VCFRONT_a151_RPMActual m151 : 16|10@1+ (10,0) [0|10230] "" Vector__XXX
 SG_ VCFRONT_a151_RPMTarget m151 : 26|10@1+ (10,0) [0|10230] "" Vector__XXX
 SG_ VCFRONT_a152_RPMActual m152 : 16|10@1+ (10,0) [0|10230] "" Vector__XXX
 SG_ VCFRONT_a152_RPMTarget m152 : 26|10@1+ (10,0) [0|10230] "" Vector__XXX
 SG_ VCFRONT_a156_motorCounts m156 : 16|11@1+ (1,-100) [-100|1947] "" Vector__XXX
 SG_ VCFRONT_a157_motorCounts m157 : 16|11@1+ (1,-100) [-100|1947] "" Vector__XXX
 SG_ VCFRONT_a159_stall m159 : 16|1@1+ (1,0) [0|1] "" Vector__XXX
 SG_ VCFRONT_a159_angleActual m159 : 17|10@1+ (0.25,-70) [-70|185.75] "" Vector__XXX
 SG_ VCFRONT_a159_angleTarget m159 : 27|10@1+ (0.25,-10) [-10|245.75] "" Vector__XXX
 SG_ VCFRONT_a160_highDischTemp m160 : 16|1@1+ (1,0) [0|1] "" Vector__XXX
 SG_ VCFRONT_a160_lowDischPressure m160 : 17|1@1+ (1,0) [0|1] "" Vector__XXX
 SG_ VCFRONT_a160_highDischPressure m160 : 18|1@1+ (1,0) [0|1] "" Vector__XXX
 SG_ VCFRONT_a160_lowSuctionPressure m160 : 19|1@1+ (1,0) [0|1] "" Vector__XXX
 SG_ VCFRONT_a160_faultSnsDischPress m160 : 20|1@1+ (1,0) [0|1] "" Vector__XXX
 SG_ VCFRONT_a160_faultSnsDischTemp m160 : 21|1@1+ (1,0) [0|1] "" Vector__XXX
 SG_ VCFRONT_a160_faultSnsSuctPress m160 : 22|1@1+ (1,0) [0|1] "" Vector__XXX
 SG_ VCFRONT_a160_faultSnsSuctTemp m160 : 23|1@1+ (1,0) [0|1] "" Vector__XXX
 SG_ VCFRONT_a160_faultSnsAmbientTemp m160 : 24|1@1+ (1,0) [0|1] "" Vector__XXX
 SG_ VCFRONT_a160_faultValveEXV m160 : 25|1@1+ (1,0) [0|1] "" Vector__XXX
 SG_ VCFRONT_a160_faultValveEvapSol m160 : 26|1@1+ (1,0) [0|1] "" Vector__XXX
 SG_ VCFRONT_a160_highDischargePressu m160 : 27|1@1+ (1,0) [0|1] "" Vector__XXX
 SG_ VCFRONT_a160_highDischargeTempCu m160 : 28|1@1+ (1,0) [0|1] "" Vector__XXX
 SG_ VCFRONT_a160_compressorRpm m160 : 32|7@1+ (90,0) [0|11430] "" Vector__XXX
 SG_ VCFRONT_a161_failedStart m161 : 16|1@1+ (1,0) [0|1] "" Vector__XXX
 SG_ VCFRONT_a161_HVOverVoltage m161 : 17|1@1+ (1,0) [0|1] "" Vector__XXX
 SG_ VCFRONT_a161_HVUnderVoltage m161 : 18|1@1+ (1,0) [0|1] "" Vector__XXX
 SG_ VCFRONT_a161_overCurrent m161 : 19|1@1+ (1,0) [0|1] "" Vector__XXX
 SG_ VCFRONT_a161_overTemperature m161 : 20|1@1+ (1,0) [0|1] "" Vector__XXX
 SG_ VCFRONT_a161_shortCircuit m161 : 21|1@1+ (1,0) [0|1] "" Vector__XXX
 SG_ VCFRONT_a161_underTemperature m161 : 22|1@1+ (1,0) [0|1] "" Vector__XXX
 SG_ VCFRONT_a161_LVUnderVoltage m161 : 23|1@1+ (1,0) [0|1] "" Vector__XXX
 SG_ VCFRONT_a161_LVOverVoltage m161 : 24|1@1+ (1,0) [0|1] "" Vector__XXX
 SG_ VCFRONT_a161_tempSnsFaultIPM1 m161 : 25|1@1+ (1,0) [0|1] "" Vector__XXX
 SG_ VCFRONT_a161_tempSnsFaultIPM2 m161 : 26|1@1+ (1,0) [0|1] "" Vector__XXX
 SG_ VCFRONT_a161_tempSnsFaultCPU m161 : 27|1@1+ (1,0) [0|1] "" Vector__XXX
 SG_ VCFRONT_a161_currentSnsError m161 : 28|1@1+ (1,0) [0|1] "" Vector__XXX
 SG_ VCFRONT_a161_selfTestFailCPU m161 : 29|1@1+ (1,0) [0|1] "" Vector__XXX
 SG_ VCFRONT_a161_internalPowerSupply m161 : 30|1@1+ (1,0) [0|1] "" Vector__XXX
 SG_ VCFRONT_a161_inverterOpenCircuit m161 : 31|1@1+ (1,0) [0|1] "" Vector__XXX
 SG_ VCFRONT_a161_warnOverTemperature m161 : 32|1@1+ (1,0) [0|1] "" Vector__XXX
 SG_ VCFRONT_a161_failedStartRepeated m161 : 33|1@1+ (1,0) [0|1] "" Vector__XXX
 SG_ VCFRONT_a161_overload m161 : 34|1@1+ (1,0) [0|1] "" Vector__XXX
 SG_ VCFRONT_a162_dischargePressure m162 : 16|6@1+ (0.5,0) [0|31.5] "" Vector__XXX
 SG_ VCFRONT_a162_chillerExvFlow m162 : 22|7@1+ (1,0) [0|127] "" Vector__XXX
 SG_ VCFRONT_a162_lccExvFlow m162 : 29|7@1+ (1,0) [0|127] "" Vector__XXX
 SG_ VCFRONT_a162_ccLeftExvFlow m162 : 36|7@1+ (1,0) [0|127] "" Vector__XXX
 SG_ VCFRONT_a162_ccRightExvFlow m162 : 43|7@1+ (1,0) [0|127] "" Vector__XXX
 SG_ VCFRONT_a162_evapExvFlow m162 : 50|7@1+ (1,0) [0|127] "" Vector__XXX
 SG_ VCFRONT_a162_recircExvFlow m162 : 57|7@1+ (1,0) [0|127] "" Vector__XXX
 SG_ VCFRONT_a164_lockoutVoltage m164 : 16|16@1+ (0.1,0) [0|6553.5] "" Vector__XXX
 SG_ VCFRONT_a165_lockoutVoltage m165 : 16|16@1+ (0.1,0) [0|6553.5] "" Vector__XXX
 SG_ VCFRONT_a168_leftECU m168 : 16|1@1+ (1,0) [0|1] "" Vector__XXX
 SG_ VCFRONT_a168_rightECU m168 : 17|1@1+ (1,0) [0|1] "" Vector__XXX
 SG_ VCFRONT_a169_leftECU m169 : 16|1@1+ (1,0) [0|1] "" Vector__XXX
 SG_ VCFRONT_a169_rightECU m169 : 17|1@1+ (1,0) [0|1] "" Vector__XXX
 SG_ VCFRONT_a170_leftECU m170 : 16|1@1+ (1,0) [0|1] "" Vector__XXX
 SG_ VCFRONT_a170_rightECU m170 : 17|1@1+ (1,0) [0|1] "" Vector__XXX
 SG_ VCFRONT_a171_VCFRONT m171 : 16|1@1+ (1,0) [0|1] "" Vector__XXX
 SG_ VCFRONT_a171_VCRIGHT m171 : 17|1@1+ (1,0) [0|1] "" Vector__XXX
 SG_ VCFRONT_a171_VCLEFT m171 : 18|1@1+ (1,0) [0|1] "" Vector__XXX
 SG_ VCFRONT_a171_BMS m171 : 19|1@1+ (1,0) [0|1] "" Vector__XXX
 SG_ VCFRONT_a171_HVP m171 : 20|1@1+ (1,0) [0|1] "" Vector__XXX
 SG_ VCFRONT_a171_GTW m171 : 21|1@1+ (1,0) [0|1] "" Vector__XXX
 SG_ VCFRONT_a171_CP m171 : 22|1@1+ (1,0) [0|1] "" Vector__XXX
 SG_ VCFRONT_a171_PCS m171 : 23|1@1+ (1,0) [0|1] "" Vector__XXX
 SG_ VCFRONT_a171_PCSCPU2 m171 : 24|1@1+ (1,0) [0|1] "" Vector__XXX
 SG_ VCFRONT_a171_DI m171 : 25|1@1+ (1,0) [0|1] "" Vector__XXX
 SG_ VCFRONT_a171_DIS m171 : 26|1@1+ (1,0) [0|1] "" Vector__XXX
 SG_ VCFRONT_a171_PM m171 : 27|1@1+ (1,0) [0|1] "" Vector__XXX
 SG_ VCFRONT_a171_PMS m171 : 28|1@1+ (1,0) [0|1] "" Vector__XXX
 SG_ VCFRONT_a171_EPBR m171 : 29|1@1+ (1,0) [0|1] "" Vector__XXX
 SG_ VCFRONT_a171_EPBL m171 : 30|1@1+ (1,0) [0|1] "" Vector__XXX
 SG_ VCFRONT_a171_IBST m171 : 31|1@1+ (1,0) [0|1] "" Vector__XXX
 SG_ VCFRONT_a171_IBSTCAL m171 : 32|1@1+ (1,0) [0|1] "" Vector__XXX
 SG_ VCFRONT_a171_ESP m171 : 33|1@1+ (1,0) [0|1] "" Vector__XXX
 SG_ VCFRONT_a171_ESPCAL m171 : 34|1@1+ (1,0) [0|1] "" Vector__XXX
 SG_ VCFRONT_a171_OPC m171 : 35|1@1+ (1,0) [0|1] "" Vector__XXX
 SG_ VCFRONT_a171_OPCS m171 : 36|1@1+ (1,0) [0|1] "" Vector__XXX
 SG_ VCFRONT_a171_SCCM m171 : 37|1@1+ (1,0) [0|1] "" Vector__XXX
 SG_ VCFRONT_a171_LVBMS m171 : 38|1@1+ (1,0) [0|1] "" Vector__XXX
 SG_ VCFRONT_a171_IDB m171 : 39|1@1+ (1,0) [0|1] "" Vector__XXX
 SG_ VCFRONT_a171_IDB1 m171 : 40|1@1+ (1,0) [0|1] "" Vector__XXX
 SG_ VCFRONT_a171_IDBCAL m171 : 41|1@1+ (1,0) [0|1] "" Vector__XXX
 SG_ VCFRONT_a171_RCU m171 : 42|1@1+ (1,0) [0|1] "" Vector__XXX
 SG_ VCFRONT_a171_RCUCAL m171 : 43|1@1+ (1,0) [0|1] "" Vector__XXX
 SG_ VCFRONT_a171_DPB m171 : 44|1@1+ (1,0) [0|1] "" Vector__XXX
 SG_ VCFRONT_a171_DPBCAL m171 : 45|1@1+ (1,0) [0|1] "" Vector__XXX
 SG_ VCFRONT_a171_serviceMode m171 : 46|1@1+ (1,0) [0|1] "" Vector__XXX
 SG_ VCFRONT_a172_ECUMismatchBits m172 : 16|47@1+ (1,0) [0|140737488355327] "" Vector__XXX
 SG_ VCFRONT_a172_serviceMode m172 : 63|1@1+ (1,0) [0|1] "" Vector__XXX
 SG_ VCFRONT_a173_ECUMismatchBits m173 : 16|47@1+ (1,0) [0|140737488355327] "" Vector__XXX
 SG_ VCFRONT_a173_serviceMode m173 : 63|1@1+ (1,0) [0|1] "" Vector__XXX
 SG_ VCFRONT_a175_snsShortCircuit m175 : 16|1@1+ (1,0) [0|1] "" Vector__XXX
 SG_ VCFRONT_a175_snsDisconnect m175 : 17|1@1+ (1,0) [0|1] "" Vector__XXX
 SG_ VCFRONT_a175_snsRateChangeUp m175 : 18|1@1+ (1,0) [0|1] "" Vector__XXX
 SG_ VCFRONT_a175_snsRateChangeDown m175 : 19|1@1+ (1,0) [0|1] "" Vector__XXX
 SG_ VCFRONT_a176_vehicleState m176 : 16|3@1+ (1,0) [0|7] "" Vector__XXX
 SG_ VCFRONT_a177_mcuAudioCurrent m177 : 16|10@1+ (0.1,0) [0|102.3] "" Vector__XXX
 SG_ VCFRONT_a179_highLVAmpsIntoPCSLo m179 : 16|1@1+ (1,0) [0|1] "" Vector__XXX
 SG_ VCFRONT_a180_vehiclePowerState m180 : 16|2@1+ (1,0) [0|3] "" Vector__XXX
 SG_ VCFRONT_a180_hvState m180 : 18|3@1+ (1,0) [0|7] "" Vector__XXX
 SG_ VCFRONT_a180_bmsState m180 : 24|4@1+ (1,0) [0|15] "" Vector__XXX
 SG_ VCFRONT_a180_notEnoughPowerForSu m180 : 28|1@1+ (1,0) [0|1] "" Vector__XXX
 SG_ VCFRONT_a180_pcsEFuseStable m180 : 29|1@1+ (1,0) [0|1] "" Vector__XXX
 SG_ VCFRONT_a180_vcrightEFuseStable m180 : 30|1@1+ (1,0) [0|1] "" Vector__XXX
 SG_ VCFRONT_a180_contactorEFuseStabl m180 : 31|1@1+ (1,0) [0|1] "" Vector__XXX
 SG_ VCFRONT_a180_hvcEFuseStable m180 : 32|1@1+ (1,0) [0|1] "" Vector__XXX
 SG_ VCFRONT_a180_replaceLVBattery m180 : 33|1@1+ (1,0) [0|1] "" Vector__XXX
 SG_ VCFRONT_a180_BMS_MIA m180 : 34|1@1+ (1,0) [0|1] "" Vector__XXX
 SG_ VCFRONT_a180_PCS_MIA m180 : 35|1@1+ (1,0) [0|1] "" Vector__XXX
 SG_ VCFRONT_a180_HVBlockingMismatch m180 : 36|1@1+ (1,0) [0|1] "" Vector__XXX
 SG_ VCFRONT_a180_serviceMode m180 : 37|1@1+ (1,0) [0|1] "" Vector__XXX
 SG_ VCFRONT_a180_transportMode m180 : 38|1@1+ (1,0) [0|1] "" Vector__XXX
 SG_ VCFRONT_a180_frunkOpen m180 : 39|1@1+ (1,0) [0|1] "" Vector__XXX
 SG_ VCFRONT_a180_dcdcLVSupportStatus m180 : 40|2@1+ (1,0) [0|3] "" Vector__XXX
 SG_ VCFRONT_a181_vehicleState m181 : 16|2@1+ (1,0) [0|3] "" Vector__XXX
 SG_ VCFRONT_a182_deadLV m182 : 16|1@1+ (1,0) [0|1] "" Vector__XXX
 SG_ VCFRONT_a182_voltageDrop m182 : 17|1@1+ (1,0) [0|1] "" Vector__XXX
 SG_ VCFRONT_a182_overcharge m182 : 18|1@1+ (1,0) [0|1] "" Vector__XXX
 SG_ VCFRONT_a182_LVFloorReached m182 : 19|1@1+ (1,0) [0|1] "" Vector__XXX
 SG_ VCFRONT_a182_shortedCell m182 : 20|1@1+ (1,0) [0|1] "" Vector__XXX
 SG_ VCFRONT_a182_postPORExcessiveAh m182 : 21|1@1+ (1,0) [0|1] "" Vector__XXX
 SG_ VCFRONT_a182_resistanceEstimatio m182 : 22|1@1+ (1,0) [0|1] "" Vector__XXX
 SG_ VCFRONT_a182_dcrMilliOhmsAboveTh m182 : 23|1@1+ (1,0) [0|1] "" Vector__XXX
 SG_ VCFRONT_a182_prechargeLVLoadRedu m182 : 24|1@1+ (1,0) [0|1] "" Vector__XXX
 SG_ VCFRONT_a182_factoryMode m182 : 25|1@1+ (1,0) [0|1] "" Vector__XXX
 SG_ VCFRONT_a182_serviceMode m182 : 26|1@1+ (1,0) [0|1] "" Vector__XXX
 SG_ VCFRONT_a182_transportMode m182 : 27|1@1+ (1,0) [0|1] "" Vector__XXX
 SG_ VCFRONT_a182_frunkOpen m182 : 28|1@1+ (1,0) [0|1] "" Vector__XXX
 SG_ VCFRONT_a182_packOverDischarged m182 : 29|1@1+ (1,0) [0|1] "" Vector__XXX
 SG_ VCFRONT_a182_cellImbalance m182 : 30|1@1+ (1,0) [0|1] "" Vector__XXX
 SG_ VCFRONT_a182_instantPrechargeDCR m182 : 31|1@1+ (1,0) [0|1] "" Vector__XXX
 SG_ VCFRONT_a182_ambientTemp m182 : 32|7@1+ (1,-40) [-40|87] "" Vector__XXX
 SG_ VCFRONT_a182_dischargedAmpHours m182 : 40|8@1+ (60,0) [0|15300] "" Vector__XXX
 SG_ VCFRONT_a182_chargedAmpHours m182 : 48|8@1+ (60,0) [0|15300] "" Vector__XXX
 SG_ VCFRONT_a182_calibrationLostFaul m182 : 56|1@1+ (1,0) [0|1] "" Vector__XXX
 SG_ VCFRONT_a182_samplingHWError m182 : 57|1@1+ (1,0) [0|1] "" Vector__XXX
 SG_ VCFRONT_a182_brickOverDischarged m182 : 58|1@1+ (1,0) [0|1] "" Vector__XXX
 SG_ VCFRONT_a182_batteryType m182 : 59|3@1+ (1,0) [0|7] "" Vector__XXX
 SG_ VCFRONT_a186_noDriveChgCableConX m186 : 16|1@1+ (1,0) [0|1] "" Vector__XXX
 SG_ VCFRONT_a187_vehBusRetryCount m187 : 16|9@1+ (1,0) [0|511] "" Vector__XXX
 SG_ VCFRONT_a187_partyBusRetryCount m187 : 25|9@1+ (1,0) [0|511] "" Vector__XXX
 SG_ VCFRONT_a187_hvsBusRetryCount m187 : 34|9@1+ (1,0) [0|511] "" Vector__XXX
 SG_ VCFRONT_a187_ethBusRetryCount m187 : 43|9@1+ (1,0) [0|511] "" Vector__XXX
 SG_ VCFRONT_a187_chBusRetryCount m187 : 52|9@1+ (1,0) [0|511] "" Vector__XXX
 SG_ VCFRONT_a188_sleepBypassCurrent m188 : 16|8@1+ (0.2,0) [0|51] "" Vector__XXX
 SG_ VCFRONT_a188_IBSCurrent m188 : 24|12@1- (0.02,0) [-40.96|40.94] "" Vector__XXX
 SG_ VCFRONT_a188_vehicleState m188 : 36|5@1+ (1,0) [0|31] "" Vector__XXX
 SG_ VCFRONT_a188_timeNotSleeping m188 : 41|6@1+ (1,0) [0|63] "" Vector__XXX
 SG_ VCFRONT_a188_chargeRequest m188 : 47|1@1+ (1,0) [0|1] "" Vector__XXX
 SG_ VCFRONT_a188_12VSupport m188 : 48|1@1+ (1,0) [0|1] "" Vector__XXX
 SG_ VCFRONT_a188_ThermalSupport m188 : 49|1@1+ (1,0) [0|1] "" Vector__XXX
 SG_ VCFRONT_a188_accessoryRequest m188 : 50|1@1+ (1,0) [0|1] "" Vector__XXX
 SG_ VCFRONT_a188_CANAfterQuiet m188 : 51|1@1+ (1,0) [0|1] "" Vector__XXX
 SG_ VCFRONT_a188_SleepRequestTimeout m188 : 52|1@1+ (1,0) [0|1] "" Vector__XXX
 SG_ VCFRONT_a188_wakeUpMsgID m188 : 53|11@1+ (1,0) [0|2047] "" Vector__XXX
 SG_ VCFRONT_a191_vehiclePowerState m191 : 16|2@1+ (1,0) [0|3] "" Vector__XXX
 SG_ VCFRONT_a191_hvState m191 : 18|3@1+ (1,0) [0|7] "" Vector__XXX
 SG_ VCFRONT_a191_reverseBatteryEFuse m191 : 21|1@1+ (1,0) [0|1] "" Vector__XXX
 SG_ VCFRONT_a191_vehicleLoadShedActi m191 : 22|1@1+ (1,0) [0|1] "" Vector__XXX
 SG_ VCFRONT_a191_vehicleLoadShedHvFa m191 : 23|1@1+ (1,0) [0|1] "" Vector__XXX
 SG_ VCFRONT_a191_vehicleLoadShedPost m191 : 24|1@1+ (1,0) [0|1] "" Vector__XXX
 SG_ VCFRONT_a191_IBSVoltage m191 : 25|8@1+ (0.08741903,0) [0|22.29185265] "" Vector__XXX
 SG_ VCFRONT_a191_a180_DCDCNotSupport m191 : 33|1@1+ (1,0) [0|1] "" Vector__XXX
 SG_ VCFRONT_a191_MOSState m191 : 34|2@1+ (1,0) [0|3] "" Vector__XXX
 SG_ VCFRONT_a191_LVBMSVoltage m191 : 36|8@1+ (0.08741903,0) [0|22.29185265] "" Vector__XXX
 SG_ VCFRONT_a191_ECPAState m191 : 44|2@1+ (1,0) [0|3] "" Vector__XXX
 SG_ VCFRONT_a191_LVBMSCurrentTargetV m191 : 46|1@1+ (1,0) [0|1] "" Vector__XXX
 SG_ VCFRONT_a191_LVBMSVoltageTargetV m191 : 47|1@1+ (1,0) [0|1] "" Vector__XXX
 SG_ VCFRONT_a191_serviceMode m191 : 48|1@1+ (1,0) [0|1] "" Vector__XXX
 SG_ VCFRONT_a191_frunkOpen m191 : 49|1@1+ (1,0) [0|1] "" Vector__XXX
 SG_ VCFRONT_a191_vehicleLoadShedStag m191 : 50|2@1+ (1,0) [0|3] "" Vector__XXX
 SG_ VCFRONT_a191_exitDriveWarningTim m191 : 52|1@1+ (1,0) [0|1] "" Vector__XXX
 SG_ VCFRONT_a191_LVBMSMIA m191 : 53|1@1+ (1,0) [0|1] "" Vector__XXX
 SG_ VCFRONT_a191_PCS_MIA m191 : 54|1@1+ (1,0) [0|1] "" Vector__XXX
 SG_ VCFRONT_a191_NotEnoughPowerForSu m191 : 55|1@1+ (1,0) [0|1] "" Vector__XXX
 SG_ VCFRONT_a191_bmsState m191 : 56|4@1+ (1,0) [0|15] "" Vector__XXX
 SG_ VCFRONT_a192_vehiclePowerState m192 : 16|2@1+ (1,0) [0|3] "" Vector__XXX
 SG_ VCFRONT_a192_hvState m192 : 18|3@1+ (1,0) [0|7] "" Vector__XXX
 SG_ VCFRONT_a192_notEnoughPowerForSu m192 : 21|1@1+ (1,0) [0|1] "" Vector__XXX
 SG_ VCFRONT_a192_pcsEFuseStable m192 : 22|1@1+ (1,0) [0|1] "" Vector__XXX
 SG_ VCFRONT_a192_vcrightEFuseStable m192 : 23|1@1+ (1,0) [0|1] "" Vector__XXX
 SG_ VCFRONT_a192_contactorEFuseStabl m192 : 24|1@1+ (1,0) [0|1] "" Vector__XXX
 SG_ VCFRONT_a192_hvcEFuseStable m192 : 25|1@1+ (1,0) [0|1] "" Vector__XXX
 SG_ VCFRONT_a192_replaceLVBattery m192 : 26|1@1+ (1,0) [0|1] "" Vector__XXX
 SG_ VCFRONT_a192_BMS_MIA m192 : 27|1@1+ (1,0) [0|1] "" Vector__XXX
 SG_ VCFRONT_a192_PCS_MIA m192 : 28|1@1+ (1,0) [0|1] "" Vector__XXX
 SG_ VCFRONT_a192_HVBlockingMismatch m192 : 29|1@1+ (1,0) [0|1] "" Vector__XXX
 SG_ VCFRONT_a192_disconnected12V m192 : 30|1@1+ (1,0) [0|1] "" Vector__XXX
 SG_ VCFRONT_a192_LVBatteryCannotSupp m192 : 31|1@1+ (1,0) [0|1] "" Vector__XXX
 SG_ VCFRONT_a192_DI_gear m192 : 32|3@1+ (1,0) [0|7] "" Vector__XXX
 SG_ VCFRONT_a192_GTW_factoryGated m192 : 35|1@1+ (1,0) [0|1] "" Vector__XXX
 SG_ VCFRONT_a192_GTW_updateStarted m192 : 36|1@1+ (1,0) [0|1] "" Vector__XXX
 SG_ VCFRONT_a192_serviceMode m192 : 37|1@1+ (1,0) [0|1] "" Vector__XXX
 SG_ VCFRONT_a192_frunkOpen m192 : 38|1@1+ (1,0) [0|1] "" Vector__XXX
 SG_ VCFRONT_a192_IBSCurrent m192 : 40|8@1+ (0.5,-63) [-63|64.5] "" Vector__XXX
 SG_ VCFRONT_a192_PCSCurrent m192 : 48|8@1+ (0.5,-127) [-127|0.5] "" Vector__XXX
 SG_ VCFRONT_a192_HVFaultLoadShedActi m192 : 56|1@1+ (1,0) [0|1] "" Vector__XXX
 SG_ VCFRONT_a192_postCrashLoadShedAc m192 : 57|1@1+ (1,0) [0|1] "" Vector__XXX
 SG_ VCFRONT_a195_IBSVoltage m195 : 16|12@1+ (0.005443676,0) [0|22.29185322] "" Vector__XXX
 SG_ VCFRONT_a195_serviceMode m195 : 28|1@1+ (1,0) [0|1] "" Vector__XXX
 SG_ VCFRONT_a195_frunkOpen m195 : 29|1@1+ (1,0) [0|1] "" Vector__XXX
 SG_ VCFRONT_a196_factoryMode m196 : 16|1@1+ (1,0) [0|1] "" Vector__XXX
 SG_ VCFRONT_a196_serviceMode m196 : 17|1@1+ (1,0) [0|1] "" Vector__XXX
 SG_ VCFRONT_a196_transportMode m196 : 18|1@1+ (1,0) [0|1] "" Vector__XXX
 SG_ VCFRONT_a196_frunkOpen m196 : 19|1@1+ (1,0) [0|1] "" Vector__XXX
 SG_ VCFRONT_a196_vehiclePowerState m196 : 20|2@1+ (1,0) [0|3] "" Vector__XXX
 SG_ VCFRONT_a196_batterySMState m196 : 24|4@1+ (1,0) [0|15] "" Vector__XXX
 SG_ VCFRONT_a196_disconnectedBattery m196 : 28|12@1+ (0.004884005,-10) [-10|10.000000475] "" Vector__XXX
 SG_ VCFRONT_a196_disconnectedBa_0002 m196 : 40|8@1+ (0.0392156876624,6) [6|16.0000003539] "" Vector__XXX
 SG_ VCFRONT_a196_disconnectedBa_0001 m196 : 48|8@1+ (0.0392156876624,6) [6|16.0000003539] "" Vector__XXX
 SG_ VCFRONT_a196_ECPAState m196 : 56|2@1+ (1,0) [0|3] "" Vector__XXX
 SG_ VCFRONT_a198_outputState m198 : 16|1@1+ (1,0) [0|1] "" Vector__XXX
 SG_ VCFRONT_a198_NVRAMState m198 : 17|1@1+ (1,0) [0|1] "" Vector__XXX
 SG_ VCFRONT_a198_lockoutState m198 : 18|1@1+ (1,0) [0|1] "" Vector__XXX
 SG_ VCFRONT_a199_outputState m199 : 16|1@1+ (1,0) [0|1] "" Vector__XXX
 SG_ VCFRONT_a199_NVRAMState m199 : 17|1@1+ (1,0) [0|1] "" Vector__XXX
 SG_ VCFRONT_a199_lockoutState m199 : 18|1@1+ (1,0) [0|1] "" Vector__XXX
 SG_ VCFRONT_a200_vcleftSelfTest m200 : 16|4@1+ (1,0) [0|15] "" Vector__XXX
 SG_ VCFRONT_a201_vcrightSelfTest m201 : 16|4@1+ (1,0) [0|15] "" Vector__XXX
 SG_ VCFRONT_a202_pcsSelfTest m202 : 16|4@1+ (1,0) [0|15] "" Vector__XXX
 SG_ VCFRONT_a207_vbatFusedSelfTest m207 : 16|4@1+ (1,0) [0|15] "" Vector__XXX
 SG_ VCFRONT_a210_valveUnderTravel m210 : 16|1@1+ (1,0) [0|1] "" Vector__XXX
 SG_ VCFRONT_a210_valveOverTravel m210 : 17|1@1+ (1,0) [0|1] "" Vector__XXX
 SG_ VCFRONT_a210_valveNoTravel m210 : 18|1@1+ (1,0) [0|1] "" Vector__XXX
 SG_ VCFRONT_a212_IBSTemp m212 : 16|16@1- (0.01,0) [-327.68|327.67] "" Vector__XXX
 SG_ VCFRONT_a213_IBSVolts m213 : 16|12@1+ (0.005443676,0) [0|22.29185322] "" Vector__XXX
 SG_ VCFRONT_a213_IBSAh m213 : 32|14@1- (0.01,0) [-81.92|81.91] "" Vector__XXX
 SG_ VCFRONT_a213_LVBatteryTemp m213 : 48|16@1- (0.01,0) [-327.68|327.67] "" Vector__XXX
 SG_ VCFRONT_a214_motorFaulted m214 : 16|1@1+ (1,0) [0|1] "" Vector__XXX
 SG_ VCFRONT_a214_motorLocked m214 : 17|1@1+ (1,0) [0|1] "" Vector__XXX
 SG_ VCFRONT_a214_ecuReset m214 : 18|1@1+ (1,0) [0|1] "" Vector__XXX
 SG_ VCFRONT_a214_fetTempIrrational m214 : 19|1@1+ (1,0) [0|1] "" Vector__XXX
 SG_ VCFRONT_a214_motorControlError m214 : 20|1@1+ (1,0) [0|1] "" Vector__XXX
 SG_ VCFRONT_a214_underVoltage m214 : 21|1@1+ (1,0) [0|1] "" Vector__XXX
 SG_ VCFRONT_a214_overVoltage m214 : 22|1@1+ (1,0) [0|1] "" Vector__XXX
 SG_ VCFRONT_a214_hardwareOvercurrent m214 : 23|1@1+ (1,0) [0|1] "" Vector__XXX
 SG_ VCFRONT_a214_motorOpenPhase m214 : 24|1@1+ (1,0) [0|1] "" Vector__XXX
 SG_ VCFRONT_a214_motorSoftOpenPhase m214 : 25|1@1+ (1,0) [0|1] "" Vector__XXX
 SG_ VCFRONT_a214_motorOvertemp m214 : 26|1@1+ (1,0) [0|1] "" Vector__XXX
 SG_ VCFRONT_a214_dcOvercurrent m214 : 27|1@1+ (1,0) [0|1] "" Vector__XXX
 SG_ VCFRONT_a214_motorStalled m214 : 28|1@1+ (1,0) [0|1] "" Vector__XXX
 SG_ VCFRONT_a214_selfTestFailed m214 : 29|1@1+ (1,0) [0|1] "" Vector__XXX
 SG_ VCFRONT_a214_selfTestResult m214 : 32|3@1+ (1,0) [0|7] "" Vector__XXX
 SG_ VCFRONT_a214_linChecksumError m214 : 35|1@1+ (1,0) [0|1] "" Vector__XXX
 SG_ VCFRONT_a214_linFramingError m214 : 36|1@1+ (1,0) [0|1] "" Vector__XXX
 SG_ VCFRONT_a214_phaseShorted m214 : 37|1@1+ (1,0) [0|1] "" Vector__XXX
 SG_ VCFRONT_a214_busVoltageIrrationa m214 : 38|1@1+ (1,0) [0|1] "" Vector__XXX
 SG_ VCFRONT_a214_dcCurrentIrrational m214 : 39|1@1+ (1,0) [0|1] "" Vector__XXX
 SG_ VCFRONT_a214_motorSpeedIrrationa m214 : 40|1@1+ (1,0) [0|1] "" Vector__XXX
 SG_ VCFRONT_a214_supplyVoltageIrrati m214 : 41|1@1+ (1,0) [0|1] "" Vector__XXX
 SG_ VCFRONT_a214_motorPhaseCurrentIr m214 : 42|1@1+ (1,0) [0|1] "" Vector__XXX
 SG_ VCFRONT_a214_chipOvertemp m214 : 43|1@1+ (1,0) [0|1] "" Vector__XXX
 SG_ VCFRONT_a214_motorSpeedTooHigh m214 : 44|1@1+ (1,0) [0|1] "" Vector__XXX
 SG_ VCFRONT_a214_phaseOvercurrent m214 : 45|1@1+ (1,0) [0|1] "" Vector__XXX
 SG_ VCFRONT_a214_vddaOvercurrent m214 : 46|1@1+ (1,0) [0|1] "" Vector__XXX
 SG_ VCFRONT_a214_busVoltageUnhealthy m214 : 47|1@1+ (1,0) [0|1] "" Vector__XXX
 SG_ VCFRONT_a214_hsVdsOvervoltage m214 : 48|1@1+ (1,0) [0|1] "" Vector__XXX
 SG_ VCFRONT_a214_hsVdsOvervoltageMas m214 : 49|3@1+ (1,0) [0|7] "" Vector__XXX
 SG_ VCFRONT_a214_lsVdsOvervoltage m214 : 52|1@1+ (1,0) [0|1] "" Vector__XXX
 SG_ VCFRONT_a214_lsVdsOvervoltageMas m214 : 53|3@1+ (1,0) [0|7] "" Vector__XXX
 SG_ VCFRONT_a214_payloadBitsNotSet m214 : 56|1@1+ (1,0) [0|1] "" Vector__XXX
 SG_ VCFRONT_a216_inDrive m216 : 16|1@1+ (1,0) [0|1] "" Vector__XXX
 SG_ VCFRONT_a216_hvState m216 : 17|3@1+ (1,0) [0|7] "" Vector__XXX
 SG_ VCFRONT_a216_vcleftFastBlowImmin m216 : 20|1@1+ (1,0) [0|1] "" Vector__XXX
 SG_ VCFRONT_a216_vcleftFastBlowDebou m216 : 21|1@1+ (1,0) [0|1] "" Vector__XXX
 SG_ VCFRONT_a216_vcleftStaticImminen m216 : 22|1@1+ (1,0) [0|1] "" Vector__XXX
 SG_ VCFRONT_a216_vcleftDynamicImmine m216 : 23|1@1+ (1,0) [0|1] "" Vector__XXX
 SG_ VCFRONT_a216_vcrightFastBlowImmi m216 : 24|1@1+ (1,0) [0|1] "" Vector__XXX
 SG_ VCFRONT_a216_vcrightFastBlowDebo m216 : 25|1@1+ (1,0) [0|1] "" Vector__XXX
 SG_ VCFRONT_a216_vcrightStaticImmine m216 : 26|1@1+ (1,0) [0|1] "" Vector__XXX
 SG_ VCFRONT_a216_vcrightDynamicImmin m216 : 27|1@1+ (1,0) [0|1] "" Vector__XXX
 SG_ VCFRONT_a217_motorFaulted m217 : 16|1@1+ (1,0) [0|1] "" Vector__XXX
 SG_ VCFRONT_a217_motorLocked m217 : 17|1@1+ (1,0) [0|1] "" Vector__XXX
 SG_ VCFRONT_a217_ecuReset m217 : 18|1@1+ (1,0) [0|1] "" Vector__XXX
 SG_ VCFRONT_a217_fetTempIrrational m217 : 19|1@1+ (1,0) [0|1] "" Vector__XXX
 SG_ VCFRONT_a217_motorControlError m217 : 20|1@1+ (1,0) [0|1] "" Vector__XXX
 SG_ VCFRONT_a217_underVoltage m217 : 21|1@1+ (1,0) [0|1] "" Vector__XXX
 SG_ VCFRONT_a217_overVoltage m217 : 22|1@1+ (1,0) [0|1] "" Vector__XXX
 SG_ VCFRONT_a217_hardwareOvercurrent m217 : 23|1@1+ (1,0) [0|1] "" Vector__XXX
 SG_ VCFRONT_a217_motorOpenPhase m217 : 24|1@1+ (1,0) [0|1] "" Vector__XXX
 SG_ VCFRONT_a217_motorSoftOpenPhase m217 : 25|1@1+ (1,0) [0|1] "" Vector__XXX
 SG_ VCFRONT_a217_motorOvertemp m217 : 26|1@1+ (1,0) [0|1] "" Vector__XXX
 SG_ VCFRONT_a217_dcOvercurrent m217 : 27|1@1+ (1,0) [0|1] "" Vector__XXX
 SG_ VCFRONT_a217_motorStalled m217 : 28|1@1+ (1,0) [0|1] "" Vector__XXX
 SG_ VCFRONT_a217_selfTestFailed m217 : 29|1@1+ (1,0) [0|1] "" Vector__XXX
 SG_ VCFRONT_a217_selfTestResult m217 : 32|3@1+ (1,0) [0|7] "" Vector__XXX
 SG_ VCFRONT_a217_linChecksumError m217 : 35|1@1+ (1,0) [0|1] "" Vector__XXX
 SG_ VCFRONT_a217_linFramingError m217 : 36|1@1+ (1,0) [0|1] "" Vector__XXX
 SG_ VCFRONT_a217_phaseShorted m217 : 37|1@1+ (1,0) [0|1] "" Vector__XXX
 SG_ VCFRONT_a217_busVoltageIrrationa m217 : 38|1@1+ (1,0) [0|1] "" Vector__XXX
 SG_ VCFRONT_a217_dcCurrentIrrational m217 : 39|1@1+ (1,0) [0|1] "" Vector__XXX
 SG_ VCFRONT_a217_motorSpeedIrrationa m217 : 40|1@1+ (1,0) [0|1] "" Vector__XXX
 SG_ VCFRONT_a217_supplyVoltageIrrati m217 : 41|1@1+ (1,0) [0|1] "" Vector__XXX
 SG_ VCFRONT_a217_motorPhaseCurrentIr m217 : 42|1@1+ (1,0) [0|1] "" Vector__XXX
 SG_ VCFRONT_a217_chipOvertemp m217 : 43|1@1+ (1,0) [0|1] "" Vector__XXX
 SG_ VCFRONT_a217_motorSpeedTooHigh m217 : 44|1@1+ (1,0) [0|1] "" Vector__XXX
 SG_ VCFRONT_a217_phaseOvercurrent m217 : 45|1@1+ (1,0) [0|1] "" Vector__XXX
 SG_ VCFRONT_a217_vddaOvercurrent m217 : 46|1@1+ (1,0) [0|1] "" Vector__XXX
 SG_ VCFRONT_a217_busVoltageUnhealthy m217 : 47|1@1+ (1,0) [0|1] "" Vector__XXX
 SG_ VCFRONT_a217_hsVdsOvervoltage m217 : 48|1@1+ (1,0) [0|1] "" Vector__XXX
 SG_ VCFRONT_a217_hsVdsOvervoltageMas m217 : 49|3@1+ (1,0) [0|7] "" Vector__XXX
 SG_ VCFRONT_a217_lsVdsOvervoltage m217 : 52|1@1+ (1,0) [0|1] "" Vector__XXX
 SG_ VCFRONT_a217_lsVdsOvervoltageMas m217 : 53|3@1+ (1,0) [0|7] "" Vector__XXX
 SG_ VCFRONT_a217_payloadBitsNotSet m217 : 56|1@1+ (1,0) [0|1] "" Vector__XXX
 SG_ VCFRONT_a219_IBSVolts m219 : 16|12@1+ (0.005443676,0) [0|22.29185322] "" Vector__XXX
 SG_ VCFRONT_a219_IBSAh m219 : 32|14@1- (0.01,0) [-81.92|81.91] "" Vector__XXX
 SG_ VCFRONT_a219_IBSCurrent m219 : 48|16@1- (0.005,0) [-163.84|163.835] "" Vector__XXX
 SG_ VCFRONT_a220_IBSCurrent m220 : 16|16@1- (0.005,0) [-163.84|163.835] "" Vector__XXX
 SG_ VCFRONT_a220_PCSCurrent m220 : 32|8@1+ (0.5,-127) [-127|0.5] "" Vector__XXX
 SG_ VCFRONT_a220_serviceMode m220 : 40|1@1+ (1,0) [0|1] "" Vector__XXX
 SG_ VCFRONT_a220_frunkOpen m220 : 41|1@1+ (1,0) [0|1] "" Vector__XXX
 SG_ VCFRONT_a221_outputFaulted m221 : 16|1@1+ (1,0) [0|1] "" Vector__XXX
 SG_ VCFRONT_a221_currentSenseFaulted m221 : 17|1@1+ (1,0) [0|1] "" Vector__XXX
 SG_ VCFRONT_a221_tempSenseFaulted m221 : 18|1@1+ (1,0) [0|1] "" Vector__XXX
 SG_ VCFRONT_a221_underCurrent m221 : 19|1@1+ (1,0) [0|1] "" Vector__XXX
 SG_ VCFRONT_a221_overCurrent m221 : 20|1@1+ (1,0) [0|1] "" Vector__XXX
 SG_ VCFRONT_a221_overTemperature m221 : 21|1@1+ (1,0) [0|1] "" Vector__XXX
 SG_ VCFRONT_a222_outputFaulted m222 : 16|1@1+ (1,0) [0|1] "" Vector__XXX
 SG_ VCFRONT_a222_currentSenseFaulted m222 : 17|1@1+ (1,0) [0|1] "" Vector__XXX
 SG_ VCFRONT_a222_tempSenseFaulted m222 : 18|1@1+ (1,0) [0|1] "" Vector__XXX
 SG_ VCFRONT_a222_underCurrent m222 : 19|1@1+ (1,0) [0|1] "" Vector__XXX
 SG_ VCFRONT_a222_overCurrent m222 : 20|1@1+ (1,0) [0|1] "" Vector__XXX
 SG_ VCFRONT_a222_overTemperature m222 : 21|1@1+ (1,0) [0|1] "" Vector__XXX
 SG_ VCFRONT_a223_12VTemperature m223 : 16|16@1- (0.1,0) [-3276.8|3276.7] "" Vector__XXX
 SG_ VCFRONT_a227_motorFaulted m227 : 16|1@1+ (1,0) [0|1] "" Vector__XXX
 SG_ VCFRONT_a227_motorLocked m227 : 17|1@1+ (1,0) [0|1] "" Vector__XXX
 SG_ VCFRONT_a227_ecuReset m227 : 18|1@1+ (1,0) [0|1] "" Vector__XXX
 SG_ VCFRONT_a227_fetTempIrrational m227 : 19|1@1+ (1,0) [0|1] "" Vector__XXX
 SG_ VCFRONT_a227_motorControlError m227 : 20|1@1+ (1,0) [0|1] "" Vector__XXX
 SG_ VCFRONT_a227_underVoltage m227 : 21|1@1+ (1,0) [0|1] "" Vector__XXX
 SG_ VCFRONT_a227_overVoltage m227 : 22|1@1+ (1,0) [0|1] "" Vector__XXX
 SG_ VCFRONT_a227_hardwareOvercurrent m227 : 23|1@1+ (1,0) [0|1] "" Vector__XXX
 SG_ VCFRONT_a227_motorOpenPhase m227 : 24|1@1+ (1,0) [0|1] "" Vector__XXX
 SG_ VCFRONT_a227_motorSoftOpenPhase m227 : 25|1@1+ (1,0) [0|1] "" Vector__XXX
 SG_ VCFRONT_a227_motorOvertemp m227 : 26|1@1+ (1,0) [0|1] "" Vector__XXX
 SG_ VCFRONT_a227_dcOvercurrent m227 : 27|1@1+ (1,0) [0|1] "" Vector__XXX
 SG_ VCFRONT_a227_motorStalled m227 : 28|1@1+ (1,0) [0|1] "" Vector__XXX
 SG_ VCFRONT_a227_selfTestFailed m227 : 29|1@1+ (1,0) [0|1] "" Vector__XXX
 SG_ VCFRONT_a227_selfTestResult m227 : 32|3@1+ (1,0) [0|7] "" Vector__XXX
 SG_ VCFRONT_a227_linChecksumError m227 : 35|1@1+ (1,0) [0|1] "" Vector__XXX
 SG_ VCFRONT_a227_linFramingError m227 : 36|1@1+ (1,0) [0|1] "" Vector__XXX
 SG_ VCFRONT_a227_phaseShorted m227 : 37|1@1+ (1,0) [0|1] "" Vector__XXX
 SG_ VCFRONT_a227_busVoltageIrrationa m227 : 38|1@1+ (1,0) [0|1] "" Vector__XXX
 SG_ VCFRONT_a227_dcCurrentIrrational m227 : 39|1@1+ (1,0) [0|1] "" Vector__XXX
 SG_ VCFRONT_a227_motorSpeedIrrationa m227 : 40|1@1+ (1,0) [0|1] "" Vector__XXX
 SG_ VCFRONT_a227_supplyVoltageIrrati m227 : 41|1@1+ (1,0) [0|1] "" Vector__XXX
 SG_ VCFRONT_a227_motorPhaseCurrentIr m227 : 42|1@1+ (1,0) [0|1] "" Vector__XXX
 SG_ VCFRONT_a227_chipOvertemp m227 : 43|1@1+ (1,0) [0|1] "" Vector__XXX
 SG_ VCFRONT_a227_motorSpeedTooHigh m227 : 44|1@1+ (1,0) [0|1] "" Vector__XXX
 SG_ VCFRONT_a227_phaseOvercurrent m227 : 45|1@1+ (1,0) [0|1] "" Vector__XXX
 SG_ VCFRONT_a227_vddaOvercurrent m227 : 46|1@1+ (1,0) [0|1] "" Vector__XXX
 SG_ VCFRONT_a227_busVoltageUnhealthy m227 : 47|1@1+ (1,0) [0|1] "" Vector__XXX
 SG_ VCFRONT_a227_hsVdsOvervoltage m227 : 48|1@1+ (1,0) [0|1] "" Vector__XXX
 SG_ VCFRONT_a227_hsVdsOvervoltageMas m227 : 49|3@1+ (1,0) [0|7] "" Vector__XXX
 SG_ VCFRONT_a227_lsVdsOvervoltage m227 : 52|1@1+ (1,0) [0|1] "" Vector__XXX
 SG_ VCFRONT_a227_lsVdsOvervoltageMas m227 : 53|3@1+ (1,0) [0|7] "" Vector__XXX
 SG_ VCFRONT_a227_payloadBitsNotSet m227 : 56|1@1+ (1,0) [0|1] "" Vector__XXX
 SG_ VCFRONT_a231_12VTemperature m231 : 16|16@1- (0.1,0) [-3276.8|3276.7] "" Vector__XXX
 SG_ VCFRONT_a233_current m233 : 16|10@1+ (0.1,0) [0|102.3] "" Vector__XXX
 SG_ VCFRONT_a234_current m234 : 16|10@1+ (0.1,0) [0|102.3] "" Vector__XXX
 SG_ VCFRONT_a235_ptSensorTemp m235 : 16|11@1+ (0.125,-40) [-40|215.875] "" Vector__XXX
 SG_ VCFRONT_a236_batSensorTemp m236 : 16|11@1+ (0.125,-40) [-40|215.875] "" Vector__XXX
 SG_ VCFRONT_a242_LVBatteryTemp m242 : 16|7@1+ (1,-40) [-40|87] "" Vector__XXX
 SG_ VCFRONT_a242_IBSCurrent m242 : 24|12@1- (0.1,0) [-204.8|204.7] "" Vector__XXX
 SG_ VCFRONT_a242_IBSVoltage m242 : 36|11@1+ (0.0108873518184,0) [0|22.2864091723] "" Vector__XXX
 SG_ VCFRONT_a242_IBSAmpHours m242 : 48|8@1+ (0.01,-2.55) [-2.55|4.4408920985e-16] "" Vector__XXX
 SG_ VCFRONT_a242_vehiclePowerState m242 : 56|2@1+ (1,0) [0|3] "" Vector__XXX
 SG_ VCFRONT_a243_IBSVolts m243 : 16|12@1+ (0.005443676,0) [0|22.29185322] "" Vector__XXX
 SG_ VCFRONT_a243_IBSCurrent m243 : 32|16@1- (0.005,0) [-163.84|163.835] "" Vector__XXX
 SG_ VCFRONT_a243_LVBatteryTemp m243 : 48|16@1- (0.01,0) [-327.68|327.67] "" Vector__XXX
 SG_ VCFRONT_a244_current m244 : 16|16@1+ (0.1,0) [0|6553.5] "" Vector__XXX
 SG_ VCFRONT_a244_voltage m244 : 32|16@1+ (0.1,0) [0|6553.5] "" Vector__XXX
 SG_ VCFRONT_a244_vbatProtVoltage m244 : 48|16@1+ (0.1,0) [0|6553.5] "" Vector__XXX
 SG_ VCFRONT_a245_current m245 : 16|16@1+ (0.1,0) [0|6553.5] "" Vector__XXX
 SG_ VCFRONT_a245_voltage m245 : 32|16@1+ (0.1,0) [0|6553.5] "" Vector__XXX
 SG_ VCFRONT_a245_eFuseRemainingRetri m245 : 48|4@1+ (1,0) [0|15] "" Vector__XXX
 SG_ VCFRONT_a246_current m246 : 16|16@1+ (0.1,0) [0|6553.5] "" Vector__XXX
 SG_ VCFRONT_a246_voltage m246 : 32|16@1+ (0.1,0) [0|6553.5] "" Vector__XXX
 SG_ VCFRONT_a246_eFuseRemainingRetri m246 : 48|4@1+ (1,0) [0|15] "" Vector__XXX
 SG_ VCFRONT_a247_solenoidISense m247 : 16|8@1- (0.01,0) [-1.28|1.27] "" Vector__XXX
 SG_ VCFRONT_a248_AS8510Voltage m248 : 16|12@1+ (0.005443676,0) [0|22.29185322] "" Vector__XXX
 SG_ VCFRONT_a248_IBSVoltage m248 : 28|12@1+ (0.005443676,0) [0|22.29185322] "" Vector__XXX
 SG_ VCFRONT_a248_vbatMonitor m248 : 40|12@1+ (0.005443676,0) [0|22.29185322] "" Vector__XXX
 SG_ VCFRONT_a248_voltageCalScaling m248 : 52|12@1+ (0.025,0) [0|102.375] "" Vector__XXX
 SG_ VCFRONT_a249_tempCoolantBatInlet m249 : 16|10@1+ (0.125,-40) [-40|87.875] "" Vector__XXX
 SG_ VCFRONT_a249_tempCoolantPTInlet m249 : 26|11@1+ (0.125,-40) [-40|215.875] "" Vector__XXX
 SG_ VCFRONT_a250_isGlobalHeadlamps m250 : 16|1@1+ (1,0) [0|1] "" Vector__XXX
 SG_ VCFRONT_a250_isVirtualPitchSenso m250 : 17|1@1+ (1,0) [0|1] "" Vector__XXX
 SG_ VCFRONT_a250_isAimedHCML m250 : 18|1@1+ (1,0) [0|1] "" Vector__XXX
 SG_ VCFRONT_a250_isAimedHCMR m250 : 19|1@1+ (1,0) [0|1] "" Vector__XXX
 SG_ VCFRONT_a250_calibratedVerticalP m250 : 20|10@1+ (1,0) [0|1023] "" Vector__XXX
 SG_ VCFRONT_a250_calibratedVert_0001 m250 : 30|10@1+ (1,0) [0|1023] "" Vector__XXX
 SG_ VCFRONT_a250_calibratedHorizonta m250 : 40|10@1+ (1,0) [0|1023] "" Vector__XXX

CM_ BO_ 609 "Front body controller message: 12 v battery status";
CM_ SG_ 609 VCFRONT_12VBatteryStatusIndex "Front body controller: 12 v battery status index";
CM_ SG_ 609 VCFRONT_good12VforUpdate "Indicates the Low Voltage (LV) battery health as it pertains to permitting an Over-The-Air (OTA) update.";
CM_ SG_ 609 VCFRONT_LVLoadRequest "Controls the loading of the Low Voltage (LV) battery for diagnostic purposes.";
CM_ SG_ 609 VCFRONT_12VBatteryStatusCounter "Front body controller: 12 v battery status counter";
CM_ SG_ 609 VCFRONT_12VBatteryStatusChecksum "Front body controller: 12 v battery status checksum";
CM_ SG_ 609 VCFRONT_batterySupportRequest "Reports the request to the Power Conversion System (PCS) to supply power to the Low Voltage (LV) battery.";
CM_ SG_ 609 VCFRONT_batterySMState "Reports the Low Voltage (LV) battery maintenance state machine state.";
CM_ SG_ 609 VCFRONT_eFuseRecoveryStateDBG "Reports the state of the Low Voltage (LV) battery eFuse recovery state machine.";
CM_ SG_ 609 VCFRONT_batteryLINScheduleDBG "Front body controller: battery LIN schedule DBG";
CM_ SG_ 609 VCFRONT_resistanceEstimationTest "Front body controller: resistance estimation test counter";
CM_ SG_ 609 VCFRONT_IBSCurrent "Electrical current into the 12V battery";
CM_ SG_ 609 VCFRONT_IBSVoltage "Voltage of the 12V battery";
CM_ SG_ 609 VCFRONT_reverseBatteryFault "Indicates a fault on the reverse battery eFuse.";
CM_ SG_ 609 VCFRONT_LVBatterySupported "Indicates whether the Low Voltage (LV) battery is being supported.";
CM_ SG_ 609 VCFRONT_LVBatteryCannotSupportVe "Front body controller: LV battery cannot support vehicle";
CM_ SG_ 609 VCFRONT_goodTemp12VforUpdate "Front body controller: good temp12 vfor update";
CM_ SG_ 609 VCFRONT_12VBatteryTargetVoltage "Reports the target Low Voltage (LV) battery voltage.";
CM_ SG_ 609 VCFRONT_IBSTemperature "Front body controller: IBS temperature";
CM_ SG_ 609 VCFRONT_currentSensorMismatchLea "Front body controller: current sensor mismatch leaky bkt pct DBG";
CM_ SG_ 609 VCFRONT_LVBatteryEnergyRemaining "Reports the percentage of energy remaining in the Low Voltage (LV) battery.";
CM_ SG_ 609 VCFRONT_LVBatteryStatusForDrive "Indicates the Low Voltage (LV) battery health status as it pertains to drive readiness. May trigger a Graceful Power Off (GPO) and block drive.";
CM_ SG_ 609 VCFRONT_LVBatteryType "Reports the type of Low Voltage (LV) battery that the firmware is configured for.";
CM_ SG_ 609 VCFRONT_resistanceEstimationNeed "Indication that the conditions which require a resistance estimation test to be performed have been met";
CM_ SG_ 609 VCFRONT_IBSVoltageFiltered "Measures the filtered voltage of the Low Voltage (LV) bus.";
CM_ SG_ 609 VCFRONT_LVBMS_LVBusVoltageSource "Reports the source of the Low Voltage (LV) bus voltage used for the Low Voltage Battery Management System (LVBMS).";
CM_ SG_ 609 VCFRONT_LVBMS_LVPackCurrentSourc "Reports the source of the Low Voltage (LV) pack current used for LV battery charge regulation.";
CM_ SG_ 609 VCFRONT_LVBatterySupportRqrdTrig "Reports what caused the Low Voltage (LV) battery support required trigger when the vehicle wakes to charge.";
CM_ SG_ 609 VCFRONT_goodForPCSPowerCycleLeak "Front body controller: good for PCS power cycle leaky bkt DBG";
CM_ SG_ 609 VCFRONT_LVBusControlsFutile "Indicates that a required condition is not met for the Low Voltage (LV) bus controllers to operate properly.";
CM_ SG_ 609 VCFRONT_resistanceEstimatio_0001 "Front body controller: resistance estimation test valid";
CM_ SG_ 609 VCFRONT_resistanceEstimatio_0002 "Front body controller: resistance estimation tests expended";
CM_ SG_ 609 VCFRONT_goodLVChargeForUpdate "Indicates that the Low Voltage (LV) battery charge is sufficient to permit an Over-The-Air (OTA) update.";
CM_ SG_ 609 VCFRONT_opportunisticDCRTestNeed "Front body controller: opportunistic DCR test needed";
CM_ SG_ 609 VCFRONT_voltageProfile "Indicates which voltage profile is used to support the 12V battery";
CM_ SG_ 609 VCFRONT_IBSAmpHours "Measures the energy state of the Low Voltage (LV) battery in amp hours.";
CM_ SG_ 609 VCFRONT_IBSVoltageRawDBG "Front body controller: IBS voltage raw DBG";
CM_ SG_ 609 VCFRONT_LVBatteryLINCommsDetecte "Front body controller: LV battery LIN comms detected DBG";
CM_ SG_ 609 VCFRONT_voltageSensorMismatchLea "Front body controller: voltage sensor mismatch leaky bkt pct DBG";
CM_ SG_ 609 VCFRONT_LVBatteryFctryLimOverrid "Front body controller: LV battery fctry lim override ok";
CM_ SG_ 609 VCFRONT_LVBatterySPICommsDetecte "Front body controller: LV battery SPI comms detected DBG";
CM_ SG_ 609 VCFRONT_targetCurrent "Reports the target current set by the Low Voltage Battery Management System (LVBMS).";
CM_ SG_ 609 VCFRONT_PCSMia "Indicates that the Power Conversion System (PCS) is not communicating on CAN.";
CM_ SG_ 609 VCFRONT_chargeNeeded "Indicates that the Low Voltage (LV) battery needs to be charged.";
CM_ SG_ 609 VCFRONT_voltageControlLoopIntegr "Front body controller: voltage control loop integration val";
CM_ SG_ 609 VCFRONT_currentControlLoopIntegr "Front body controller: current control loop integration val";
CM_ BO_ 1847 "Front body controller message: LVBMS info";
CM_ SG_ 1847 VCFRONT_LVBMS_InfoIndex "Front body controller: LVBMS info index";
CM_ SG_ 1847 VCFRONT_LVBMS_PcbaId "Front body controller: LVBMS pcba id";
CM_ SG_ 1847 VCFRONT_LVBMS_AssemblyId "Front body controller: LVBMS assembly id";
CM_ SG_ 1847 VCFRONT_LVBMS_SubUsageId "LVBMS Sub Usage ID";
CM_ SG_ 1847 VCFRONT_LVBMS_UsageId "Front body controller: LVBMS usage id";
CM_ SG_ 1847 VCFRONT_LVBMS_AppCRC "LVBMS application cyclic redundancy check";
CM_ SG_ 1847 VCFRONT_LVBMS_FWBuildType "Front body controller: LVBMS FW build type";
CM_ BO_ 2017 "Front body controller message: LV health";
CM_ SG_ 2017 VCFRONT_LVHealthStatus "Health status of the LV system";
CM_ SG_ 2017 VCFRONT_LVStatusForDrive "Front body controller: LV status for drive";
CM_ SG_ 2017 VCFRONT_LVPowerSecondsToSafeHarb "Reports the amount of time (in seconds) the Low Voltage (LV) power system indicates the vehicle has to achieve safe harbor.";
CM_ SG_ 2017 VCFRONT_LVHealthCounter "Front body controller: LV health counter";
CM_ SG_ 2017 VCFRONT_LVHealthChecksum "Front body controller: LV health checksum";
CM_ BO_ 2016 "Front body controller message: LV health debug";
CM_ SG_ 2016 VCFRONT_LVHealthDebugIndex "Front body controller: LV health debug index";
CM_ SG_ 2016 VCFRONT_LVHEALTH_placeholder "Whether the LV health has determined that the <placeholder>";
CM_ SG_ 2016 VCFRONT_LVHEALTH_activeDecelEner "Whether the VCFRONT cannot confirm that the battery has sufficient energy to support an active decel scenario";
CM_ SG_ 2016 VCFRONT_LVHEALTH_criticalPullove "Whether the VCFRONT cannot confirm that the battery has sufficient energy to support a critical pullover scenario";
CM_ SG_ 2016 VCFRONT_LVHEALTH_revBattEFuseOff "Whether the LV health has determined that the LVBMB EFuse has opened";
CM_ SG_ 2016 VCFRONT_LVHEALTH_LVBMBEFuseOpen "Whether the LV health has determined that the LVBMB EFuse has opened";
CM_ SG_ 2016 VCFRONT_LVHEALTH_lvBatteryCommsM "Whether the LV health has determined that LV battery communications are missing";
CM_ SG_ 2016 VCFRONT_LVHEALTH_pcsEFuseOff "Whether VCFRONT has determined that the PCS eFuse is off or faulted when it's needed to be on";
CM_ SG_ 2016 VCFRONT_LVHEALTH_pcsNotActive "Whether the LV health has determined that the PCS is not actively providing LV support";
CM_ SG_ 2016 VCFRONT_LVHEALTH_pcsMIA "Whether the LV health has determined that messages are missing from PCS critical for determining health";
CM_ SG_ 2016 VCFRONT_LVHEALTH_IBSMIA "Whether the LV health has determined that the INA228 LV battery sensor signals are invalid or not yet configured";
CM_ SG_ 2016 VCFRONT_LVHEALTH_LVBatteryElecDi "Whether the VCFRONT has determined that the LV battery is electrically disconnected";
CM_ SG_ 2016 VCFRONT_LVHEALTH_LVBatteryE_0001 "Whether the VCFRONT has determined that the LV battery electrical connection status has been unknown for too long";
CM_ SG_ 2016 VCFRONT_LVHEALTH_pcsOpenCircuit "Whether VCFRONT has determined that the electrical connection between the PCS and VCFRONT is disconnected";
CM_ SG_ 2016 VCFRONT_LVHEALTH_activeDecelPowe "Whether the VCFRONT cannot confirm that the battery has sufficient power to support a active decel scenario";
CM_ SG_ 2016 VCFRONT_LVHEALTH_lvBatteryCapabi "Whether the LV health has determined that LV battery power/energy capability estimation accuracy is too low";
CM_ SG_ 2016 VCFRONT_LVHEALTH_lvBatteryConfig "Whether the LV health has determined that LV battery configuration is incorrect";
CM_ SG_ 2016 VCFRONT_LVHEALTH_lvBatteryImpeda "Whether the LV health has determined that LV battery impedance is too high";
CM_ BO_ 545 "Front body controller message: LV power state";
CM_ SG_ 545 VCFRONT_LVPowerStateIndex "Front body controller: LV power state index";
CM_ SG_ 545 VCFRONT_vehiclePowerState "Front body controller: vehicle power state";
CM_ SG_ 545 VCFRONT_inAccessoryPlus "Front body controller: in accessory plus";
CM_ SG_ 545 VCFRONT_LVShuttingDown "Front body controller: LV shutting down";
CM_ SG_ 545 VCFRONT_LVPowerStateCounter "Front body controller: LV power state counter";
CM_ SG_ 545 VCFRONT_LVPowerStateChecksum "Front body controller: LV power state checksum";
CM_ SG_ 545 VCFRONT_cpLVRequest "Front body controller: cp LV request";
CM_ SG_ 545 VCFRONT_epasLVState "Front body controller: epas LV state";
CM_ SG_ 545 VCFRONT_hvcLVRequest "Front body controller: hvc LV request";
CM_ SG_ 545 VCFRONT_tasLVState "Front body controller: tas LV state";
CM_ SG_ 545 VCFRONT_pcsLVState "Front body controller: pcs LV state";
CM_ SG_ 545 VCFRONT_CMPDLVState "Front body controller: CMPDLV state";
CM_ SG_ 545 VCFRONT_hcmlLVState "Front body controller: hcml LV state";
CM_ SG_ 545 VCFRONT_hcmrLVState "Front body controller: hcmr LV state";
CM_ SG_ 545 VCFRONT_MCUAudioLVState "Front body controller: MCU audio LV state";
CM_ SG_ 545 VCFRONT_espValveLVState "Front body controller: esp valve LV state";
CM_ SG_ 545 VCFRONT_MCUGraphicsLVState "Front body controller: MCU graphics LV state";
CM_ SG_ 545 VC_dcdcSupportRequest "Front body controller: dcdc support request";
CM_ SG_ 545 VC_hvStateRequest "Reports the request for the High Voltage (HV) system state.";
CM_ SG_ 545 VC_persistAccPowerRequestOverrid "Front body controller: persist acc power request overridden";
CM_ SG_ 545 VC_accPortPowerRequest "Front body controller: acc port power request";
CM_ SG_ 545 VC_persistAccPortPowerState "Front body controller: persist acc port power state";
CM_ BO_ 700 "Front body controller message: LV thermal motors10 hz";
CM_ SG_ 700 VCFRONT_LVThermalMotorsIndex "Front body controller: LV thermal motors index";
CM_ SG_ 700 VCFRONT_radiatorFanState "Radiator Fan motor controller state";
CM_ SG_ 700 VCFRONT_radiatorFanTorque "Radiator Fan motor torque";
CM_ SG_ 700 VCFRONT_radiatorFanIDc "Radiator Fan DC current";
CM_ SG_ 700 VCFRONT_mlxLINCurrentSchedule "Currently set schedule for MLX LIN bus";
CM_ SG_ 700 VCFRONT_pumpPowertrainState "Powertrain Pump motor controller state";
CM_ SG_ 700 VCFRONT_pumpPowertrainTorque "Powertrain Pump motor torque";
CM_ SG_ 700 VCFRONT_pumpPowertrainIDc "Powertrain Pump DC current";
CM_ SG_ 700 VCFRONT_pumpBatteryState "Battery Pump motor controller state";
CM_ SG_ 700 VCFRONT_pumpBatteryTorque "Battery Pump motor torque";
CM_ SG_ 700 VCFRONT_pumpBatteryIDc "Battery Pump DC current";
CM_ BO_ 1332 "Front body controller message: alert log";
CM_ SG_ 1332 VCFRONT_alertID "Front body controller: alert ID";
CM_ SG_ 1332 VCFRONT_alertState "Front body controller: alert state";
CM_ SG_ 1332 VCFRONT_a001_InternalWatchdog "Front body controller: a001 internal watchdog";
CM_ SG_ 1332 VCFRONT_a002_CPUUndervoltage "Front body controller: a002 CPU undervoltage";
CM_ SG_ 1332 VCFRONT_a002_PowerOnReset "Front body controller: a002 power on reset";
CM_ SG_ 1332 VCFRONT_a004_APPWatchdogFaultOrM "Front body controller: a004 APP watchdog fault or MIA";
CM_ SG_ 1332 VCFRONT_a004_DASHighLowBeamDecis "Front body controller: a004 DAS high low beam decision SNA";
CM_ SG_ 1332 VCFRONT_a004_DASAdaptiveHighBeam "Front body controller: a004 DAS adaptive high beam fault";
CM_ SG_ 1332 VCFRONT_a004_DASMatrixColumnMsgM "Front body controller: a004 DAS matrix column msg MIA";
CM_ SG_ 1332 VCFRONT_a004_DASBendAngleMsgMIA "Front body controller: a004 DAS bend angle msg MIA";
CM_ SG_ 1332 VCFRONT_a004_EPAS3PNotInSpecOrMI "Front body controller: a004 EPAS3 p not in spec or MIA";
CM_ SG_ 1332 VCFRONT_a008_APPWatchdogFaultOrM "Front body controller: a008 APP watchdog fault or MIA";
CM_ SG_ 1332 VCFRONT_a008_DASHighLowBeamDecis "Front body controller: a008 DAS high low beam decision SNA";
CM_ SG_ 1332 VCFRONT_a008_DASAdaptiveHighBeam "Front body controller: a008 DAS adaptive high beam fault";
CM_ SG_ 1332 VCFRONT_a008_DASMatrixColumnMsgM "Front body controller: a008 DAS matrix column msg MIA";
CM_ SG_ 1332 VCFRONT_a008_DASBendAngleMsgMIA "Front body controller: a008 DAS bend angle msg MIA";
CM_ SG_ 1332 VCFRONT_a008_EPAS3PNotInSpecOrMI "Front body controller: a008 EPAS3 p not in spec or MIA";
CM_ SG_ 1332 VCFRONT_a010_UnderVoltageDetecte "Front body controller: a010 under voltage detected";
CM_ SG_ 1332 VCFRONT_a010_UnderVoltageTimeout "Front body controller: a010 under voltage timeout";
CM_ SG_ 1332 VCFRONT_a015_NVMMMemOverflow "Front body controller: a015 NVMM mem overflow";
CM_ SG_ 1332 VCFRONT_a015_NVMMFilesystemError "Front body controller: a015 NVMM filesystem error";
CM_ SG_ 1332 VCFRONT_a015_NVMMRecordIDError "Front body controller: a015 NVMM record ID error";
CM_ SG_ 1332 VCFRONT_a057_VEH_cpControl "Front body controller: a057 VEH cp control";
CM_ SG_ 1332 VCFRONT_a059_voltageDrop "Front body controller: a059 voltage drop";
CM_ SG_ 1332 VCFRONT_a059_resistanceEstimate "Front body controller: a059 resistance estimate";
CM_ SG_ 1332 VCFRONT_a059_current "Front body controller: a059 current";
CM_ SG_ 1332 VCFRONT_a063_switchChannel "Front body controller: a063 switch channel";
CM_ SG_ 1332 VCFRONT_a063_switchType "Front body controller: a063 switch type";
CM_ SG_ 1332 VCFRONT_a063_ADCVoltage "Front body controller: a063 ADC voltage";
CM_ SG_ 1332 VCFRONT_a063_disconnected "Front body controller: a063 disconnected";
CM_ SG_ 1332 VCFRONT_a063_indeterminate "Front body controller: a063 indeterminate";
CM_ SG_ 1332 VCFRONT_a063_stuckActive "Front body controller: a063 stuck active";
CM_ SG_ 1332 VCFRONT_a063_faulted "Front body controller: a063 faulted";
CM_ SG_ 1332 VCFRONT_a082_RIPC_epbPrivateStat "Front body controller: a082 RIPC epb private state";
CM_ SG_ 1332 VCFRONT_a082_RIPC_remoteHSD "Front body controller: a082 RIPC remote HSD";
CM_ SG_ 1332 VCFRONT_a082_RIPC_railStatus "Front body controller: a082 RIPC rail status";
CM_ SG_ 1332 VCFRONT_a082_RIPC_remoteMux "Front body controller: a082 RIPC remote mux";
CM_ SG_ 1332 VCFRONT_a083_LIPC_epbPrivateStat "Front body controller: a083 LIPC epb private state";
CM_ SG_ 1332 VCFRONT_a083_LIPC_remoteHSD "Front body controller: a083 LIPC remote HSD";
CM_ SG_ 1332 VCFRONT_a083_LIPC_railStatus "Front body controller: a083 LIPC rail status";
CM_ SG_ 1332 VCFRONT_a083_LIPC_HSDFaults "Front body controller: a083 LIPC HSD faults";
CM_ SG_ 1332 VCFRONT_a084_CH_StatusC "Front body controller: a084 CH status c";
CM_ SG_ 1332 VCFRONT_a085_PARTY_buttonStatus "Front body controller: a085 PARTY button status";
CM_ SG_ 1332 VCFRONT_a086_VEH_LVBMS_statusHig "Front body controller: a086 VEH LVBMS status high";
CM_ SG_ 1332 VCFRONT_a086_VEH_LVBMS_statusLow "Front body controller: a086 VEH LVBMS status low";
CM_ SG_ 1332 VCFRONT_a086_VEH_status "Front body controller: a086 VEH status";
CM_ SG_ 1332 VCFRONT_a086_VEH_12VBatteryStatu "Front body controller: a086 VEH 12 v battery status";
CM_ SG_ 1332 VCFRONT_a086_VEH_LVPowerState "Front body controller: a086 VEH LV power state";
CM_ SG_ 1332 VCFRONT_a086_VEH_lightStatus "Front body controller: a086 VEH light status";
CM_ SG_ 1332 VCFRONT_a086_VEH_systemStatus "Front body controller: a086 VEH system status";
CM_ SG_ 1332 VCFRONT_a086_VEH_thermalStatus "Front body controller: a086 VEH thermal status";
CM_ SG_ 1332 VCFRONT_a086_VEH_vehNm "Front body controller: a086 VEH veh nm";
CM_ SG_ 1332 VCFRONT_a087_VEH_temperature "Front body controller: a087 VEH temperature";
CM_ SG_ 1332 VCFRONT_a087_VEH_thermalControl "Front body controller: a087 VEH thermal control";
CM_ SG_ 1332 VCFRONT_a087_VEH_torque "Front body controller: a087 VEH torque";
CM_ SG_ 1332 VCFRONT_a087_VEH_status "Front body controller: a087 VEH status";
CM_ SG_ 1332 VCFRONT_a087_PARTY_torque "Front body controller: a087 PARTY torque";
CM_ SG_ 1332 VCFRONT_a087_PARTY_status "Front body controller: a087 PARTY status";
CM_ SG_ 1332 VCFRONT_a087_PARTY_temperature "Front body controller: a087 PARTY temperature";
CM_ SG_ 1332 VCFRONT_a087_PARTY_thermalContro "Front body controller: a087 PARTY thermal control";
CM_ SG_ 1332 VCFRONT_a088_VEH_temperature "Front body controller: a088 VEH temperature";
CM_ SG_ 1332 VCFRONT_a088_VEH_thermalControl "Front body controller: a088 VEH thermal control";
CM_ SG_ 1332 VCFRONT_a088_VEH_torque "Front body controller: a088 VEH torque";
CM_ SG_ 1332 VCFRONT_a088_VEH_status "Front body controller: a088 VEH status";
CM_ SG_ 1332 VCFRONT_a088_PARTY_torque "Front body controller: a088 PARTY torque";
CM_ SG_ 1332 VCFRONT_a088_PARTY_status "Front body controller: a088 PARTY status";
CM_ SG_ 1332 VCFRONT_a088_PARTY_temperature "Front body controller: a088 PARTY temperature";
CM_ SG_ 1332 VCFRONT_a088_PARTY_thermalContro "Front body controller: a088 PARTY thermal control";
CM_ SG_ 1332 VCFRONT_a089_PARTY_party1 "Front body controller: a089 PARTY party1";
CM_ SG_ 1332 VCFRONT_a089_PARTY_status "Front body controller: a089 PARTY status";
CM_ SG_ 1332 VCFRONT_a089_VEH_status "Front body controller: a089 VEH status";
CM_ SG_ 1332 VCFRONT_a089_BDY_party1 "Front body controller: a089 BDY party1";
CM_ SG_ 1332 VCFRONT_a089_BDY_status "Front body controller: a089 BDY status";
CM_ SG_ 1332 VCFRONT_a089_CH_status "Front body controller: a089 CH status";
CM_ SG_ 1332 VCFRONT_a089_CH_party1 "Front body controller: a089 CH party1";
CM_ SG_ 1332 VCFRONT_a089_CH_party3 "Front body controller: a089 CH party3";
CM_ SG_ 1332 VCFRONT_a089_VEH_party1 "Front body controller: a089 VEH party1";
CM_ SG_ 1332 VCFRONT_a089_VEH_party3 "Front body controller: a089 VEH party3";
CM_ SG_ 1332 VCFRONT_a091_VEH_faultsAndExtras "Front body controller: a091 VEH faults and extras";
CM_ SG_ 1332 VCFRONT_a091_VEH_info "Front body controller: a091 VEH info";
CM_ SG_ 1332 VCFRONT_a091_VEH_state "Front body controller: a091 VEH state";
CM_ SG_ 1332 VCFRONT_a092_VEH_restraintStatus "Front body controller: a092 VEH restraint status";
CM_ SG_ 1332 VCFRONT_a092_VEH_switchStatus "Front body controller: a092 VEH switch status";
CM_ SG_ 1332 VCFRONT_a092_VEH_seatStatus2 "Front body controller: a092 VEH seat status2";
CM_ SG_ 1332 VCFRONT_a092_VEH_vehNm "Front body controller: a092 VEH veh nm";
CM_ SG_ 1332 VCFRONT_a093_VEH_restraintStatus "Front body controller: a093 VEH restraint status";
CM_ SG_ 1332 VCFRONT_a093_VEH_switchStatus "Front body controller: a093 VEH switch status";
CM_ SG_ 1332 VCFRONT_a093_VEH_seatStatus2 "Front body controller: a093 VEH seat status2";
CM_ SG_ 1332 VCFRONT_a093_VEH_vehNm "Front body controller: a093 VEH veh nm";
CM_ SG_ 1332 VCFRONT_a094_VEH_sysStatus "Front body controller: a094 VEH sys status";
CM_ SG_ 1332 VCFRONT_a094_PARTY_sysStatus "Front body controller: a094 PARTY sys status";
CM_ SG_ 1332 VCFRONT_a095_PT_ptNm "Front body controller: a095 PT pt nm";
CM_ SG_ 1332 VCFRONT_a095_PT_status "Front body controller: a095 PT status";
CM_ SG_ 1332 VCFRONT_a096_VEH_status "Front body controller: a096 VEH status";
CM_ SG_ 1332 VCFRONT_a096_CH_status "Front body controller: a096 CH status";
CM_ SG_ 1332 VCFRONT_a098_CH_torque "Front body controller: a098 CH torque";
CM_ SG_ 1332 VCFRONT_a098_VEH_hvStatus "Front body controller: a098 VEH hv status";
CM_ SG_ 1332 VCFRONT_a098_VEH_status "Front body controller: a098 VEH status";
CM_ SG_ 1332 VCFRONT_a098_VEH_thermalControl "Front body controller: a098 VEH thermal control";
CM_ SG_ 1332 VCFRONT_a098_VEH_temperature "Front body controller: a098 VEH temperature";
CM_ SG_ 1332 VCFRONT_a098_VEH_torque "Front body controller: a098 VEH torque";
CM_ SG_ 1332 VCFRONT_a098_PARTY_status "Front body controller: a098 PARTY status";
CM_ SG_ 1332 VCFRONT_a098_PARTY_temperature "Front body controller: a098 PARTY temperature";
CM_ SG_ 1332 VCFRONT_a098_PARTY_thermalContro "Front body controller: a098 PARTY thermal control";
CM_ SG_ 1332 VCFRONT_a098_PARTY_torque "Front body controller: a098 PARTY torque";
CM_ SG_ 1332 VCFRONT_a098_PT_thermalControl "Front body controller: a098 PT thermal control";
CM_ SG_ 1332 VCFRONT_a098_PT_temperature "Front body controller: a098 PT temperature";
CM_ SG_ 1332 VCFRONT_a099_VEH_oocStatus "Front body controller: a099 VEH ooc status";
CM_ SG_ 1332 VCFRONT_a100_VEH "Front body controller: a100 VEH";
CM_ SG_ 1332 VCFRONT_a100_PARTY "Front body controller: a100 PARTY";
CM_ SG_ 1332 VCFRONT_a100_PT "Front body controller: a100 PT";
CM_ SG_ 1332 VCFRONT_a100_CH "Front body controller: a100 CH";
CM_ SG_ 1332 VCFRONT_a100_OBD "Front body controller: a100 OBD";
CM_ SG_ 1332 VCFRONT_a101_VEH_state "Front body controller: a101 VEH state";
CM_ SG_ 1332 VCFRONT_a101_PARTY_locState "Front body controller: a101 PARTY loc state";
CM_ SG_ 1332 VCFRONT_a101_LIPC_externalWatchd "Front body controller: a101 LIPC external watchdog heart beat";
CM_ SG_ 1332 VCFRONT_a101_VEH_locState "Front body controller: a101 VEH loc state";
CM_ SG_ 1332 VCFRONT_a101_BDY_locState "Front body controller: a101 BDY loc state";
CM_ SG_ 1332 VCFRONT_a102_VEH_faultsAndExtras "Front body controller: a102 VEH faults and extras";
CM_ SG_ 1332 VCFRONT_a102_VEH_feedbackStatus "Front body controller: a102 VEH feedback status";
CM_ SG_ 1332 VCFRONT_a102_VEH_sensorStatus "Front body controller: a102 VEH sensor status";
CM_ SG_ 1332 VCFRONT_a102_VEH_rods "Front body controller: a102 VEH rods";
CM_ SG_ 1332 VCFRONT_a103_VEH_hvsNm "Front body controller: a103 VEH hvs nm";
CM_ SG_ 1332 VCFRONT_a103_VEH_vehNm "Front body controller: a103 VEH veh nm";
CM_ SG_ 1332 VCFRONT_a103_VEH_status "Front body controller: a103 VEH status";
CM_ SG_ 1332 VCFRONT_a103_PT_ptNm "Front body controller: a103 PT pt nm";
CM_ SG_ 1332 VCFRONT_a103_PT_status "Front body controller: a103 PT status";
CM_ SG_ 1332 VCFRONT_a103_VEH_evseStatus "Front body controller: a103 VEH evse status";
CM_ SG_ 1332 VCFRONT_a105_VEH_states "Front body controller: a105 VEH states";
CM_ SG_ 1332 VCFRONT_a105_VEH_chNm "Front body controller: a105 VEH ch nm";
CM_ SG_ 1332 VCFRONT_a105_VEH_dampingStates "Front body controller: a105 VEH damping states";
CM_ SG_ 1332 VCFRONT_a106_VEH_dcdcStatus "Front body controller: a106 VEH dcdc status";
CM_ SG_ 1332 VCFRONT_a106_VEH_thermalControl "Front body controller: a106 VEH thermal control";
CM_ SG_ 1332 VCFRONT_a106_VEH_thermalInterfac "Front body controller: a106 VEH thermal interface";
CM_ SG_ 1332 VCFRONT_a106_VEH_dcdcRailStatus "Front body controller: a106 VEH dcdc rail status";
CM_ SG_ 1332 VCFRONT_a106_CH_dcdcRailStatus "Front body controller: a106 CH dcdc rail status";
CM_ SG_ 1332 VCFRONT_a106_CH_alertMatrix "Front body controller: a106 CH alert matrix";
CM_ SG_ 1332 VCFRONT_a107_VEH_hvsNm "Front body controller: a107 VEH hvs nm";
CM_ SG_ 1332 VCFRONT_a107_VEH_vehNm "Front body controller: a107 VEH veh nm";
CM_ SG_ 1332 VCFRONT_a107_VEH_status "Front body controller: a107 VEH status";
CM_ SG_ 1332 VCFRONT_a107_VEH_thermalStatus "Front body controller: a107 VEH thermal status";
CM_ SG_ 1332 VCFRONT_a107_VEH_thermalStatus2 "Front body controller: a107 VEH thermal status2";
CM_ SG_ 1332 VCFRONT_a107_VEH_bmbMinMax "Front body controller: a107 VEH bmb min max";
CM_ SG_ 1332 VCFRONT_a107_VEH_powerAvailable "Front body controller: a107 VEH power available";
CM_ SG_ 1332 VCFRONT_a107_PT_ptNm "Front body controller: a107 PT pt nm";
CM_ SG_ 1332 VCFRONT_a107_PT_status "Front body controller: a107 PT status";
CM_ SG_ 1332 VCFRONT_a107_PT_thermalStatus "Front body controller: a107 PT thermal status";
CM_ SG_ 1332 VCFRONT_a107_PT_socStatus "Front body controller: a107 PT soc status";
CM_ SG_ 1332 VCFRONT_a107_VEH_socStatus "Front body controller: a107 VEH soc status";
CM_ SG_ 1332 VCFRONT_a107_VEH_packConfig "Front body controller: a107 VEH pack config";
CM_ SG_ 1332 VCFRONT_a107_VEH_energyStatus "Front body controller: a107 VEH energy status";
CM_ SG_ 1332 VCFRONT_a107_VEH_chargeInfo "Front body controller: a107 VEH charge info";
CM_ SG_ 1332 VCFRONT_a108_VEH_hvStatus "Front body controller: a108 VEH hv status";
CM_ SG_ 1332 VCFRONT_a108_VEH_temperature "Front body controller: a108 VEH temperature";
CM_ SG_ 1332 VCFRONT_a108_VEH_thermalControl "Front body controller: a108 VEH thermal control";
CM_ SG_ 1332 VCFRONT_a108_VEH_torque "Front body controller: a108 VEH torque";
CM_ SG_ 1332 VCFRONT_a108_VEH_status "Front body controller: a108 VEH status";
CM_ SG_ 1332 VCFRONT_a108_PARTY_torque "Front body controller: a108 PARTY torque";
CM_ SG_ 1332 VCFRONT_a108_PARTY_status "Front body controller: a108 PARTY status";
CM_ SG_ 1332 VCFRONT_a108_PARTY_temperature "Front body controller: a108 PARTY temperature";
CM_ SG_ 1332 VCFRONT_a108_PARTY_thermalContro "Front body controller: a108 PARTY thermal control";
CM_ SG_ 1332 VCFRONT_a108_PT_temperature "Front body controller: a108 PT temperature";
CM_ SG_ 1332 VCFRONT_a108_PT_thermalControl "Front body controller: a108 PT thermal control";
CM_ SG_ 1332 VCFRONT_a109_PARTY_status "Front body controller: a109 PARTY status";
CM_ SG_ 1332 VCFRONT_a109_PARTY_inertial2 "Front body controller: a109 PARTY inertial2";
CM_ SG_ 1332 VCFRONT_a109_PARTY_nearDeploy "Front body controller: a109 PARTY near deploy";
CM_ SG_ 1332 VCFRONT_a109_PARTY_collision "Front body controller: a109 PARTY collision";
CM_ SG_ 1332 VCFRONT_a109_VEH_status "Front body controller: a109 VEH status";
CM_ SG_ 1332 VCFRONT_a109_VEH_imuOffsets "Front body controller: a109 VEH imu offsets";
CM_ SG_ 1332 VCFRONT_a109_PARTY_inertial1 "Front body controller: a109 PARTY inertial1";
CM_ SG_ 1332 VCFRONT_a109_BDY_imuOffsets "Front body controller: a109 BDY imu offsets";
CM_ SG_ 1332 VCFRONT_a109_BDY_inertial1 "Front body controller: a109 BDY inertial1";
CM_ SG_ 1332 VCFRONT_a109_BDY_inertial2 "Front body controller: a109 BDY inertial2";
CM_ SG_ 1332 VCFRONT_a109_BDY_status "Front body controller: a109 BDY status";
CM_ SG_ 1332 VCFRONT_a109_VEH_inertial1 "Front body controller: a109 VEH inertial1";
CM_ SG_ 1332 VCFRONT_a109_VEH_inertial2 "Front body controller: a109 VEH inertial2";
CM_ SG_ 1332 VCFRONT_a109_CH_inertial1 "Front body controller: a109 CH inertial1";
CM_ SG_ 1332 VCFRONT_a109_CH_inertial2 "Front body controller: a109 CH inertial2";
CM_ SG_ 1332 VCFRONT_a109_CH_status "Front body controller: a109 CH status";
CM_ SG_ 1332 VCFRONT_a110_VEH_status "Front body controller: a110 VEH status";
CM_ SG_ 1332 VCFRONT_a110_VEH_carState "Front body controller: a110 VEH car state";
CM_ SG_ 1332 VCFRONT_a110_VEH_carConfig "Front body controller: a110 VEH car config";
CM_ SG_ 1332 VCFRONT_a110_VEH_time "Front body controller: a110 VEH time";
CM_ SG_ 1332 VCFRONT_a110_VEH_updateStatus "Front body controller: a110 VEH update status";
CM_ SG_ 1332 VCFRONT_a110_VEH_vehNm "Front body controller: a110 VEH veh nm";
CM_ SG_ 1332 VCFRONT_a110_VEH_mismatchFault "Front body controller: a110 VEH mismatch fault";
CM_ SG_ 1332 VCFRONT_a110_VEH_vin "Front body controller: a110 VEH vin";
CM_ SG_ 1332 VCFRONT_a110_VEH_bmpDebug "Front body controller: a110 VEH bmp debug";
CM_ SG_ 1332 VCFRONT_a110_VEH_gearControl "Front body controller: a110 VEH gear control";
CM_ SG_ 1332 VCFRONT_a110_VEH_canLogAvailabil "Front body controller: a110 VEH can log availability";
CM_ SG_ 1332 VCFRONT_a110_CH_airbagCutoffStat "Front body controller: a110 CH airbag cutoff status";
CM_ SG_ 1332 VCFRONT_a110_CH_carConfig "Front body controller: a110 CH car config";
CM_ SG_ 1332 VCFRONT_a110_CH_carState "Front body controller: a110 CH car state";
CM_ SG_ 1332 VCFRONT_a110_CH_vin "Front body controller: a110 CH vin";
CM_ SG_ 1332 VCFRONT_a110_CH_chNm "Front body controller: a110 CH ch nm";
CM_ SG_ 1332 VCFRONT_a110_CH_epochTimeGtw "Front body controller: a110 CH epoch time gtw";
CM_ SG_ 1332 VCFRONT_a111_VEH_internalStatus "Front body controller: a111 VEH internal status";
CM_ SG_ 1332 VCFRONT_a111_VEH_status "Front body controller: a111 VEH status";
CM_ SG_ 1332 VCFRONT_a111_VEH_vehNm "Front body controller: a111 VEH veh nm";
CM_ SG_ 1332 VCFRONT_a111_RIPC_LVPowerState "Front body controller: a111 RIPC LV power state";
CM_ SG_ 1332 VCFRONT_a111_RIPC_epbPrivateStat "Front body controller: a111 RIPC epb private state";
CM_ SG_ 1332 VCFRONT_a111_RIPC_railStatus "Front body controller: a111 RIPC rail status";
CM_ SG_ 1332 VCFRONT_a111_RIPC_remoteADC "Front body controller: a111 RIPC remote ADC";
CM_ SG_ 1332 VCFRONT_a111_RIPC_switchStatus "Front body controller: a111 RIPC switch status";
CM_ SG_ 1332 VCFRONT_a111_VEH_LVPowerState "Front body controller: a111 VEH LV power state";
CM_ SG_ 1332 VCFRONT_a111_VEH_seatStatus "Front body controller: a111 VEH seat status";
CM_ SG_ 1332 VCFRONT_a111_PARTY_status "Front body controller: a111 PARTY status";
CM_ SG_ 1332 VCFRONT_a111_CH_status "Front body controller: a111 CH status";
CM_ SG_ 1332 VCFRONT_a112_VEH_internalStatus "Front body controller: a112 VEH internal status";
CM_ SG_ 1332 VCFRONT_a112_VEH_status "Front body controller: a112 VEH status";
CM_ SG_ 1332 VCFRONT_a112_VEH_vehNm "Front body controller: a112 VEH veh nm";
CM_ SG_ 1332 VCFRONT_a112_LIPC_LVPowerState "Front body controller: a112 LIPC LV power state";
CM_ SG_ 1332 VCFRONT_a112_LIPC_epbPrivateStat "Front body controller: a112 LIPC epb private state";
CM_ SG_ 1332 VCFRONT_a112_LIPC_railStatus "Front body controller: a112 LIPC rail status";
CM_ SG_ 1332 VCFRONT_a112_LIPC_remoteADC "Front body controller: a112 LIPC remote ADC";
CM_ SG_ 1332 VCFRONT_a112_LIPC_switchStatus "Front body controller: a112 LIPC switch status";
CM_ SG_ 1332 VCFRONT_a112_VEH_LVPowerState "Front body controller: a112 VEH LV power state";
CM_ SG_ 1332 VCFRONT_a112_PARTY_status "Front body controller: a112 PARTY status";
CM_ SG_ 1332 VCFRONT_a112_CH_status "Front body controller: a112 CH status";
CM_ SG_ 1332 VCFRONT_a114_PARTY_status "Front body controller: a114 PARTY status";
CM_ SG_ 1332 VCFRONT_a114_PARTY_wheelSpeeds "Front body controller: a114 PARTY wheel speeds";
CM_ SG_ 1332 VCFRONT_a114_VEH_wheelSpeeds "Front body controller: a114 VEH wheel speeds";
CM_ SG_ 1332 VCFRONT_a114_CH_wheelSpeeds "Front body controller: a114 CH wheel speeds";
CM_ SG_ 1332 VCFRONT_a114_PARTY_party3 "Front body controller: a114 PARTY party3";
CM_ SG_ 1332 VCFRONT_a114_VEH_party3 "Front body controller: a114 VEH party3";
CM_ SG_ 1332 VCFRONT_a114_VEH_status "Front body controller: a114 VEH status";
CM_ SG_ 1332 VCFRONT_a114_PARTY_wheelRotation "Front body controller: a114 PARTY wheel rotation";
CM_ SG_ 1332 VCFRONT_a114_CH_wheelRotation "Front body controller: a114 CH wheel rotation";
CM_ SG_ 1332 VCFRONT_a114_VEH_wheelRotation "Front body controller: a114 VEH wheel rotation";
CM_ SG_ 1332 VCFRONT_a114_PARTY_brakeTorque "Front body controller: a114 PARTY brake torque";
CM_ SG_ 1332 VCFRONT_a114_PARTY_offsets "Front body controller: a114 PARTY offsets";
CM_ SG_ 1332 VCFRONT_a114_BDY_offsets "Front body controller: a114 BDY offsets";
CM_ SG_ 1332 VCFRONT_a114_BDY_party3 "Front body controller: a114 BDY party3";
CM_ SG_ 1332 VCFRONT_a114_BDY_status "Front body controller: a114 BDY status";
CM_ SG_ 1332 VCFRONT_a114_BDY_wheelRotation "Front body controller: a114 BDY wheel rotation";
CM_ SG_ 1332 VCFRONT_a114_BDY_wheelSpeeds "Front body controller: a114 BDY wheel speeds";
CM_ SG_ 1332 VCFRONT_a114_CH_party1 "Front body controller: a114 CH party1";
CM_ SG_ 1332 VCFRONT_a114_CH_party3 "Front body controller: a114 CH party3";
CM_ SG_ 1332 VCFRONT_a114_CH_status "Front body controller: a114 CH status";
CM_ SG_ 1332 VCFRONT_a115_VEH_vehNm "Front body controller: a115 VEH veh nm";
CM_ SG_ 1332 VCFRONT_a115_VEH_authentication "Front body controller: a115 VEH authentication";
CM_ SG_ 1332 VCFRONT_a115_VEH_BLEResetRequest "Front body controller: a115 VEH BLE reset request";
CM_ SG_ 1332 VCFRONT_a115_VEH_requests "Front body controller: a115 VEH requests";
CM_ SG_ 1332 VCFRONT_a115_VEH_requests2 "Front body controller: a115 VEH requests2";
CM_ SG_ 1332 VCFRONT_a115_REM_authentication "Front body controller: a115 REM authentication";
CM_ SG_ 1332 VCFRONT_a115_UI_corianderVehicle "Front body controller: a115 UI coriander vehicle control";
CM_ SG_ 1332 VCFRONT_a115_CH_TPMSDisplay "Front body controller: a115 CH TPMS display";
CM_ SG_ 1332 VCFRONT_a116_PARTY_epbmStatus "Front body controller: a116 PARTY epbm status";
CM_ SG_ 1332 VCFRONT_a116_VEH_vehNm "Front body controller: a116 VEH veh nm";
CM_ SG_ 1332 VCFRONT_a116_VEH_hvacRequest "Front body controller: a116 VEH hvac request";
CM_ SG_ 1332 VCFRONT_a116_VEH_hvacStatus "Front body controller: a116 VEH hvac status";
CM_ SG_ 1332 VCFRONT_a116_VEH_LVPowerState "Front body controller: a116 VEH LV power state";
CM_ SG_ 1332 VCFRONT_a116_VEH_lightStatus "Front body controller: a116 VEH light status";
CM_ SG_ 1332 VCFRONT_a116_VEH_seatStatus "Front body controller: a116 VEH seat status";
CM_ SG_ 1332 VCFRONT_a116_VEH_thsStatus "Front body controller: a116 VEH ths status";
CM_ SG_ 1332 VCFRONT_a116_VEH_doorStatus "Front body controller: a116 VEH door status";
CM_ SG_ 1332 VCFRONT_a116_VEH_seatHeatStatus "Front body controller: a116 VEH seat heat status";
CM_ SG_ 1332 VCFRONT_a116_VEH_restraintStatus "Front body controller: a116 VEH restraint status";
CM_ SG_ 1332 VCFRONT_a116_VEH_switchStatus "Front body controller: a116 VEH switch status";
CM_ SG_ 1332 VCFRONT_a116_VEH_logging1Hz "Front body controller: a116 VEH logging1 hz";
CM_ SG_ 1332 VCFRONT_a116_VEH_seatStatus2 "Front body controller: a116 VEH seat status2";
CM_ SG_ 1332 VCFRONT_a116_VEH_status "Front body controller: a116 VEH status";
CM_ SG_ 1332 VCFRONT_a116_VEH_thermalCommand "Front body controller: a116 VEH thermal command";
CM_ SG_ 1332 VCFRONT_a116_VEH_windowStatus "Front body controller: a116 VEH window status";
CM_ SG_ 1332 VCFRONT_a116_PARTY_restraintStat "Front body controller: a116 PARTY restraint status";
CM_ SG_ 1332 VCFRONT_a116_PARTY_doorStatus "Front body controller: a116 PARTY door status";
CM_ SG_ 1332 VCFRONT_a116_BDY_epbmStatus "Front body controller: a116 BDY epbm status";
CM_ SG_ 1332 VCFRONT_a116_BDY_restraintStatus "Front body controller: a116 BDY restraint status";
CM_ SG_ 1332 VCFRONT_a117_BDY_epbmStatus "Front body controller: a117 BDY epbm status";
CM_ SG_ 1332 VCFRONT_a117_BDY_restraintStatus "Front body controller: a117 BDY restraint status";
CM_ SG_ 1332 VCFRONT_a117_VEH_prndStatus "Front body controller: a117 VEH prnd status";
CM_ SG_ 1332 VCFRONT_a117_PARTY_epbmStatus "Front body controller: a117 PARTY epbm status";
CM_ SG_ 1332 VCFRONT_a117_VEH_vehNm "Front body controller: a117 VEH veh nm";
CM_ SG_ 1332 VCFRONT_a117_VEH_hvacBlowerFdb "Front body controller: a117 VEH hvac blower fdb";
CM_ SG_ 1332 VCFRONT_a117_VEH_LVPowerState "Front body controller: a117 VEH LV power state";
CM_ SG_ 1332 VCFRONT_a117_VEH_restraintStatus "Front body controller: a117 VEH restraint status";
CM_ SG_ 1332 VCFRONT_a117_VEH_lightStatus "Front body controller: a117 VEH light status";
CM_ SG_ 1332 VCFRONT_a117_VEH_seatStatus "Front body controller: a117 VEH seat status";
CM_ SG_ 1332 VCFRONT_a117_BDY_falconSwitchSta "Front body controller: a117 BDY falcon switch status";
CM_ SG_ 1332 VCFRONT_a117_VEH_doorStatus "Front body controller: a117 VEH door status";
CM_ SG_ 1332 VCFRONT_a117_VEH_doorStatus2 "Front body controller: a117 VEH door status2";
CM_ SG_ 1332 VCFRONT_a117_VEH_windowStatus "Front body controller: a117 VEH window status";
CM_ SG_ 1332 VCFRONT_a117_VEH_switchStatus "Front body controller: a117 VEH switch status";
CM_ SG_ 1332 VCFRONT_a117_VEH_intrusionSensor "Front body controller: a117 VEH intrusion sensor status";
CM_ SG_ 1332 VCFRONT_a117_VEH_liftgateStatus "Front body controller: a117 VEH liftgate status";
CM_ SG_ 1332 VCFRONT_a117_VEH_seatStatus2 "Front body controller: a117 VEH seat status2";
CM_ SG_ 1332 VCFRONT_a117_PARTY_restraintStat "Front body controller: a117 PARTY restraint status";
CM_ SG_ 1332 VCFRONT_a117_VEH_thermalStatus "Front body controller: a117 VEH thermal status";
CM_ SG_ 1332 VCFRONT_a117_PARTY_doorStatus "Front body controller: a117 PARTY door status";
CM_ SG_ 1332 VCFRONT_a117_VEH_status "Front body controller: a117 VEH status";
CM_ SG_ 1332 VCFRONT_a117_PARTY_prndStatus "Front body controller: a117 PARTY prnd status";
CM_ SG_ 1332 VCFRONT_a118_VEH_vehNm "Front body controller: a118 VEH veh nm";
CM_ SG_ 1332 VCFRONT_a118_VEH_lighting "Front body controller: a118 VEH lighting";
CM_ SG_ 1332 VCFRONT_a118_VEH_sensors "Front body controller: a118 VEH sensors";
CM_ SG_ 1332 VCFRONT_a118_VEH_status "Front body controller: a118 VEH status";
CM_ SG_ 1332 VCFRONT_a118_VEH_okToUseHighPwr "Front body controller: a118 VEH ok to use high pwr";
CM_ SG_ 1332 VCFRONT_a118_VEH_LVPowerState "Front body controller: a118 VEH LV power state";
CM_ SG_ 1332 VCFRONT_a118_VEH_coolant "Front body controller: a118 VEH coolant";
CM_ SG_ 1332 VCFRONT_a118_VEH_vehicleStatus "Front body controller: a118 VEH vehicle status";
CM_ SG_ 1332 VCFRONT_a118_VEH_12VBatteryStatu "Front body controller: a118 VEH 12 v battery status";
CM_ SG_ 1332 VCFRONT_a118_VEH_systemStatus "Front body controller: a118 VEH system status";
CM_ SG_ 1332 VCFRONT_a118_PARTY_LVPowerState "Front body controller: a118 PARTY LV power state";
CM_ SG_ 1332 VCFRONT_a118_PARTY_outputPowerSt "Front body controller: a118 PARTY output power status";
CM_ SG_ 1332 VCFRONT_a118_PARTY_vehicleTime "Front body controller: a118 PARTY vehicle time";
CM_ SG_ 1332 VCFRONT_a118_VEH_thermalCommand "Front body controller: a118 VEH thermal command";
CM_ SG_ 1332 VCFRONT_a118_CH_LVPowerState "Front body controller: a118 CH LV power state";
CM_ SG_ 1332 VCFRONT_a118_PARTY_sensors "Front body controller: a118 PARTY sensors";
CM_ SG_ 1332 VCFRONT_a118_CH_sensors "Front body controller: a118 CH sensors";
CM_ SG_ 1332 VCFRONT_a118_VEH_interNodeResist "Front body controller: a118 VEH inter node resistance";
CM_ SG_ 1332 VCFRONT_a118_CH_lighting "Front body controller: a118 CH lighting";
CM_ SG_ 1332 VCFRONT_a118_VEH_lightStatus "Front body controller: a118 VEH light status";
CM_ SG_ 1332 VCFRONT_a118_PARTY_vehNm "Front body controller: a118 PARTY veh nm";
CM_ SG_ 1332 VCFRONT_a118_CH_12VBatteryStatus "Front body controller: a118 CH 12 v battery status";
CM_ SG_ 1332 VCFRONT_a118_CH_LVBMS_statusHigh "Front body controller: a118 CH LVBMS status high";
CM_ SG_ 1332 VCFRONT_a118_CH_alertMatrix "Front body controller: a118 CH alert matrix";
CM_ SG_ 1332 VCFRONT_a118_BDY_outputPowerStat "Front body controller: a118 BDY output power status";
CM_ SG_ 1332 VCFRONT_a118_BDY_vehicleTime "Front body controller: a118 BDY vehicle time";
CM_ SG_ 1332 VCFRONT_a118_PARTY_AP_vehicleSta "Front body controller: a118 PARTY AP vehicle state1 hz muxed";
CM_ SG_ 1332 VCFRONT_a118_BDY_AP_vehicleState "Front body controller: a118 BDY AP vehicle state1 hz muxed";
CM_ SG_ 1332 VCFRONT_a119_VEH_steerAngle "Front body controller: a119 VEH steer angle";
CM_ SG_ 1332 VCFRONT_a119_VEH_leftStalk "Front body controller: a119 VEH left stalk";
CM_ SG_ 1332 VCFRONT_a119_VEH_rightStalk "Front body controller: a119 VEH right stalk";
CM_ SG_ 1332 VCFRONT_a119_PARTY_rightStalk "Front body controller: a119 PARTY right stalk";
CM_ SG_ 1332 VCFRONT_a119_CH_steerAngle "Front body controller: a119 CH steer angle";
CM_ SG_ 1332 VCFRONT_a119_PARTY_steerAngle "Front body controller: a119 PARTY steer angle";
CM_ SG_ 1332 VCFRONT_a120_PARTY_chassisCntl "Front body controller: a120 PARTY chassis cntl";
CM_ SG_ 1332 VCFRONT_a120_VEH_systemStatus "Front body controller: a120 VEH system status";
CM_ SG_ 1332 VCFRONT_a120_CH_chassisCntl "Front body controller: a120 CH chassis cntl";
CM_ SG_ 1332 VCFRONT_a120_PARTY_systemStatus "Front body controller: a120 PARTY system status";
CM_ SG_ 1332 VCFRONT_a120_PARTY_torque "Front body controller: a120 PARTY torque";
CM_ SG_ 1332 VCFRONT_a120_VEH_torque "Front body controller: a120 VEH torque";
CM_ SG_ 1332 VCFRONT_a120_PARTY_locStatus "Front body controller: a120 PARTY loc status";
CM_ SG_ 1332 VCFRONT_a120_PARTY_speed "Front body controller: a120 PARTY speed";
CM_ SG_ 1332 VCFRONT_a120_VEH_speed "Front body controller: a120 VEH speed";
CM_ SG_ 1332 VCFRONT_a120_PARTY_status "Front body controller: a120 PARTY status";
CM_ SG_ 1332 VCFRONT_a120_PT_speed "Front body controller: a120 PT speed";
CM_ SG_ 1332 VCFRONT_a120_PT_systemStatus "Front body controller: a120 PT system status";
CM_ SG_ 1332 VCFRONT_a120_PARTY_vehicleEstima "Front body controller: a120 PARTY vehicle estimates";
CM_ SG_ 1332 VCFRONT_a120_VEH_aggregatedAxleS "Front body controller: a120 VEH aggregated axle speed";
CM_ SG_ 1332 VCFRONT_a120_PARTY_aggregatedAxl "Front body controller: a120 PARTY aggregated axle speed";
CM_ SG_ 1332 VCFRONT_a120_VEH_systemPower "Front body controller: a120 VEH system power";
CM_ SG_ 1332 VCFRONT_a120_PT_systemPower "Front body controller: a120 PT system power";
CM_ SG_ 1332 VCFRONT_a120_PARTY_stalklessInte "Front body controller: a120 PARTY stalkless interfaces";
CM_ SG_ 1332 VCFRONT_a120_CH_speed "Front body controller: a120 CH speed";
CM_ SG_ 1332 VCFRONT_a120_VEH_estimatedBrakeT "Front body controller: a120 VEH estimated brake temp";
CM_ SG_ 1332 VCFRONT_a120_PARTY_prndControl "Front body controller: a120 PARTY prnd control";
CM_ SG_ 1332 VCFRONT_a120_PARTY_locStatus2 "Front body controller: a120 PARTY loc status2";
CM_ SG_ 1332 VCFRONT_a120_VEH_chassisCntl "Front body controller: a120 VEH chassis cntl";
CM_ SG_ 1332 VCFRONT_a120_VEH_locStatus "Front body controller: a120 VEH loc status";
CM_ SG_ 1332 VCFRONT_a120_VEH_locStatus2 "Front body controller: a120 VEH loc status2";
CM_ SG_ 1332 VCFRONT_a120_VEH_prndControl "Front body controller: a120 VEH prnd control";
CM_ SG_ 1332 VCFRONT_a120_VEH_vehicleEstimate "Front body controller: a120 VEH vehicle estimates";
CM_ SG_ 1332 VCFRONT_a121_overCurrentError "Front body controller: a121 over current error";
CM_ SG_ 1332 VCFRONT_a121_fetShortCircuit "Front body controller: a121 fet short circuit";
CM_ SG_ 1332 VCFRONT_a121_lockedRotor "Front body controller: a121 locked rotor";
CM_ SG_ 1332 VCFRONT_a122_junctionTempWarning "Front body controller: a122 junction temp warning";
CM_ SG_ 1332 VCFRONT_a122_junctionOverTemp "Front body controller: a122 junction over temp";
CM_ SG_ 1332 VCFRONT_a122_startUpOperation "Front body controller: a122 start up operation";
CM_ SG_ 1332 VCFRONT_a122_lossOfSpeedLock "Front body controller: a122 loss of speed lock";
CM_ SG_ 1332 VCFRONT_a122_vccUnderVoltage "Front body controller: a122 vcc under voltage";
CM_ SG_ 1332 VCFRONT_a123_overCurrentError "Front body controller: a123 over current error";
CM_ SG_ 1332 VCFRONT_a123_fetShortCircuit "Front body controller: a123 fet short circuit";
CM_ SG_ 1332 VCFRONT_a123_lockedRotor "Front body controller: a123 locked rotor";
CM_ SG_ 1332 VCFRONT_a124_junctionTempWarning "Front body controller: a124 junction temp warning";
CM_ SG_ 1332 VCFRONT_a124_junctionOverTemp "Front body controller: a124 junction over temp";
CM_ SG_ 1332 VCFRONT_a124_startUpOperation "Front body controller: a124 start up operation";
CM_ SG_ 1332 VCFRONT_a124_lossOfSpeedLock "Front body controller: a124 loss of speed lock";
CM_ SG_ 1332 VCFRONT_a124_vccUnderVoltage "Front body controller: a124 vcc under voltage";
CM_ SG_ 1332 VCFRONT_a125_overCurrentError "Front body controller: a125 over current error";
CM_ SG_ 1332 VCFRONT_a125_fetShortCircuit "Front body controller: a125 fet short circuit";
CM_ SG_ 1332 VCFRONT_a125_lockedRotor "Front body controller: a125 locked rotor";
CM_ SG_ 1332 VCFRONT_a126_junctionTempWarning "Front body controller: a126 junction temp warning";
CM_ SG_ 1332 VCFRONT_a126_junctionOverTemp "Front body controller: a126 junction over temp";
CM_ SG_ 1332 VCFRONT_a126_startUpOperation "Front body controller: a126 start up operation";
CM_ SG_ 1332 VCFRONT_a126_lossOfSpeedLock "Front body controller: a126 loss of speed lock";
CM_ SG_ 1332 VCFRONT_a126_vccUnderVoltage "Front body controller: a126 vcc under voltage";
CM_ SG_ 1332 VCFRONT_a127_vcleftEFuseCurrent "Front body controller: a127 vcleft e fuse current";
CM_ SG_ 1332 VCFRONT_a127_vcleftEFuseVoltage "Front body controller: a127 vcleft e fuse voltage";
CM_ SG_ 1332 VCFRONT_a127_vcleftEFuseTemp "Front body controller: a127 vcleft e fuse temp";
CM_ SG_ 1332 VCFRONT_a127_vcleftEFuseRemainin "Front body controller: a127 vcleft e fuse remaining retries";
CM_ SG_ 1332 VCFRONT_a128_vcrightEFuseCurrent "Front body controller: a128 vcright e fuse current";
CM_ SG_ 1332 VCFRONT_a128_vcrightEFuseVoltage "Front body controller: a128 vcright e fuse voltage";
CM_ SG_ 1332 VCFRONT_a128_vcrightEFuseTemp "Front body controller: a128 vcright e fuse temp";
CM_ SG_ 1332 VCFRONT_a128_vcrightEFuseRemaini "Front body controller: a128 vcright e fuse remaining retries";
CM_ SG_ 1332 VCFRONT_a129_pcsEFuseCurrent "Front body controller: a129 pcs e fuse current";
CM_ SG_ 1332 VCFRONT_a129_pcsEFuseVoltage "Front body controller: a129 pcs e fuse voltage";
CM_ SG_ 1332 VCFRONT_a129_pcsEFuseTemp "Front body controller: a129 pcs e fuse temp";
CM_ SG_ 1332 VCFRONT_a129_pcsEFuseRemainingRe "Front body controller: a129 pcs e fuse remaining retries";
CM_ SG_ 1332 VCFRONT_a130_epas3pEFuseCurrent "Front body controller: a130 epas3p e fuse current";
CM_ SG_ 1332 VCFRONT_a130_epas3pEFuseVoltage "Front body controller: a130 epas3p e fuse voltage";
CM_ SG_ 1332 VCFRONT_a130_epas3pEFuseTemp "Front body controller: a130 epas3p e fuse temp";
CM_ SG_ 1332 VCFRONT_a131_epas3sEFuseCurrent "Front body controller: a131 epas3s e fuse current";
CM_ SG_ 1332 VCFRONT_a131_epas3sEFuseVoltage "Front body controller: a131 epas3s e fuse voltage";
CM_ SG_ 1332 VCFRONT_a131_epas3sEFuseTemp "Front body controller: a131 epas3s e fuse temp";
CM_ SG_ 1332 VCFRONT_a132_iBoosterCurrent "Front body controller: a132 i booster current";
CM_ SG_ 1332 VCFRONT_a132_iBoosterVoltage "Front body controller: a132 i booster voltage";
CM_ SG_ 1332 VCFRONT_a132_iBoosterEFuseTemp "Front body controller: a132 i booster e fuse temp";
CM_ SG_ 1332 VCFRONT_a133_espEFuseCurrent "Front body controller: a133 esp e fuse current";
CM_ SG_ 1332 VCFRONT_a133_espEFuseVoltage "Front body controller: a133 esp e fuse voltage";
CM_ SG_ 1332 VCFRONT_a133_espEFuseTemp "Front body controller: a133 esp e fuse temp";
CM_ SG_ 1332 VCFRONT_a134_fusedHighCurrent "Front body controller: a134 fused high current";
CM_ SG_ 1332 VCFRONT_a134_fusedHighVoltage "Front body controller: a134 fused high voltage";
CM_ SG_ 1332 VCFRONT_a134_fusedHighTemp "Front body controller: a134 fused high temp";
CM_ SG_ 1332 VCFRONT_a134_vbatFusedEFuseRemai "Front body controller: a134 vbat fused e fuse remaining retries";
CM_ SG_ 1332 VCFRONT_a136_snsShortCircuit "Front body controller: a136 sns short circuit";
CM_ SG_ 1332 VCFRONT_a136_snsDisconnect "Front body controller: a136 sns disconnect";
CM_ SG_ 1332 VCFRONT_a136_snsRateChangeUp "Front body controller: a136 sns rate change up";
CM_ SG_ 1332 VCFRONT_a136_snsRateChangeDown "Front body controller: a136 sns rate change down";
CM_ SG_ 1332 VCFRONT_a137_snsShortCircuit "Front body controller: a137 sns short circuit";
CM_ SG_ 1332 VCFRONT_a137_snsDisconnect "Front body controller: a137 sns disconnect";
CM_ SG_ 1332 VCFRONT_a137_snsRateChangeUp "Front body controller: a137 sns rate change up";
CM_ SG_ 1332 VCFRONT_a137_snsRateChangeDown "Front body controller: a137 sns rate change down";
CM_ SG_ 1332 VCFRONT_a138_snsShortCircuit "Front body controller: a138 sns short circuit";
CM_ SG_ 1332 VCFRONT_a138_snsDisconnect "Front body controller: a138 sns disconnect";
CM_ SG_ 1332 VCFRONT_a138_snsRateChangeUp "Front body controller: a138 sns rate change up";
CM_ SG_ 1332 VCFRONT_a138_snsRateChangeDown "Front body controller: a138 sns rate change down";
CM_ SG_ 1332 VCFRONT_a139_snsShortCircuit "Front body controller: a139 sns short circuit";
CM_ SG_ 1332 VCFRONT_a139_snsDisconnect "Front body controller: a139 sns disconnect";
CM_ SG_ 1332 VCFRONT_a139_snsRateChangeUp "Front body controller: a139 sns rate change up";
CM_ SG_ 1332 VCFRONT_a139_snsRateChangeDown "Front body controller: a139 sns rate change down";
CM_ SG_ 1332 VCFRONT_a140_snsShortCircuit "Front body controller: a140 sns short circuit";
CM_ SG_ 1332 VCFRONT_a140_snsDisconnect "Front body controller: a140 sns disconnect";
CM_ SG_ 1332 VCFRONT_a140_snsRateChangeUp "Front body controller: a140 sns rate change up";
CM_ SG_ 1332 VCFRONT_a140_snsRateChangeDown "Front body controller: a140 sns rate change down";
CM_ SG_ 1332 VCFRONT_a141_snsShortCircuit "Front body controller: a141 sns short circuit";
CM_ SG_ 1332 VCFRONT_a141_snsDisconnect "Front body controller: a141 sns disconnect";
CM_ SG_ 1332 VCFRONT_a141_snsRateChangeUp "Front body controller: a141 sns rate change up";
CM_ SG_ 1332 VCFRONT_a141_snsRateChangeDown "Front body controller: a141 sns rate change down";
CM_ SG_ 1332 VCFRONT_a142_driverState "Front body controller: a142 driver state";
CM_ SG_ 1332 VCFRONT_a142_driverThermWarn "Front body controller: a142 driver therm warn";
CM_ SG_ 1332 VCFRONT_a142_driverThermShutdown "Front body controller: a142 driver therm shutdown";
CM_ SG_ 1332 VCFRONT_a142_undervoltage "Front body controller: a142 undervoltage";
CM_ SG_ 1332 VCFRONT_a142_chargePumpUndervolt "Front body controller: a142 charge pump undervoltage";
CM_ SG_ 1332 VCFRONT_a142_isCoilOpenX "Front body controller: a142 is coil open x";
CM_ SG_ 1332 VCFRONT_a142_isCoilOpenY "Front body controller: a142 is coil open y";
CM_ SG_ 1332 VCFRONT_a142_isCoilShortXPGnd "Front body controller: a142 is coil short XP gnd";
CM_ SG_ 1332 VCFRONT_a142_isCoilShortXPVbb "Front body controller: a142 is coil short XP vbb";
CM_ SG_ 1332 VCFRONT_a142_isCoilShortXNGnd "Front body controller: a142 is coil short XN gnd";
CM_ SG_ 1332 VCFRONT_a142_isCoilShortXNVbb "Front body controller: a142 is coil short XN vbb";
CM_ SG_ 1332 VCFRONT_a142_isCoilShortYPGnd "Front body controller: a142 is coil short YP gnd";
CM_ SG_ 1332 VCFRONT_a142_isCoilShortYPVbb "Front body controller: a142 is coil short YP vbb";
CM_ SG_ 1332 VCFRONT_a142_isCoilShortYNGnd "Front body controller: a142 is coil short YN gnd";
CM_ SG_ 1332 VCFRONT_a142_isCoilShortYNVbb "Front body controller: a142 is coil short YN vbb";
CM_ SG_ 1332 VCFRONT_a142_driverHasCommError "Front body controller: a142 driver has comm error";
CM_ SG_ 1332 VCFRONT_a143_vsUnderVoltage "Front body controller: a143 vs under voltage";
CM_ SG_ 1332 VCFRONT_a143_vsOverVoltage "Front body controller: a143 vs over voltage";
CM_ SG_ 1332 VCFRONT_a143_chpUnderVoltage "Front body controller: a143 chp under voltage";
CM_ SG_ 1332 VCFRONT_a143_vglUnderVoltage "Front body controller: a143 vgl under voltage";
CM_ SG_ 1332 VCFRONT_a143_thOverTemperature "Front body controller: a143 th over temperature";
CM_ SG_ 1332 VCFRONT_a144_vsUnderVoltage "Front body controller: a144 vs under voltage";
CM_ SG_ 1332 VCFRONT_a144_vsOverVoltage "Front body controller: a144 vs over voltage";
CM_ SG_ 1332 VCFRONT_a144_chpUnderVoltage "Front body controller: a144 chp under voltage";
CM_ SG_ 1332 VCFRONT_a144_vglUnderVoltage "Front body controller: a144 vgl under voltage";
CM_ SG_ 1332 VCFRONT_a144_thOverTemperature "Front body controller: a144 th over temperature";
CM_ SG_ 1332 VCFRONT_a145_vsUnderVoltage "Front body controller: a145 vs under voltage";
CM_ SG_ 1332 VCFRONT_a145_vsOverVoltage "Front body controller: a145 vs over voltage";
CM_ SG_ 1332 VCFRONT_a145_chpUnderVoltage "Front body controller: a145 chp under voltage";
CM_ SG_ 1332 VCFRONT_a145_vglUnderVoltage "Front body controller: a145 vgl under voltage";
CM_ SG_ 1332 VCFRONT_a145_thOverTemperature "Front body controller: a145 th over temperature";
CM_ SG_ 1332 VCFRONT_a146_RPMActual "Front body controller: a146 RPM actual";
CM_ SG_ 1332 VCFRONT_a146_RPMTarget "Front body controller: a146 RPM target";
CM_ SG_ 1332 VCFRONT_a147_RPMActual "Front body controller: a147 RPM actual";
CM_ SG_ 1332 VCFRONT_a147_RPMTarget "Front body controller: a147 RPM target";
CM_ SG_ 1332 VCFRONT_a148_RPMActual "Front body controller: a148 RPM actual";
CM_ SG_ 1332 VCFRONT_a148_RPMTarget "Front body controller: a148 RPM target";
CM_ SG_ 1332 VCFRONT_a150_RPMActual "Front body controller: a150 RPM actual";
CM_ SG_ 1332 VCFRONT_a150_RPMTarget "Front body controller: a150 RPM target";
CM_ SG_ 1332 VCFRONT_a151_RPMActual "Front body controller: a151 RPM actual";
CM_ SG_ 1332 VCFRONT_a151_RPMTarget "Front body controller: a151 RPM target";
CM_ SG_ 1332 VCFRONT_a152_RPMActual "Front body controller: a152 RPM actual";
CM_ SG_ 1332 VCFRONT_a152_RPMTarget "Front body controller: a152 RPM target";
CM_ SG_ 1332 VCFRONT_a156_motorCounts "Front body controller: a156 motor counts";
CM_ SG_ 1332 VCFRONT_a157_motorCounts "Front body controller: a157 motor counts";
CM_ SG_ 1332 VCFRONT_a159_stall "Front body controller: a159 stall";
CM_ SG_ 1332 VCFRONT_a159_angleActual "Front body controller: a159 angle actual";
CM_ SG_ 1332 VCFRONT_a159_angleTarget "Front body controller: a159 angle target";
CM_ SG_ 1332 VCFRONT_a160_highDischTemp "Front body controller: a160 high disch temp";
CM_ SG_ 1332 VCFRONT_a160_lowDischPressure "Front body controller: a160 low disch pressure";
CM_ SG_ 1332 VCFRONT_a160_highDischPressure "Front body controller: a160 high disch pressure";
CM_ SG_ 1332 VCFRONT_a160_lowSuctionPressure "Front body controller: a160 low suction pressure";
CM_ SG_ 1332 VCFRONT_a160_faultSnsDischPress "Front body controller: a160 fault sns disch press";
CM_ SG_ 1332 VCFRONT_a160_faultSnsDischTemp "Front body controller: a160 fault sns disch temp";
CM_ SG_ 1332 VCFRONT_a160_faultSnsSuctPress "Front body controller: a160 fault sns suct press";
CM_ SG_ 1332 VCFRONT_a160_faultSnsSuctTemp "Front body controller: a160 fault sns suct temp";
CM_ SG_ 1332 VCFRONT_a160_faultSnsAmbientTemp "Front body controller: a160 fault sns ambient temp";
CM_ SG_ 1332 VCFRONT_a160_faultValveEXV "Front body controller: a160 fault valve EXV";
CM_ SG_ 1332 VCFRONT_a160_faultValveEvapSol "Front body controller: a160 fault valve evap sol";
CM_ SG_ 1332 VCFRONT_a160_highDischargePressu "Front body controller: a160 high discharge pressure cutouts";
CM_ SG_ 1332 VCFRONT_a160_highDischargeTempCu "Front body controller: a160 high discharge temp cutouts";
CM_ SG_ 1332 VCFRONT_a160_compressorRpm "Front body controller: a160 compressor rpm";
CM_ SG_ 1332 VCFRONT_a161_failedStart "Front body controller: a161 failed start";
CM_ SG_ 1332 VCFRONT_a161_HVOverVoltage "Front body controller: a161 HV over voltage";
CM_ SG_ 1332 VCFRONT_a161_HVUnderVoltage "Front body controller: a161 HV under voltage";
CM_ SG_ 1332 VCFRONT_a161_overCurrent "Front body controller: a161 over current";
CM_ SG_ 1332 VCFRONT_a161_overTemperature "Front body controller: a161 over temperature";
CM_ SG_ 1332 VCFRONT_a161_shortCircuit "Front body controller: a161 short circuit";
CM_ SG_ 1332 VCFRONT_a161_underTemperature "Front body controller: a161 under temperature";
CM_ SG_ 1332 VCFRONT_a161_LVUnderVoltage "Front body controller: a161 LV under voltage";
CM_ SG_ 1332 VCFRONT_a161_LVOverVoltage "Front body controller: a161 LV over voltage";
CM_ SG_ 1332 VCFRONT_a161_tempSnsFaultIPM1 "Front body controller: a161 temp sns fault IPM1";
CM_ SG_ 1332 VCFRONT_a161_tempSnsFaultIPM2 "Front body controller: a161 temp sns fault IPM2";
CM_ SG_ 1332 VCFRONT_a161_tempSnsFaultCPU "Front body controller: a161 temp sns fault CPU";
CM_ SG_ 1332 VCFRONT_a161_currentSnsError "Front body controller: a161 current sns error";
CM_ SG_ 1332 VCFRONT_a161_selfTestFailCPU "Front body controller: a161 self test fail CPU";
CM_ SG_ 1332 VCFRONT_a161_internalPowerSupply "Front body controller: a161 internal power supply fault";
CM_ SG_ 1332 VCFRONT_a161_inverterOpenCircuit "Front body controller: a161 inverter open circuit";
CM_ SG_ 1332 VCFRONT_a161_warnOverTemperature "Front body controller: a161 warn over temperature";
CM_ SG_ 1332 VCFRONT_a161_failedStartRepeated "Front body controller: a161 failed start repeated";
CM_ SG_ 1332 VCFRONT_a161_overload "Front body controller: a161 overload";
CM_ SG_ 1332 VCFRONT_a162_dischargePressure "Front body controller: a162 discharge pressure";
CM_ SG_ 1332 VCFRONT_a162_chillerExvFlow "Front body controller: a162 chiller exv flow";
CM_ SG_ 1332 VCFRONT_a162_lccExvFlow "Front body controller: a162 lcc exv flow";
CM_ SG_ 1332 VCFRONT_a162_ccLeftExvFlow "Front body controller: a162 cc left exv flow";
CM_ SG_ 1332 VCFRONT_a162_ccRightExvFlow "Front body controller: a162 cc right exv flow";
CM_ SG_ 1332 VCFRONT_a162_evapExvFlow "Front body controller: a162 evap exv flow";
CM_ SG_ 1332 VCFRONT_a162_recircExvFlow "Front body controller: a162 recirc exv flow";
CM_ SG_ 1332 VCFRONT_a164_lockoutVoltage "Front body controller: a164 lockout voltage";
CM_ SG_ 1332 VCFRONT_a165_lockoutVoltage "Front body controller: a165 lockout voltage";
CM_ SG_ 1332 VCFRONT_a168_leftECU "Front body controller: a168 left ECU";
CM_ SG_ 1332 VCFRONT_a168_rightECU "Front body controller: a168 right ECU";
CM_ SG_ 1332 VCFRONT_a169_leftECU "Front body controller: a169 left ECU";
CM_ SG_ 1332 VCFRONT_a169_rightECU "Front body controller: a169 right ECU";
CM_ SG_ 1332 VCFRONT_a170_leftECU "Front body controller: a170 left ECU";
CM_ SG_ 1332 VCFRONT_a170_rightECU "Front body controller: a170 right ECU";
CM_ SG_ 1332 VCFRONT_a171_VCFRONT "Front body controller: a171 VCFRONT";
CM_ SG_ 1332 VCFRONT_a171_VCRIGHT "Front body controller: a171 VCRIGHT";
CM_ SG_ 1332 VCFRONT_a171_VCLEFT "Front body controller: a171 VCLEFT";
CM_ SG_ 1332 VCFRONT_a171_BMS "Front body controller: a171 BMS";
CM_ SG_ 1332 VCFRONT_a171_HVP "Front body controller: a171 HVP";
CM_ SG_ 1332 VCFRONT_a171_GTW "Front body controller: a171 GTW";
CM_ SG_ 1332 VCFRONT_a171_CP "Front body controller: a171 CP";
CM_ SG_ 1332 VCFRONT_a171_PCS "Front body controller: a171 PCS";
CM_ SG_ 1332 VCFRONT_a171_PCSCPU2 "Front body controller: a171 PCSCPU2";
CM_ SG_ 1332 VCFRONT_a171_DI "Front body controller: a171 DI";
CM_ SG_ 1332 VCFRONT_a171_DIS "Front body controller: a171 DIS";
CM_ SG_ 1332 VCFRONT_a171_PM "Front body controller: a171 PM";
CM_ SG_ 1332 VCFRONT_a171_PMS "Front body controller: a171 PMS";
CM_ SG_ 1332 VCFRONT_a171_EPBR "Front body controller: a171 EPBR";
CM_ SG_ 1332 VCFRONT_a171_EPBL "Front body controller: a171 EPBL";
CM_ SG_ 1332 VCFRONT_a171_IBST "Front body controller: a171 IBST";
CM_ SG_ 1332 VCFRONT_a171_IBSTCAL "Front body controller: a171 IBSTCAL";
CM_ SG_ 1332 VCFRONT_a171_ESP "Front body controller: a171 ESP";
CM_ SG_ 1332 VCFRONT_a171_ESPCAL "Front body controller: a171 ESPCAL";
CM_ SG_ 1332 VCFRONT_a171_OPC "Front body controller: a171 OPC";
CM_ SG_ 1332 VCFRONT_a171_OPCS "Front body controller: a171 OPCS";
CM_ SG_ 1332 VCFRONT_a171_SCCM "Front body controller: a171 SCCM";
CM_ SG_ 1332 VCFRONT_a171_LVBMS "Front body controller: a171 LVBMS";
CM_ SG_ 1332 VCFRONT_a171_IDB "Front body controller: a171 IDB";
CM_ SG_ 1332 VCFRONT_a171_IDB1 "Front body controller: a171 IDB1";
CM_ SG_ 1332 VCFRONT_a171_IDBCAL "Front body controller: a171 IDBCAL";
CM_ SG_ 1332 VCFRONT_a171_RCU "Front body controller: a171 RCU";
CM_ SG_ 1332 VCFRONT_a171_RCUCAL "Front body controller: a171 RCUCAL";
CM_ SG_ 1332 VCFRONT_a171_DPB "Front body controller: a171 DPB";
CM_ SG_ 1332 VCFRONT_a171_DPBCAL "Front body controller: a171 DPBCAL";
CM_ SG_ 1332 VCFRONT_a171_serviceMode "Signal reported by Front body controller";
CM_ SG_ 1332 VCFRONT_a172_ECUMismatchBits "Front body controller: a172 ECU mismatch bits";
CM_ SG_ 1332 VCFRONT_a172_serviceMode "Signal reported by Front body controller";
CM_ SG_ 1332 VCFRONT_a173_ECUMismatchBits "Front body controller: a173 ECU mismatch bits";
CM_ SG_ 1332 VCFRONT_a173_serviceMode "Signal reported by Front body controller";
CM_ SG_ 1332 VCFRONT_a175_snsShortCircuit "Front body controller: a175 sns short circuit";
CM_ SG_ 1332 VCFRONT_a175_snsDisconnect "Front body controller: a175 sns disconnect";
CM_ SG_ 1332 VCFRONT_a175_snsRateChangeUp "Front body controller: a175 sns rate change up";
CM_ SG_ 1332 VCFRONT_a175_snsRateChangeDown "Front body controller: a175 sns rate change down";
CM_ SG_ 1332 VCFRONT_a176_vehicleState "Front body controller: a176 vehicle state";
CM_ SG_ 1332 VCFRONT_a177_mcuAudioCurrent "Front body controller: a177 mcu audio current";
CM_ SG_ 1332 VCFRONT_a179_highLVAmpsIntoPCSLo "Front body controller: a179 high LV amps into PCS log";
CM_ SG_ 1332 VCFRONT_a180_vehiclePowerState "Front body controller: a180 vehicle power state";
CM_ SG_ 1332 VCFRONT_a180_hvState "Front body controller: a180 hv state";
CM_ SG_ 1332 VCFRONT_a180_bmsState "Front body controller: a180 bms state";
CM_ SG_ 1332 VCFRONT_a180_notEnoughPowerForSu "Front body controller: a180 not enough power for support";
CM_ SG_ 1332 VCFRONT_a180_pcsEFuseStable "Front body controller: a180 pcs e fuse stable";
CM_ SG_ 1332 VCFRONT_a180_vcrightEFuseStable "Front body controller: a180 vcright e fuse stable";
CM_ SG_ 1332 VCFRONT_a180_contactorEFuseStabl "Front body controller: a180 contactor e fuse stable";
CM_ SG_ 1332 VCFRONT_a180_hvcEFuseStable "Front body controller: a180 hvc e fuse stable";
CM_ SG_ 1332 VCFRONT_a180_replaceLVBattery "Front body controller: a180 replace LV battery";
CM_ SG_ 1332 VCFRONT_a180_BMS_MIA "Front body controller: a180 BMS MIA";
CM_ SG_ 1332 VCFRONT_a180_PCS_MIA "Front body controller: a180 PCS MIA";
CM_ SG_ 1332 VCFRONT_a180_HVBlockingMismatch "Front body controller: a180 HV blocking mismatch";
CM_ SG_ 1332 VCFRONT_a180_serviceMode "Signal reported by Front body controller";
CM_ SG_ 1332 VCFRONT_a180_transportMode "Front body controller: a180 transport mode";
CM_ SG_ 1332 VCFRONT_a180_frunkOpen "Front body controller: a180 frunk open";
CM_ SG_ 1332 VCFRONT_a180_dcdcLVSupportStatus "Front body controller: a180 dcdc LV support status";
CM_ SG_ 1332 VCFRONT_a181_vehicleState "Front body controller: a181 vehicle state";
CM_ SG_ 1332 VCFRONT_a182_deadLV "Front body controller: a182 dead LV";
CM_ SG_ 1332 VCFRONT_a182_voltageDrop "Front body controller: a182 voltage drop";
CM_ SG_ 1332 VCFRONT_a182_overcharge "Front body controller: a182 overcharge";
CM_ SG_ 1332 VCFRONT_a182_LVFloorReached "Front body controller: a182 LV floor reached";
CM_ SG_ 1332 VCFRONT_a182_shortedCell "Front body controller: a182 shorted cell";
CM_ SG_ 1332 VCFRONT_a182_postPORExcessiveAh "Front body controller: a182 post POR excessive ah";
CM_ SG_ 1332 VCFRONT_a182_resistanceEstimatio "Front body controller: a182 resistance estimation hard failure";
CM_ SG_ 1332 VCFRONT_a182_dcrMilliOhmsAboveTh "Front body controller: a182 dcr milli ohms above threshold";
CM_ SG_ 1332 VCFRONT_a182_prechargeLVLoadRedu "Front body controller: a182 precharge LV load reduction";
CM_ SG_ 1332 VCFRONT_a182_factoryMode "Front body controller: a182 factory mode";
CM_ SG_ 1332 VCFRONT_a182_serviceMode "Signal reported by Front body controller";
CM_ SG_ 1332 VCFRONT_a182_transportMode "Front body controller: a182 transport mode";
CM_ SG_ 1332 VCFRONT_a182_frunkOpen "Front body controller: a182 frunk open";
CM_ SG_ 1332 VCFRONT_a182_packOverDischarged "Front body controller: a182 pack over discharged";
CM_ SG_ 1332 VCFRONT_a182_cellImbalance "Front body controller: a182 cell imbalance";
CM_ SG_ 1332 VCFRONT_a182_instantPrechargeDCR "Front body controller: a182 instant precharge DCR too high";
CM_ SG_ 1332 VCFRONT_a182_ambientTemp "Front body controller: a182 ambient temp";
CM_ SG_ 1332 VCFRONT_a182_dischargedAmpHours "Front body controller: a182 discharged amp hours";
CM_ SG_ 1332 VCFRONT_a182_chargedAmpHours "Front body controller: a182 charged amp hours";
CM_ SG_ 1332 VCFRONT_a182_calibrationLostFaul "Front body controller: a182 calibration lost fault";
CM_ SG_ 1332 VCFRONT_a182_samplingHWError "Front body controller: a182 sampling HW error";
CM_ SG_ 1332 VCFRONT_a182_brickOverDischarged "Front body controller: a182 brick over discharged";
CM_ SG_ 1332 VCFRONT_a182_batteryType "Front body controller: a182 battery type";
CM_ SG_ 1332 VCFRONT_a186_noDriveChgCableConX "Front body controller: a186 no drive chg cable con x";
CM_ SG_ 1332 VCFRONT_a187_vehBusRetryCount "Front body controller: a187 veh bus retry count";
CM_ SG_ 1332 VCFRONT_a187_partyBusRetryCount "Front body controller: a187 party bus retry count";
CM_ SG_ 1332 VCFRONT_a187_hvsBusRetryCount "Front body controller: a187 hvs bus retry count";
CM_ SG_ 1332 VCFRONT_a187_ethBusRetryCount "Front body controller: a187 eth bus retry count";
CM_ SG_ 1332 VCFRONT_a187_chBusRetryCount "Front body controller: a187 ch bus retry count";
CM_ SG_ 1332 VCFRONT_a188_sleepBypassCurrent "Front body controller: a188 sleep bypass current";
CM_ SG_ 1332 VCFRONT_a188_IBSCurrent "Front body controller: a188 IBS current";
CM_ SG_ 1332 VCFRONT_a188_vehicleState "Front body controller: a188 vehicle state";
CM_ SG_ 1332 VCFRONT_a188_timeNotSleeping "Front body controller: a188 time not sleeping";
CM_ SG_ 1332 VCFRONT_a188_chargeRequest "Front body controller: a188 charge request";
CM_ SG_ 1332 VCFRONT_a188_12VSupport "Front body controller: a188 12 v support";
CM_ SG_ 1332 VCFRONT_a188_ThermalSupport "Front body controller: a188 thermal support";
CM_ SG_ 1332 VCFRONT_a188_accessoryRequest "Front body controller: a188 accessory request";
CM_ SG_ 1332 VCFRONT_a188_CANAfterQuiet "Front body controller: a188 CAN after quiet";
CM_ SG_ 1332 VCFRONT_a188_SleepRequestTimeout "Front body controller: a188 sleep request timeout";
CM_ SG_ 1332 VCFRONT_a188_wakeUpMsgID "Front body controller: a188 wake up msg ID";
CM_ SG_ 1332 VCFRONT_a191_vehiclePowerState "Front body controller: a191 vehicle power state";
CM_ SG_ 1332 VCFRONT_a191_hvState "Front body controller: a191 hv state";
CM_ SG_ 1332 VCFRONT_a191_reverseBatteryEFuse "Front body controller: a191 reverse battery e fuse fault";
CM_ SG_ 1332 VCFRONT_a191_vehicleLoadShedActi "Front body controller: a191 vehicle load shed active";
CM_ SG_ 1332 VCFRONT_a191_vehicleLoadShedHvFa "Front body controller: a191 vehicle load shed hv fault active";
CM_ SG_ 1332 VCFRONT_a191_vehicleLoadShedPost "Front body controller: a191 vehicle load shed post crash active";
CM_ SG_ 1332 VCFRONT_a191_IBSVoltage "Front body controller: a191 IBS voltage";
CM_ SG_ 1332 VCFRONT_a191_a180_DCDCNotSupport "Front body controller: a191 a180 DCDC not supporting LV bus";
CM_ SG_ 1332 VCFRONT_a191_MOSState "Front body controller: a191 MOS state";
CM_ SG_ 1332 VCFRONT_a191_LVBMSVoltage "Front body controller: a191 LVBMS voltage";
CM_ SG_ 1332 VCFRONT_a191_ECPAState "Front body controller: a191 ECPA state";
CM_ SG_ 1332 VCFRONT_a191_LVBMSCurrentTargetV "Front body controller: a191 LVBMS current target valid";
CM_ SG_ 1332 VCFRONT_a191_LVBMSVoltageTargetV "Front body controller: a191 LVBMS voltage target valid";
CM_ SG_ 1332 VCFRONT_a191_serviceMode "Signal reported by Front body controller";
CM_ SG_ 1332 VCFRONT_a191_frunkOpen "Front body controller: a191 frunk open";
CM_ SG_ 1332 VCFRONT_a191_vehicleLoadShedStag "Front body controller: a191 vehicle load shed stage";
CM_ SG_ 1332 VCFRONT_a191_exitDriveWarningTim "Front body controller: a191 exit drive warning timer expired";
CM_ SG_ 1332 VCFRONT_a191_LVBMSMIA "Front body controller: a191 LVBMSMIA";
CM_ SG_ 1332 VCFRONT_a191_PCS_MIA "Front body controller: a191 PCS MIA";
CM_ SG_ 1332 VCFRONT_a191_NotEnoughPowerForSu "Front body controller: a191 not enough power for support";
CM_ SG_ 1332 VCFRONT_a191_bmsState "Front body controller: a191 bms state";
CM_ SG_ 1332 VCFRONT_a192_vehiclePowerState "Front body controller: a192 vehicle power state";
CM_ SG_ 1332 VCFRONT_a192_hvState "Front body controller: a192 hv state";
CM_ SG_ 1332 VCFRONT_a192_notEnoughPowerForSu "Front body controller: a192 not enough power for support";
CM_ SG_ 1332 VCFRONT_a192_pcsEFuseStable "Front body controller: a192 pcs e fuse stable";
CM_ SG_ 1332 VCFRONT_a192_vcrightEFuseStable "Front body controller: a192 vcright e fuse stable";
CM_ SG_ 1332 VCFRONT_a192_contactorEFuseStabl "Front body controller: a192 contactor e fuse stable";
CM_ SG_ 1332 VCFRONT_a192_hvcEFuseStable "Front body controller: a192 hvc e fuse stable";
CM_ SG_ 1332 VCFRONT_a192_replaceLVBattery "Front body controller: a192 replace LV battery";
CM_ SG_ 1332 VCFRONT_a192_BMS_MIA "Front body controller: a192 BMS MIA";
CM_ SG_ 1332 VCFRONT_a192_PCS_MIA "Front body controller: a192 PCS MIA";
CM_ SG_ 1332 VCFRONT_a192_HVBlockingMismatch "Front body controller: a192 HV blocking mismatch";
CM_ SG_ 1332 VCFRONT_a192_disconnected12V "Front body controller: a192 disconnected12 v";
CM_ SG_ 1332 VCFRONT_a192_LVBatteryCannotSupp "Front body controller: a192 LV battery cannot support vehicle";
CM_ SG_ 1332 VCFRONT_a192_DI_gear "Front body controller: a192 DI gear";
CM_ SG_ 1332 VCFRONT_a192_GTW_factoryGated "Front body controller: a192 GTW factory gated";
CM_ SG_ 1332 VCFRONT_a192_GTW_updateStarted "Front body controller: a192 GTW update started";
CM_ SG_ 1332 VCFRONT_a192_serviceMode "Signal reported by Front body controller";
CM_ SG_ 1332 VCFRONT_a192_frunkOpen "Front body controller: a192 frunk open";
CM_ SG_ 1332 VCFRONT_a192_IBSCurrent "Front body controller: a192 IBS current";
CM_ SG_ 1332 VCFRONT_a192_PCSCurrent "Front body controller: a192 PCS current";
CM_ SG_ 1332 VCFRONT_a192_HVFaultLoadShedActi "Front body controller: a192 HV fault load shed active";
CM_ SG_ 1332 VCFRONT_a192_postCrashLoadShedAc "Front body controller: a192 post crash load shed active";
CM_ SG_ 1332 VCFRONT_a195_IBSVoltage "Front body controller: a195 IBS voltage";
CM_ SG_ 1332 VCFRONT_a195_serviceMode "Signal reported by Front body controller";
CM_ SG_ 1332 VCFRONT_a195_frunkOpen "Front body controller: a195 frunk open";
CM_ SG_ 1332 VCFRONT_a196_factoryMode "Front body controller: a196 factory mode";
CM_ SG_ 1332 VCFRONT_a196_serviceMode "Signal reported by Front body controller";
CM_ SG_ 1332 VCFRONT_a196_transportMode "Front body controller: a196 transport mode";
CM_ SG_ 1332 VCFRONT_a196_frunkOpen "Front body controller: a196 frunk open";
CM_ SG_ 1332 VCFRONT_a196_vehiclePowerState "Front body controller: a196 vehicle power state";
CM_ SG_ 1332 VCFRONT_a196_batterySMState "Front body controller: a196 battery SM state";
CM_ SG_ 1332 VCFRONT_a196_disconnectedBattery "Front body controller: a196 disconnected battery test current";
CM_ SG_ 1332 VCFRONT_a196_disconnectedBa_0002 "Front body controller: a196 disconnected battery test voltage";
CM_ SG_ 1332 VCFRONT_a196_disconnectedBa_0001 "Front body controller: a196 disconnected battery test prev voltage";
CM_ SG_ 1332 VCFRONT_a196_ECPAState "Front body controller: a196 ECPA state";
CM_ SG_ 1332 VCFRONT_a198_outputState "Front body controller: a198 output state";
CM_ SG_ 1332 VCFRONT_a198_NVRAMState "Front body controller: a198 NVRAM state";
CM_ SG_ 1332 VCFRONT_a198_lockoutState "Front body controller: a198 lockout state";
CM_ SG_ 1332 VCFRONT_a199_outputState "Front body controller: a199 output state";
CM_ SG_ 1332 VCFRONT_a199_NVRAMState "Front body controller: a199 NVRAM state";
CM_ SG_ 1332 VCFRONT_a199_lockoutState "Front body controller: a199 lockout state";
CM_ SG_ 1332 VCFRONT_a200_vcleftSelfTest "Front body controller: a200 vcleft self test";
CM_ SG_ 1332 VCFRONT_a201_vcrightSelfTest "Front body controller: a201 vcright self test";
CM_ SG_ 1332 VCFRONT_a202_pcsSelfTest "Front body controller: a202 pcs self test";
CM_ SG_ 1332 VCFRONT_a207_vbatFusedSelfTest "Front body controller: a207 vbat fused self test";
CM_ SG_ 1332 VCFRONT_a210_valveUnderTravel "Front body controller: a210 valve under travel";
CM_ SG_ 1332 VCFRONT_a210_valveOverTravel "Front body controller: a210 valve over travel";
CM_ SG_ 1332 VCFRONT_a210_valveNoTravel "Front body controller: a210 valve no travel";
CM_ SG_ 1332 VCFRONT_a212_IBSTemp "Front body controller: a212 IBS temp";
CM_ SG_ 1332 VCFRONT_a213_IBSVolts "Front body controller: a213 IBS volts";
CM_ SG_ 1332 VCFRONT_a213_IBSAh "Front body controller: a213 IBS ah";
CM_ SG_ 1332 VCFRONT_a213_LVBatteryTemp "Front body controller: a213 LV battery temp";
CM_ SG_ 1332 VCFRONT_a214_motorFaulted "Front body controller: a214 motor faulted";
CM_ SG_ 1332 VCFRONT_a214_motorLocked "Front body controller: a214 motor locked";
CM_ SG_ 1332 VCFRONT_a214_ecuReset "Front body controller: a214 ecu reset";
CM_ SG_ 1332 VCFRONT_a214_fetTempIrrational "Front body controller: a214 fet temp irrational";
CM_ SG_ 1332 VCFRONT_a214_motorControlError "Front body controller: a214 motor control error";
CM_ SG_ 1332 VCFRONT_a214_underVoltage "Front body controller: a214 under voltage";
CM_ SG_ 1332 VCFRONT_a214_overVoltage "Front body controller: a214 over voltage";
CM_ SG_ 1332 VCFRONT_a214_hardwareOvercurrent "Front body controller: a214 hardware overcurrent";
CM_ SG_ 1332 VCFRONT_a214_motorOpenPhase "Front body controller: a214 motor open phase";
CM_ SG_ 1332 VCFRONT_a214_motorSoftOpenPhase "Front body controller: a214 motor soft open phase";
CM_ SG_ 1332 VCFRONT_a214_motorOvertemp "Front body controller: a214 motor overtemp";
CM_ SG_ 1332 VCFRONT_a214_dcOvercurrent "Front body controller: a214 dc overcurrent";
CM_ SG_ 1332 VCFRONT_a214_motorStalled "Front body controller: a214 motor stalled";
CM_ SG_ 1332 VCFRONT_a214_selfTestFailed "Front body controller: a214 self test failed";
CM_ SG_ 1332 VCFRONT_a214_selfTestResult "Front body controller: a214 self test result";
CM_ SG_ 1332 VCFRONT_a214_linChecksumError "Front body controller: a214 lin checksum error";
CM_ SG_ 1332 VCFRONT_a214_linFramingError "Front body controller: a214 lin framing error";
CM_ SG_ 1332 VCFRONT_a214_phaseShorted "Front body controller: a214 phase shorted";
CM_ SG_ 1332 VCFRONT_a214_busVoltageIrrationa "Front body controller: a214 bus voltage irrational";
CM_ SG_ 1332 VCFRONT_a214_dcCurrentIrrational "Front body controller: a214 dc current irrational";
CM_ SG_ 1332 VCFRONT_a214_motorSpeedIrrationa "Front body controller: a214 motor speed irrational";
CM_ SG_ 1332 VCFRONT_a214_supplyVoltageIrrati "Front body controller: a214 supply voltage irrational";
CM_ SG_ 1332 VCFRONT_a214_motorPhaseCurrentIr "Front body controller: a214 motor phase current irrational";
CM_ SG_ 1332 VCFRONT_a214_chipOvertemp "Front body controller: a214 chip overtemp";
CM_ SG_ 1332 VCFRONT_a214_motorSpeedTooHigh "Front body controller: a214 motor speed too high";
CM_ SG_ 1332 VCFRONT_a214_phaseOvercurrent "Front body controller: a214 phase overcurrent";
CM_ SG_ 1332 VCFRONT_a214_vddaOvercurrent "Front body controller: a214 vdda overcurrent";
CM_ SG_ 1332 VCFRONT_a214_busVoltageUnhealthy "Front body controller: a214 bus voltage unhealthy";
CM_ SG_ 1332 VCFRONT_a214_hsVdsOvervoltage "Front body controller: a214 hs vds overvoltage";
CM_ SG_ 1332 VCFRONT_a214_hsVdsOvervoltageMas "Front body controller: a214 hs vds overvoltage mask";
CM_ SG_ 1332 VCFRONT_a214_lsVdsOvervoltage "Front body controller: a214 ls vds overvoltage";
CM_ SG_ 1332 VCFRONT_a214_lsVdsOvervoltageMas "Front body controller: a214 ls vds overvoltage mask";
CM_ SG_ 1332 VCFRONT_a214_payloadBitsNotSet "Front body controller: a214 payload bits not set";
CM_ SG_ 1332 VCFRONT_a216_inDrive "Front body controller: a216 in drive";
CM_ SG_ 1332 VCFRONT_a216_hvState "Front body controller: a216 hv state";
CM_ SG_ 1332 VCFRONT_a216_vcleftFastBlowImmin "Front body controller: a216 vcleft fast blow imminent";
CM_ SG_ 1332 VCFRONT_a216_vcleftFastBlowDebou "Front body controller: a216 vcleft fast blow debounce imminent";
CM_ SG_ 1332 VCFRONT_a216_vcleftStaticImminen "Front body controller: a216 vcleft static imminent";
CM_ SG_ 1332 VCFRONT_a216_vcleftDynamicImmine "Front body controller: a216 vcleft dynamic imminent";
CM_ SG_ 1332 VCFRONT_a216_vcrightFastBlowImmi "Front body controller: a216 vcright fast blow imminent";
CM_ SG_ 1332 VCFRONT_a216_vcrightFastBlowDebo "Front body controller: a216 vcright fast blow debounce imminent";
CM_ SG_ 1332 VCFRONT_a216_vcrightStaticImmine "Front body controller: a216 vcright static imminent";
CM_ SG_ 1332 VCFRONT_a216_vcrightDynamicImmin "Front body controller: a216 vcright dynamic imminent";
CM_ SG_ 1332 VCFRONT_a217_motorFaulted "Front body controller: a217 motor faulted";
CM_ SG_ 1332 VCFRONT_a217_motorLocked "Front body controller: a217 motor locked";
CM_ SG_ 1332 VCFRONT_a217_ecuReset "Front body controller: a217 ecu reset";
CM_ SG_ 1332 VCFRONT_a217_fetTempIrrational "Front body controller: a217 fet temp irrational";
CM_ SG_ 1332 VCFRONT_a217_motorControlError "Front body controller: a217 motor control error";
CM_ SG_ 1332 VCFRONT_a217_underVoltage "Front body controller: a217 under voltage";
CM_ SG_ 1332 VCFRONT_a217_overVoltage "Front body controller: a217 over voltage";
CM_ SG_ 1332 VCFRONT_a217_hardwareOvercurrent "Front body controller: a217 hardware overcurrent";
CM_ SG_ 1332 VCFRONT_a217_motorOpenPhase "Front body controller: a217 motor open phase";
CM_ SG_ 1332 VCFRONT_a217_motorSoftOpenPhase "Front body controller: a217 motor soft open phase";
CM_ SG_ 1332 VCFRONT_a217_motorOvertemp "Front body controller: a217 motor overtemp";
CM_ SG_ 1332 VCFRONT_a217_dcOvercurrent "Front body controller: a217 dc overcurrent";
CM_ SG_ 1332 VCFRONT_a217_motorStalled "Front body controller: a217 motor stalled";
CM_ SG_ 1332 VCFRONT_a217_selfTestFailed "Front body controller: a217 self test failed";
CM_ SG_ 1332 VCFRONT_a217_selfTestResult "Front body controller: a217 self test result";
CM_ SG_ 1332 VCFRONT_a217_linChecksumError "Front body controller: a217 lin checksum error";
CM_ SG_ 1332 VCFRONT_a217_linFramingError "Front body controller: a217 lin framing error";
CM_ SG_ 1332 VCFRONT_a217_phaseShorted "Front body controller: a217 phase shorted";
CM_ SG_ 1332 VCFRONT_a217_busVoltageIrrationa "Front body controller: a217 bus voltage irrational";
CM_ SG_ 1332 VCFRONT_a217_dcCurrentIrrational "Front body controller: a217 dc current irrational";
CM_ SG_ 1332 VCFRONT_a217_motorSpeedIrrationa "Front body controller: a217 motor speed irrational";
CM_ SG_ 1332 VCFRONT_a217_supplyVoltageIrrati "Front body controller: a217 supply voltage irrational";
CM_ SG_ 1332 VCFRONT_a217_motorPhaseCurrentIr "Front body controller: a217 motor phase current irrational";
CM_ SG_ 1332 VCFRONT_a217_chipOvertemp "Front body controller: a217 chip overtemp";
CM_ SG_ 1332 VCFRONT_a217_motorSpeedTooHigh "Front body controller: a217 motor speed too high";
CM_ SG_ 1332 VCFRONT_a217_phaseOvercurrent "Front body controller: a217 phase overcurrent";
CM_ SG_ 1332 VCFRONT_a217_vddaOvercurrent "Front body controller: a217 vdda overcurrent";
CM_ SG_ 1332 VCFRONT_a217_busVoltageUnhealthy "Front body controller: a217 bus voltage unhealthy";
CM_ SG_ 1332 VCFRONT_a217_hsVdsOvervoltage "Front body controller: a217 hs vds overvoltage";
CM_ SG_ 1332 VCFRONT_a217_hsVdsOvervoltageMas "Front body controller: a217 hs vds overvoltage mask";
CM_ SG_ 1332 VCFRONT_a217_lsVdsOvervoltage "Front body controller: a217 ls vds overvoltage";
CM_ SG_ 1332 VCFRONT_a217_lsVdsOvervoltageMas "Front body controller: a217 ls vds overvoltage mask";
CM_ SG_ 1332 VCFRONT_a217_payloadBitsNotSet "Front body controller: a217 payload bits not set";
CM_ SG_ 1332 VCFRONT_a219_IBSVolts "Front body controller: a219 IBS volts";
CM_ SG_ 1332 VCFRONT_a219_IBSAh "Front body controller: a219 IBS ah";
CM_ SG_ 1332 VCFRONT_a219_IBSCurrent "Front body controller: a219 IBS current";
CM_ SG_ 1332 VCFRONT_a220_IBSCurrent "Front body controller: a220 IBS current";
CM_ SG_ 1332 VCFRONT_a220_PCSCurrent "Front body controller: a220 PCS current";
CM_ SG_ 1332 VCFRONT_a220_serviceMode "Signal reported by Front body controller";
CM_ SG_ 1332 VCFRONT_a220_frunkOpen "Front body controller: a220 frunk open";
CM_ SG_ 1332 VCFRONT_a221_outputFaulted "Front body controller: a221 output faulted";
CM_ SG_ 1332 VCFRONT_a221_currentSenseFaulted "Front body controller: a221 current sense faulted";
CM_ SG_ 1332 VCFRONT_a221_tempSenseFaulted "Front body controller: a221 temp sense faulted";
CM_ SG_ 1332 VCFRONT_a221_underCurrent "Front body controller: a221 under current";
CM_ SG_ 1332 VCFRONT_a221_overCurrent "Front body controller: a221 over current";
CM_ SG_ 1332 VCFRONT_a221_overTemperature "Front body controller: a221 over temperature";
CM_ SG_ 1332 VCFRONT_a222_outputFaulted "Front body controller: a222 output faulted";
CM_ SG_ 1332 VCFRONT_a222_currentSenseFaulted "Front body controller: a222 current sense faulted";
CM_ SG_ 1332 VCFRONT_a222_tempSenseFaulted "Front body controller: a222 temp sense faulted";
CM_ SG_ 1332 VCFRONT_a222_underCurrent "Front body controller: a222 under current";
CM_ SG_ 1332 VCFRONT_a222_overCurrent "Front body controller: a222 over current";
CM_ SG_ 1332 VCFRONT_a222_overTemperature "Front body controller: a222 over temperature";
CM_ SG_ 1332 VCFRONT_a223_12VTemperature "Front body controller: a223 12 v temperature";
CM_ SG_ 1332 VCFRONT_a227_motorFaulted "Front body controller: a227 motor faulted";
CM_ SG_ 1332 VCFRONT_a227_motorLocked "Front body controller: a227 motor locked";
CM_ SG_ 1332 VCFRONT_a227_ecuReset "Front body controller: a227 ecu reset";
CM_ SG_ 1332 VCFRONT_a227_fetTempIrrational "Front body controller: a227 fet temp irrational";
CM_ SG_ 1332 VCFRONT_a227_motorControlError "Front body controller: a227 motor control error";
CM_ SG_ 1332 VCFRONT_a227_underVoltage "Front body controller: a227 under voltage";
CM_ SG_ 1332 VCFRONT_a227_overVoltage "Front body controller: a227 over voltage";
CM_ SG_ 1332 VCFRONT_a227_hardwareOvercurrent "Front body controller: a227 hardware overcurrent";
CM_ SG_ 1332 VCFRONT_a227_motorOpenPhase "Front body controller: a227 motor open phase";
CM_ SG_ 1332 VCFRONT_a227_motorSoftOpenPhase "Front body controller: a227 motor soft open phase";
CM_ SG_ 1332 VCFRONT_a227_motorOvertemp "Front body controller: a227 motor overtemp";
CM_ SG_ 1332 VCFRONT_a227_dcOvercurrent "Front body controller: a227 dc overcurrent";
CM_ SG_ 1332 VCFRONT_a227_motorStalled "Front body controller: a227 motor stalled";
CM_ SG_ 1332 VCFRONT_a227_selfTestFailed "Front body controller: a227 self test failed";
CM_ SG_ 1332 VCFRONT_a227_selfTestResult "Front body controller: a227 self test result";
CM_ SG_ 1332 VCFRONT_a227_linChecksumError "Front body controller: a227 lin checksum error";
CM_ SG_ 1332 VCFRONT_a227_linFramingError "Front body controller: a227 lin framing error";
CM_ SG_ 1332 VCFRONT_a227_phaseShorted "Front body controller: a227 phase shorted";
CM_ SG_ 1332 VCFRONT_a227_busVoltageIrrationa "Front body controller: a227 bus voltage irrational";
CM_ SG_ 1332 VCFRONT_a227_dcCurrentIrrational "Front body controller: a227 dc current irrational";
CM_ SG_ 1332 VCFRONT_a227_motorSpeedIrrationa "Front body controller: a227 motor speed irrational";
CM_ SG_ 1332 VCFRONT_a227_supplyVoltageIrrati "Front body controller: a227 supply voltage irrational";
CM_ SG_ 1332 VCFRONT_a227_motorPhaseCurrentIr "Front body controller: a227 motor phase current irrational";
CM_ SG_ 1332 VCFRONT_a227_chipOvertemp "Front body controller: a227 chip overtemp";
CM_ SG_ 1332 VCFRONT_a227_motorSpeedTooHigh "Front body controller: a227 motor speed too high";
CM_ SG_ 1332 VCFRONT_a227_phaseOvercurrent "Front body controller: a227 phase overcurrent";
CM_ SG_ 1332 VCFRONT_a227_vddaOvercurrent "Front body controller: a227 vdda overcurrent";
CM_ SG_ 1332 VCFRONT_a227_busVoltageUnhealthy "Front body controller: a227 bus voltage unhealthy";
CM_ SG_ 1332 VCFRONT_a227_hsVdsOvervoltage "Front body controller: a227 hs vds overvoltage";
CM_ SG_ 1332 VCFRONT_a227_hsVdsOvervoltageMas "Front body controller: a227 hs vds overvoltage mask";
CM_ SG_ 1332 VCFRONT_a227_lsVdsOvervoltage "Front body controller: a227 ls vds overvoltage";
CM_ SG_ 1332 VCFRONT_a227_lsVdsOvervoltageMas "Front body controller: a227 ls vds overvoltage mask";
CM_ SG_ 1332 VCFRONT_a227_payloadBitsNotSet "Front body controller: a227 payload bits not set";
CM_ SG_ 1332 VCFRONT_a231_12VTemperature "Front body controller: a231 12 v temperature";
CM_ SG_ 1332 VCFRONT_a233_current "Front body controller: a233 current";
CM_ SG_ 1332 VCFRONT_a234_current "Front body controller: a234 current";
CM_ SG_ 1332 VCFRONT_a235_ptSensorTemp "Front body controller: a235 pt sensor temp";
CM_ SG_ 1332 VCFRONT_a236_batSensorTemp "Front body controller: a236 bat sensor temp";
CM_ SG_ 1332 VCFRONT_a242_LVBatteryTemp "Front body controller: a242 LV battery temp";
CM_ SG_ 1332 VCFRONT_a242_IBSCurrent "Front body controller: a242 IBS current";
CM_ SG_ 1332 VCFRONT_a242_IBSVoltage "Front body controller: a242 IBS voltage";
CM_ SG_ 1332 VCFRONT_a242_IBSAmpHours "Front body controller: a242 IBS amp hours";
CM_ SG_ 1332 VCFRONT_a242_vehiclePowerState "Front body controller: a242 vehicle power state";
CM_ SG_ 1332 VCFRONT_a243_IBSVolts "Front body controller: a243 IBS volts";
CM_ SG_ 1332 VCFRONT_a243_IBSCurrent "Front body controller: a243 IBS current";
CM_ SG_ 1332 VCFRONT_a243_LVBatteryTemp "Front body controller: a243 LV battery temp";
CM_ SG_ 1332 VCFRONT_a244_current "Front body controller: a244 current";
CM_ SG_ 1332 VCFRONT_a244_voltage "Front body controller: a244 voltage";
CM_ SG_ 1332 VCFRONT_a244_vbatProtVoltage "Front body controller: a244 vbat prot voltage";
CM_ SG_ 1332 VCFRONT_a245_current "Front body controller: a245 current";
CM_ SG_ 1332 VCFRONT_a245_voltage "Front body controller: a245 voltage";
CM_ SG_ 1332 VCFRONT_a245_eFuseRemainingRetri "Front body controller: a245 e fuse remaining retries";
CM_ SG_ 1332 VCFRONT_a246_current "Front body controller: a246 current";
CM_ SG_ 1332 VCFRONT_a246_voltage "Front body controller: a246 voltage";
CM_ SG_ 1332 VCFRONT_a246_eFuseRemainingRetri "Front body controller: a246 e fuse remaining retries";
CM_ SG_ 1332 VCFRONT_a247_solenoidISense "Front body controller: a247 solenoid i sense";
CM_ SG_ 1332 VCFRONT_a248_AS8510Voltage "Front body controller: a248 AS8510 voltage";
CM_ SG_ 1332 VCFRONT_a248_IBSVoltage "Front body controller: a248 IBS voltage";
CM_ SG_ 1332 VCFRONT_a248_vbatMonitor "Front body controller: a248 vbat monitor";
CM_ SG_ 1332 VCFRONT_a248_voltageCalScaling "Front body controller: a248 voltage cal scaling";
CM_ SG_ 1332 VCFRONT_a249_tempCoolantBatInlet "Front body controller: a249 temp coolant bat inlet";
CM_ SG_ 1332 VCFRONT_a249_tempCoolantPTInlet "Front body controller: a249 temp coolant PT inlet";
CM_ SG_ 1332 VCFRONT_a250_isGlobalHeadlamps "Front body controller: a250 is global headlamps";
CM_ SG_ 1332 VCFRONT_a250_isVirtualPitchSenso "Front body controller: a250 is virtual pitch sensor";
CM_ SG_ 1332 VCFRONT_a250_isAimedHCML "Front body controller: a250 is aimed HCML";
CM_ SG_ 1332 VCFRONT_a250_isAimedHCMR "Front body controller: a250 is aimed HCMR";
CM_ SG_ 1332 VCFRONT_a250_calibratedVerticalP "Front body controller: a250 calibrated vertical position HCML";
CM_ SG_ 1332 VCFRONT_a250_calibratedVert_0001 "Front body controller: a250 calibrated vertical position HCMR";
CM_ SG_ 1332 VCFRONT_a250_calibratedHorizonta "Front body controller: a250 calibrated horizontal position HCML";
BA_DEF_ BO_ "GenMsgCycleTime" INT 0 3600000;
BA_DEF_ BO_ "GenMsgSendType" ENUM "Cyclic","NotUsed","NotUsed","NotUsed","NotUsed","NotUsed","NotUsed","IfActive","NoMsgSendType","NotUsed";
BA_DEF_ BO_ "VFrameFormat" ENUM "StandardCAN","ExtendedCAN","reserved","J1939PG","reserved","reserved","reserved","reserved","reserved","reserved","reserved","reserved","reserved","reserved","StandardCAN_FD","ExtendedCAN_FD";
BA_DEF_ BO_ "CANFD_BRS" ENUM "0","1";
BA_DEF_ SG_ "SystemSignalLongSymbol" STRING;
BA_DEF_ SG_ "Confidence" ENUM "layout-only","plausible","validated";
BA_DEF_DEF_ "GenMsgCycleTime" 0;
BA_DEF_DEF_ "GenMsgSendType" "NoMsgSendType";
BA_DEF_DEF_ "VFrameFormat" "StandardCAN";
BA_DEF_DEF_ "CANFD_BRS" "1";
BA_DEF_DEF_ "SystemSignalLongSymbol" "";
BA_DEF_DEF_ "Confidence" "layout-only";
BA_ "Confidence" SG_ 609 VCFRONT_good12VforUpdate 1;
BA_ "Confidence" SG_ 609 VCFRONT_LVLoadRequest 1;
BA_ "Confidence" SG_ 609 VCFRONT_batterySupportRequest 1;
BA_ "Confidence" SG_ 609 VCFRONT_batterySMState 1;
BA_ "Confidence" SG_ 609 VCFRONT_eFuseRecoveryStateDBG 1;
BA_ "Confidence" SG_ 609 VCFRONT_batteryLINScheduleDBG 1;
BA_ "SystemSignalLongSymbol" SG_ 609 VCFRONT_resistanceEstimationTest "VCFRONT_resistanceEstimationTestCounter";
BA_ "Confidence" SG_ 609 VCFRONT_IBSCurrent 1;
BA_ "Confidence" SG_ 609 VCFRONT_IBSVoltage 1;
BA_ "Confidence" SG_ 609 VCFRONT_reverseBatteryFault 1;
BA_ "Confidence" SG_ 609 VCFRONT_LVBatterySupported 1;
BA_ "SystemSignalLongSymbol" SG_ 609 VCFRONT_LVBatteryCannotSupportVe "VCFRONT_LVBatteryCannotSupportVehicle";
BA_ "Confidence" SG_ 609 VCFRONT_12VBatteryTargetVoltage 1;
BA_ "Confidence" SG_ 609 VCFRONT_IBSTemperature 1;
BA_ "Confidence" SG_ 609 VCFRONT_currentSensorMismatchLea 1;
BA_ "SystemSignalLongSymbol" SG_ 609 VCFRONT_currentSensorMismatchLea "VCFRONT_currentSensorMismatchLeakyBktPctDBG";
BA_ "Confidence" SG_ 609 VCFRONT_LVBatteryEnergyRemaining 1;
BA_ "SystemSignalLongSymbol" SG_ 609 VCFRONT_LVBatteryEnergyRemaining "VCFRONT_LVBatteryEnergyRemainingPCT";
BA_ "Confidence" SG_ 609 VCFRONT_LVBatteryStatusForDrive 1;
BA_ "Confidence" SG_ 609 VCFRONT_LVBatteryType 1;
BA_ "Confidence" SG_ 609 VCFRONT_resistanceEstimationNeed 1;
BA_ "SystemSignalLongSymbol" SG_ 609 VCFRONT_resistanceEstimationNeed "VCFRONT_resistanceEstimationNeeded";
BA_ "Confidence" SG_ 609 VCFRONT_IBSVoltageFiltered 1;
BA_ "Confidence" SG_ 609 VCFRONT_LVBMS_LVBusVoltageSource 1;
BA_ "SystemSignalLongSymbol" SG_ 609 VCFRONT_LVBMS_LVBusVoltageSource "VCFRONT_LVBMS_LVBusVoltageSourceDBG";
BA_ "Confidence" SG_ 609 VCFRONT_LVBMS_LVPackCurrentSourc 1;
BA_ "SystemSignalLongSymbol" SG_ 609 VCFRONT_LVBMS_LVPackCurrentSourc "VCFRONT_LVBMS_LVPackCurrentSourceDBG";
BA_ "Confidence" SG_ 609 VCFRONT_LVBatterySupportRqrdTrig 1;
BA_ "SystemSignalLongSymbol" SG_ 609 VCFRONT_LVBatterySupportRqrdTrig "VCFRONT_LVBatterySupportRqrdTrigger";
BA_ "Confidence" SG_ 609 VCFRONT_goodForPCSPowerCycleLeak 1;
BA_ "SystemSignalLongSymbol" SG_ 609 VCFRONT_goodForPCSPowerCycleLeak "VCFRONT_goodForPCSPowerCycleLeakyBktDBG";
BA_ "Confidence" SG_ 609 VCFRONT_LVBusControlsFutile 1;
BA_ "SystemSignalLongSymbol" SG_ 609 VCFRONT_resistanceEstimatio_0001 "VCFRONT_resistanceEstimationTestValid";
BA_ "SystemSignalLongSymbol" SG_ 609 VCFRONT_resistanceEstimatio_0002 "VCFRONT_resistanceEstimationTestsExpended";
BA_ "Confidence" SG_ 609 VCFRONT_goodLVChargeForUpdate 1;
BA_ "SystemSignalLongSymbol" SG_ 609 VCFRONT_opportunisticDCRTestNeed "VCFRONT_opportunisticDCRTestNeeded";
BA_ "Confidence" SG_ 609 VCFRONT_voltageProfile 1;
BA_ "Confidence" SG_ 609 VCFRONT_IBSAmpHours 1;
BA_ "Confidence" SG_ 609 VCFRONT_IBSVoltageRawDBG 1;
BA_ "SystemSignalLongSymbol" SG_ 609 VCFRONT_LVBatteryLINCommsDetecte "VCFRONT_LVBatteryLINCommsDetectedDBG";
BA_ "Confidence" SG_ 609 VCFRONT_voltageSensorMismatchLea 1;
BA_ "SystemSignalLongSymbol" SG_ 609 VCFRONT_voltageSensorMismatchLea "VCFRONT_voltageSensorMismatchLeakyBktPctDBG";
BA_ "SystemSignalLongSymbol" SG_ 609 VCFRONT_LVBatteryFctryLimOverrid "VCFRONT_LVBatteryFctryLimOverrideOk";
BA_ "SystemSignalLongSymbol" SG_ 609 VCFRONT_LVBatterySPICommsDetecte "VCFRONT_LVBatterySPICommsDetectedDBG";
BA_ "Confidence" SG_ 609 VCFRONT_targetCurrent 1;
BA_ "Confidence" SG_ 609 VCFRONT_PCSMia 1;
BA_ "Confidence" SG_ 609 VCFRONT_chargeNeeded 1;
BA_ "Confidence" SG_ 609 VCFRONT_voltageControlLoopIntegr 1;
BA_ "SystemSignalLongSymbol" SG_ 609 VCFRONT_voltageControlLoopIntegr "VCFRONT_voltageControlLoopIntegrationVal";
BA_ "Confidence" SG_ 609 VCFRONT_currentControlLoopIntegr 1;
BA_ "SystemSignalLongSymbol" SG_ 609 VCFRONT_currentControlLoopIntegr "VCFRONT_currentControlLoopIntegrationVal";
BA_ "Confidence" SG_ 1847 VCFRONT_LVBMS_SubUsageId 1;
BA_ "Confidence" SG_ 1847 VCFRONT_LVBMS_AppCRC 1;
BA_ "Confidence" SG_ 1847 VCFRONT_LVBMS_FWBuildType 1;
BA_ "Confidence" SG_ 2017 VCFRONT_LVHealthStatus 1;
BA_ "Confidence" SG_ 2017 VCFRONT_LVStatusForDrive 1;
BA_ "Confidence" SG_ 2017 VCFRONT_LVPowerSecondsToSafeHarb 1;
BA_ "SystemSignalLongSymbol" SG_ 2017 VCFRONT_LVPowerSecondsToSafeHarb "VCFRONT_LVPowerSecondsToSafeHarbor";
BA_ "Confidence" SG_ 2016 VCFRONT_LVHEALTH_placeholder 1;
BA_ "Confidence" SG_ 2016 VCFRONT_LVHEALTH_activeDecelEner 1;
BA_ "SystemSignalLongSymbol" SG_ 2016 VCFRONT_LVHEALTH_activeDecelEner "VCFRONT_LVHEALTH_activeDecelEnergyWarning";
BA_ "Confidence" SG_ 2016 VCFRONT_LVHEALTH_criticalPullove 1;
BA_ "SystemSignalLongSymbol" SG_ 2016 VCFRONT_LVHEALTH_criticalPullove "VCFRONT_LVHEALTH_criticalPulloverEnergyWarning";
BA_ "Confidence" SG_ 2016 VCFRONT_LVHEALTH_revBattEFuseOff 1;
BA_ "Confidence" SG_ 2016 VCFRONT_LVHEALTH_LVBMBEFuseOpen 1;
BA_ "Confidence" SG_ 2016 VCFRONT_LVHEALTH_lvBatteryCommsM 1;
BA_ "SystemSignalLongSymbol" SG_ 2016 VCFRONT_LVHEALTH_lvBatteryCommsM "VCFRONT_LVHEALTH_lvBatteryCommsMia";
BA_ "Confidence" SG_ 2016 VCFRONT_LVHEALTH_pcsEFuseOff 1;
BA_ "Confidence" SG_ 2016 VCFRONT_LVHEALTH_pcsNotActive 1;
BA_ "Confidence" SG_ 2016 VCFRONT_LVHEALTH_pcsMIA 1;
BA_ "Confidence" SG_ 2016 VCFRONT_LVHEALTH_IBSMIA 1;
BA_ "Confidence" SG_ 2016 VCFRONT_LVHEALTH_LVBatteryElecDi 1;
BA_ "SystemSignalLongSymbol" SG_ 2016 VCFRONT_LVHEALTH_LVBatteryElecDi "VCFRONT_LVHEALTH_LVBatteryElecDisc";
BA_ "Confidence" SG_ 2016 VCFRONT_LVHEALTH_LVBatteryE_0001 1;
BA_ "SystemSignalLongSymbol" SG_ 2016 VCFRONT_LVHEALTH_LVBatteryE_0001 "VCFRONT_LVHEALTH_LVBatteryElecDiscUnknown";
BA_ "Confidence" SG_ 2016 VCFRONT_LVHEALTH_pcsOpenCircuit 1;
BA_ "Confidence" SG_ 2016 VCFRONT_LVHEALTH_activeDecelPowe 1;
BA_ "SystemSignalLongSymbol" SG_ 2016 VCFRONT_LVHEALTH_activeDecelPowe "VCFRONT_LVHEALTH_activeDecelPowerWarning";
BA_ "Confidence" SG_ 2016 VCFRONT_LVHEALTH_lvBatteryCapabi 1;
BA_ "SystemSignalLongSymbol" SG_ 2016 VCFRONT_LVHEALTH_lvBatteryCapabi "VCFRONT_LVHEALTH_lvBatteryCapabilityLowAccuracy";
BA_ "Confidence" SG_ 2016 VCFRONT_LVHEALTH_lvBatteryConfig 1;
BA_ "SystemSignalLongSymbol" SG_ 2016 VCFRONT_LVHEALTH_lvBatteryConfig "VCFRONT_LVHEALTH_lvBatteryConfiguration";
BA_ "Confidence" SG_ 2016 VCFRONT_LVHEALTH_lvBatteryImpeda 1;
BA_ "SystemSignalLongSymbol" SG_ 2016 VCFRONT_LVHEALTH_lvBatteryImpeda "VCFRONT_LVHEALTH_lvBatteryImpedance";
BA_ "Confidence" SG_ 545 VCFRONT_vehiclePowerState 1;
BA_ "Confidence" SG_ 545 VCFRONT_cpLVRequest 1;
BA_ "Confidence" SG_ 545 VCFRONT_epasLVState 1;
BA_ "Confidence" SG_ 545 VCFRONT_hvcLVRequest 1;
BA_ "Confidence" SG_ 545 VCFRONT_tasLVState 1;
BA_ "Confidence" SG_ 545 VCFRONT_pcsLVState 1;
BA_ "Confidence" SG_ 545 VCFRONT_CMPDLVState 1;
BA_ "Confidence" SG_ 545 VCFRONT_hcmlLVState 1;
BA_ "Confidence" SG_ 545 VCFRONT_hcmrLVState 1;
BA_ "Confidence" SG_ 545 VCFRONT_MCUAudioLVState 1;
BA_ "Confidence" SG_ 545 VCFRONT_espValveLVState 1;
BA_ "Confidence" SG_ 545 VCFRONT_MCUGraphicsLVState 1;
BA_ "Confidence" SG_ 545 VC_hvStateRequest 1;
BA_ "SystemSignalLongSymbol" SG_ 545 VC_persistAccPowerRequestOverrid "VC_persistAccPowerRequestOverridden";
BA_ "Confidence" SG_ 545 VC_persistAccPortPowerState 1;
BA_ "Confidence" SG_ 700 VCFRONT_radiatorFanState 1;
BA_ "Confidence" SG_ 700 VCFRONT_radiatorFanTorque 1;
BA_ "Confidence" SG_ 700 VCFRONT_radiatorFanIDc 1;
BA_ "Confidence" SG_ 700 VCFRONT_mlxLINCurrentSchedule 1;
BA_ "Confidence" SG_ 700 VCFRONT_pumpPowertrainState 1;
BA_ "Confidence" SG_ 700 VCFRONT_pumpPowertrainTorque 1;
BA_ "Confidence" SG_ 700 VCFRONT_pumpPowertrainIDc 1;
BA_ "Confidence" SG_ 700 VCFRONT_pumpBatteryState 1;
BA_ "Confidence" SG_ 700 VCFRONT_pumpBatteryTorque 1;
BA_ "Confidence" SG_ 700 VCFRONT_pumpBatteryIDc 1;
BA_ "SystemSignalLongSymbol" SG_ 1332 VCFRONT_a004_APPWatchdogFaultOrM "VCFRONT_a004_APPWatchdogFaultOrMIA";
BA_ "SystemSignalLongSymbol" SG_ 1332 VCFRONT_a004_DASHighLowBeamDecis "VCFRONT_a004_DASHighLowBeamDecisionSNA";
BA_ "SystemSignalLongSymbol" SG_ 1332 VCFRONT_a004_DASAdaptiveHighBeam "VCFRONT_a004_DASAdaptiveHighBeamFault";
BA_ "SystemSignalLongSymbol" SG_ 1332 VCFRONT_a004_DASMatrixColumnMsgM "VCFRONT_a004_DASMatrixColumnMsgMIA";
BA_ "SystemSignalLongSymbol" SG_ 1332 VCFRONT_a004_EPAS3PNotInSpecOrMI "VCFRONT_a004_EPAS3PNotInSpecOrMIA";
BA_ "SystemSignalLongSymbol" SG_ 1332 VCFRONT_a008_APPWatchdogFaultOrM "VCFRONT_a008_APPWatchdogFaultOrMIA";
BA_ "SystemSignalLongSymbol" SG_ 1332 VCFRONT_a008_DASHighLowBeamDecis "VCFRONT_a008_DASHighLowBeamDecisionSNA";
BA_ "SystemSignalLongSymbol" SG_ 1332 VCFRONT_a008_DASAdaptiveHighBeam "VCFRONT_a008_DASAdaptiveHighBeamFault";
BA_ "SystemSignalLongSymbol" SG_ 1332 VCFRONT_a008_DASMatrixColumnMsgM "VCFRONT_a008_DASMatrixColumnMsgMIA";
BA_ "SystemSignalLongSymbol" SG_ 1332 VCFRONT_a008_EPAS3PNotInSpecOrMI "VCFRONT_a008_EPAS3PNotInSpecOrMIA";
BA_ "SystemSignalLongSymbol" SG_ 1332 VCFRONT_a010_UnderVoltageDetecte "VCFRONT_a010_UnderVoltageDetected";
BA_ "SystemSignalLongSymbol" SG_ 1332 VCFRONT_a082_RIPC_epbPrivateStat "VCFRONT_a082_RIPC_epbPrivateState";
BA_ "SystemSignalLongSymbol" SG_ 1332 VCFRONT_a083_LIPC_epbPrivateStat "VCFRONT_a083_LIPC_epbPrivateState";
BA_ "SystemSignalLongSymbol" SG_ 1332 VCFRONT_a086_VEH_LVBMS_statusHig "VCFRONT_a086_VEH_LVBMS_statusHigh";
BA_ "SystemSignalLongSymbol" SG_ 1332 VCFRONT_a086_VEH_12VBatteryStatu "VCFRONT_a086_VEH_12VBatteryStatus";
BA_ "SystemSignalLongSymbol" SG_ 1332 VCFRONT_a087_PARTY_thermalContro "VCFRONT_a087_PARTY_thermalControl";
BA_ "SystemSignalLongSymbol" SG_ 1332 VCFRONT_a088_PARTY_thermalContro "VCFRONT_a088_PARTY_thermalControl";
BA_ "SystemSignalLongSymbol" SG_ 1332 VCFRONT_a098_PARTY_thermalContro "VCFRONT_a098_PARTY_thermalControl";
BA_ "SystemSignalLongSymbol" SG_ 1332 VCFRONT_a101_LIPC_externalWatchd "VCFRONT_a101_LIPC_externalWatchdogHeartBeat";
BA_ "SystemSignalLongSymbol" SG_ 1332 VCFRONT_a106_VEH_thermalInterfac "VCFRONT_a106_VEH_thermalInterface";
BA_ "SystemSignalLongSymbol" SG_ 1332 VCFRONT_a108_PARTY_thermalContro "VCFRONT_a108_PARTY_thermalControl";
BA_ "SystemSignalLongSymbol" SG_ 1332 VCFRONT_a110_VEH_canLogAvailabil "VCFRONT_a110_VEH_canLogAvailability";
BA_ "SystemSignalLongSymbol" SG_ 1332 VCFRONT_a110_CH_airbagCutoffStat "VCFRONT_a110_CH_airbagCutoffStatus";
BA_ "SystemSignalLongSymbol" SG_ 1332 VCFRONT_a111_RIPC_epbPrivateStat "VCFRONT_a111_RIPC_epbPrivateState";
BA_ "SystemSignalLongSymbol" SG_ 1332 VCFRONT_a112_LIPC_epbPrivateStat "VCFRONT_a112_LIPC_epbPrivateState";
BA_ "SystemSignalLongSymbol" SG_ 1332 VCFRONT_a115_UI_corianderVehicle "VCFRONT_a115_UI_corianderVehicleControl";
BA_ "SystemSignalLongSymbol" SG_ 1332 VCFRONT_a116_PARTY_restraintStat "VCFRONT_a116_PARTY_restraintStatus";
BA_ "SystemSignalLongSymbol" SG_ 1332 VCFRONT_a117_BDY_falconSwitchSta "VCFRONT_a117_BDY_falconSwitchStatus";
BA_ "SystemSignalLongSymbol" SG_ 1332 VCFRONT_a117_VEH_intrusionSensor "VCFRONT_a117_VEH_intrusionSensorStatus";
BA_ "SystemSignalLongSymbol" SG_ 1332 VCFRONT_a117_PARTY_restraintStat "VCFRONT_a117_PARTY_restraintStatus";
BA_ "SystemSignalLongSymbol" SG_ 1332 VCFRONT_a118_VEH_12VBatteryStatu "VCFRONT_a118_VEH_12VBatteryStatus";
BA_ "SystemSignalLongSymbol" SG_ 1332 VCFRONT_a118_PARTY_outputPowerSt "VCFRONT_a118_PARTY_outputPowerStatus";
BA_ "SystemSignalLongSymbol" SG_ 1332 VCFRONT_a118_VEH_interNodeResist "VCFRONT_a118_VEH_interNodeResistance";
BA_ "SystemSignalLongSymbol" SG_ 1332 VCFRONT_a118_BDY_outputPowerStat "VCFRONT_a118_BDY_outputPowerStatus";
BA_ "SystemSignalLongSymbol" SG_ 1332 VCFRONT_a118_PARTY_AP_vehicleSta "VCFRONT_a118_PARTY_AP_vehicleState1HzMuxed";
BA_ "SystemSignalLongSymbol" SG_ 1332 VCFRONT_a118_BDY_AP_vehicleState "VCFRONT_a118_BDY_AP_vehicleState1HzMuxed";
BA_ "SystemSignalLongSymbol" SG_ 1332 VCFRONT_a120_PARTY_vehicleEstima "VCFRONT_a120_PARTY_vehicleEstimates";
BA_ "SystemSignalLongSymbol" SG_ 1332 VCFRONT_a120_VEH_aggregatedAxleS "VCFRONT_a120_VEH_aggregatedAxleSpeed";
BA_ "SystemSignalLongSymbol" SG_ 1332 VCFRONT_a120_PARTY_aggregatedAxl "VCFRONT_a120_PARTY_aggregatedAxleSpeed";
BA_ "SystemSignalLongSymbol" SG_ 1332 VCFRONT_a120_PARTY_stalklessInte "VCFRONT_a120_PARTY_stalklessInterfaces";
BA_ "SystemSignalLongSymbol" SG_ 1332 VCFRONT_a120_VEH_estimatedBrakeT "VCFRONT_a120_VEH_estimatedBrakeTemp";
BA_ "SystemSignalLongSymbol" SG_ 1332 VCFRONT_a120_VEH_vehicleEstimate "VCFRONT_a120_VEH_vehicleEstimates";
BA_ "SystemSignalLongSymbol" SG_ 1332 VCFRONT_a127_vcleftEFuseRemainin "VCFRONT_a127_vcleftEFuseRemainingRetries";
BA_ "SystemSignalLongSymbol" SG_ 1332 VCFRONT_a128_vcrightEFuseRemaini "VCFRONT_a128_vcrightEFuseRemainingRetries";
BA_ "SystemSignalLongSymbol" SG_ 1332 VCFRONT_a129_pcsEFuseRemainingRe "VCFRONT_a129_pcsEFuseRemainingRetries";
BA_ "SystemSignalLongSymbol" SG_ 1332 VCFRONT_a134_vbatFusedEFuseRemai "VCFRONT_a134_vbatFusedEFuseRemainingRetries";
BA_ "SystemSignalLongSymbol" SG_ 1332 VCFRONT_a142_chargePumpUndervolt "VCFRONT_a142_chargePumpUndervoltage";
BA_ "SystemSignalLongSymbol" SG_ 1332 VCFRONT_a160_highDischargePressu "VCFRONT_a160_highDischargePressureCutouts";
BA_ "SystemSignalLongSymbol" SG_ 1332 VCFRONT_a160_highDischargeTempCu "VCFRONT_a160_highDischargeTempCutouts";
BA_ "SystemSignalLongSymbol" SG_ 1332 VCFRONT_a161_internalPowerSupply "VCFRONT_a161_internalPowerSupplyFault";
BA_ "SystemSignalLongSymbol" SG_ 1332 VCFRONT_a179_highLVAmpsIntoPCSLo "VCFRONT_a179_highLVAmpsIntoPCSLog";
BA_ "SystemSignalLongSymbol" SG_ 1332 VCFRONT_a180_notEnoughPowerForSu "VCFRONT_a180_notEnoughPowerForSupport";
BA_ "SystemSignalLongSymbol" SG_ 1332 VCFRONT_a180_contactorEFuseStabl "VCFRONT_a180_contactorEFuseStable";
BA_ "SystemSignalLongSymbol" SG_ 1332 VCFRONT_a182_resistanceEstimatio "VCFRONT_a182_resistanceEstimationHardFailure";
BA_ "SystemSignalLongSymbol" SG_ 1332 VCFRONT_a182_dcrMilliOhmsAboveTh "VCFRONT_a182_dcrMilliOhmsAboveThreshold";
BA_ "SystemSignalLongSymbol" SG_ 1332 VCFRONT_a182_prechargeLVLoadRedu "VCFRONT_a182_prechargeLVLoadReduction";
BA_ "SystemSignalLongSymbol" SG_ 1332 VCFRONT_a182_instantPrechargeDCR "VCFRONT_a182_instantPrechargeDCRTooHigh";
BA_ "SystemSignalLongSymbol" SG_ 1332 VCFRONT_a182_calibrationLostFaul "VCFRONT_a182_calibrationLostFault";
BA_ "SystemSignalLongSymbol" SG_ 1332 VCFRONT_a191_reverseBatteryEFuse "VCFRONT_a191_reverseBatteryEFuseFault";
BA_ "SystemSignalLongSymbol" SG_ 1332 VCFRONT_a191_vehicleLoadShedActi "VCFRONT_a191_vehicleLoadShedActive";
BA_ "SystemSignalLongSymbol" SG_ 1332 VCFRONT_a191_vehicleLoadShedHvFa "VCFRONT_a191_vehicleLoadShedHvFaultActive";
BA_ "SystemSignalLongSymbol" SG_ 1332 VCFRONT_a191_vehicleLoadShedPost "VCFRONT_a191_vehicleLoadShedPostCrashActive";
BA_ "SystemSignalLongSymbol" SG_ 1332 VCFRONT_a191_a180_DCDCNotSupport "VCFRONT_a191_a180_DCDCNotSupportingLVBus";
BA_ "SystemSignalLongSymbol" SG_ 1332 VCFRONT_a191_LVBMSCurrentTargetV "VCFRONT_a191_LVBMSCurrentTargetValid";
BA_ "SystemSignalLongSymbol" SG_ 1332 VCFRONT_a191_LVBMSVoltageTargetV "VCFRONT_a191_LVBMSVoltageTargetValid";
BA_ "SystemSignalLongSymbol" SG_ 1332 VCFRONT_a191_vehicleLoadShedStag "VCFRONT_a191_vehicleLoadShedStage";
BA_ "SystemSignalLongSymbol" SG_ 1332 VCFRONT_a191_exitDriveWarningTim "VCFRONT_a191_exitDriveWarningTimerExpired";
BA_ "SystemSignalLongSymbol" SG_ 1332 VCFRONT_a191_NotEnoughPowerForSu "VCFRONT_a191_NotEnoughPowerForSupport";
BA_ "SystemSignalLongSymbol" SG_ 1332 VCFRONT_a192_notEnoughPowerForSu "VCFRONT_a192_notEnoughPowerForSupport";
BA_ "SystemSignalLongSymbol" SG_ 1332 VCFRONT_a192_contactorEFuseStabl "VCFRONT_a192_contactorEFuseStable";
BA_ "SystemSignalLongSymbol" SG_ 1332 VCFRONT_a192_LVBatteryCannotSupp "VCFRONT_a192_LVBatteryCannotSupportVehicle";
BA_ "SystemSignalLongSymbol" SG_ 1332 VCFRONT_a192_HVFaultLoadShedActi "VCFRONT_a192_HVFaultLoadShedActive";
BA_ "SystemSignalLongSymbol" SG_ 1332 VCFRONT_a192_postCrashLoadShedAc "VCFRONT_a192_postCrashLoadShedActive";
BA_ "SystemSignalLongSymbol" SG_ 1332 VCFRONT_a196_disconnectedBattery "VCFRONT_a196_disconnectedBatteryTestCurrent";
BA_ "SystemSignalLongSymbol" SG_ 1332 VCFRONT_a196_disconnectedBa_0002 "VCFRONT_a196_disconnectedBatteryTestVoltage";
BA_ "SystemSignalLongSymbol" SG_ 1332 VCFRONT_a196_disconnectedBa_0001 "VCFRONT_a196_disconnectedBatteryTestPrevVoltage";
BA_ "SystemSignalLongSymbol" SG_ 1332 VCFRONT_a214_busVoltageIrrationa "VCFRONT_a214_busVoltageIrrational";
BA_ "SystemSignalLongSymbol" SG_ 1332 VCFRONT_a214_motorSpeedIrrationa "VCFRONT_a214_motorSpeedIrrational";
BA_ "SystemSignalLongSymbol" SG_ 1332 VCFRONT_a214_supplyVoltageIrrati "VCFRONT_a214_supplyVoltageIrrational";
BA_ "SystemSignalLongSymbol" SG_ 1332 VCFRONT_a214_motorPhaseCurrentIr "VCFRONT_a214_motorPhaseCurrentIrrational";
BA_ "SystemSignalLongSymbol" SG_ 1332 VCFRONT_a214_hsVdsOvervoltageMas "VCFRONT_a214_hsVdsOvervoltageMask";
BA_ "SystemSignalLongSymbol" SG_ 1332 VCFRONT_a214_lsVdsOvervoltageMas "VCFRONT_a214_lsVdsOvervoltageMask";
BA_ "SystemSignalLongSymbol" SG_ 1332 VCFRONT_a216_vcleftFastBlowImmin "VCFRONT_a216_vcleftFastBlowImminent";
BA_ "SystemSignalLongSymbol" SG_ 1332 VCFRONT_a216_vcleftFastBlowDebou "VCFRONT_a216_vcleftFastBlowDebounceImminent";
BA_ "SystemSignalLongSymbol" SG_ 1332 VCFRONT_a216_vcleftStaticImminen "VCFRONT_a216_vcleftStaticImminent";
BA_ "SystemSignalLongSymbol" SG_ 1332 VCFRONT_a216_vcleftDynamicImmine "VCFRONT_a216_vcleftDynamicImminent";
BA_ "SystemSignalLongSymbol" SG_ 1332 VCFRONT_a216_vcrightFastBlowImmi "VCFRONT_a216_vcrightFastBlowImminent";
BA_ "SystemSignalLongSymbol" SG_ 1332 VCFRONT_a216_vcrightFastBlowDebo "VCFRONT_a216_vcrightFastBlowDebounceImminent";
BA_ "SystemSignalLongSymbol" SG_ 1332 VCFRONT_a216_vcrightStaticImmine "VCFRONT_a216_vcrightStaticImminent";
BA_ "SystemSignalLongSymbol" SG_ 1332 VCFRONT_a216_vcrightDynamicImmin "VCFRONT_a216_vcrightDynamicImminent";
BA_ "SystemSignalLongSymbol" SG_ 1332 VCFRONT_a217_busVoltageIrrationa "VCFRONT_a217_busVoltageIrrational";
BA_ "SystemSignalLongSymbol" SG_ 1332 VCFRONT_a217_motorSpeedIrrationa "VCFRONT_a217_motorSpeedIrrational";
BA_ "SystemSignalLongSymbol" SG_ 1332 VCFRONT_a217_supplyVoltageIrrati "VCFRONT_a217_supplyVoltageIrrational";
BA_ "SystemSignalLongSymbol" SG_ 1332 VCFRONT_a217_motorPhaseCurrentIr "VCFRONT_a217_motorPhaseCurrentIrrational";
BA_ "SystemSignalLongSymbol" SG_ 1332 VCFRONT_a217_hsVdsOvervoltageMas "VCFRONT_a217_hsVdsOvervoltageMask";
BA_ "SystemSignalLongSymbol" SG_ 1332 VCFRONT_a217_lsVdsOvervoltageMas "VCFRONT_a217_lsVdsOvervoltageMask";
BA_ "SystemSignalLongSymbol" SG_ 1332 VCFRONT_a227_busVoltageIrrationa "VCFRONT_a227_busVoltageIrrational";
BA_ "SystemSignalLongSymbol" SG_ 1332 VCFRONT_a227_motorSpeedIrrationa "VCFRONT_a227_motorSpeedIrrational";
BA_ "SystemSignalLongSymbol" SG_ 1332 VCFRONT_a227_supplyVoltageIrrati "VCFRONT_a227_supplyVoltageIrrational";
BA_ "SystemSignalLongSymbol" SG_ 1332 VCFRONT_a227_motorPhaseCurrentIr "VCFRONT_a227_motorPhaseCurrentIrrational";
BA_ "SystemSignalLongSymbol" SG_ 1332 VCFRONT_a227_hsVdsOvervoltageMas "VCFRONT_a227_hsVdsOvervoltageMask";
BA_ "SystemSignalLongSymbol" SG_ 1332 VCFRONT_a227_lsVdsOvervoltageMas "VCFRONT_a227_lsVdsOvervoltageMask";
BA_ "SystemSignalLongSymbol" SG_ 1332 VCFRONT_a245_eFuseRemainingRetri "VCFRONT_a245_eFuseRemainingRetries";
BA_ "SystemSignalLongSymbol" SG_ 1332 VCFRONT_a246_eFuseRemainingRetri "VCFRONT_a246_eFuseRemainingRetries";
BA_ "SystemSignalLongSymbol" SG_ 1332 VCFRONT_a250_isVirtualPitchSenso "VCFRONT_a250_isVirtualPitchSensor";
BA_ "SystemSignalLongSymbol" SG_ 1332 VCFRONT_a250_calibratedVerticalP "VCFRONT_a250_calibratedVerticalPositionHCML";
BA_ "SystemSignalLongSymbol" SG_ 1332 VCFRONT_a250_calibratedVert_0001 "VCFRONT_a250_calibratedVerticalPositionHCMR";
BA_ "SystemSignalLongSymbol" SG_ 1332 VCFRONT_a250_calibratedHorizonta "VCFRONT_a250_calibratedHorizontalPositionHCML";
VAL_ 609 VCFRONT_batterySMState 10 "BATTERY_SM_STATE_EXTERNAL_LV_BUS_CONTROL" 9 "BATTERY_SM_STATE_RECOVERY" 8 "BATTERY_SM_STATE_FAULT" 7 "BATTERY_SM_STATE_SHORTED_CELL_TEST" 6 "BATTERY_SM_STATE_DISCONNECTED_BATTERY_TEST" 5 "BATTERY_SM_STATE_OTA_STANDBY" 4 "BATTERY_SM_STATE_RESISTANCE_ESTIMATION" 3 "BATTERY_SM_STATE_STANDBY" 2 "BATTERY_SM_STATE_DISCHARGE" 1 "BATTERY_SM_STATE_CHARGE" 0 "BATTERY_SM_STATE_INIT" ;
VAL_ 609 VCFRONT_eFuseRecoveryStateDBG 4 "VC_LVBMB_EFUSE_RECOVERY_STATE_BLOCKED" 3 "VC_LVBMB_EFUSE_RECOVERY_STATE_FINISH" 2 "VC_LVBMB_EFUSE_RECOVERY_STATE_CONNECT" 1 "VC_LVBMB_EFUSE_RECOVERY_STATE_SETUP" 0 "VC_LVBMB_EFUSE_RECOVERY_STATE_INACTIVE" ;
VAL_ 609 VCFRONT_batteryLINScheduleDBG 7 "VC_LVBMS_LIN_SCHEDULE_SNA" 6 "VC_LVBMS_LIN_SCHEDULE_OTHER" 4 "VC_LVBMS_LIN_SCHEDULE_DEFAULT_2" 3 "VC_LVBMS_LIN_SCHEDULE_DEFAULT_1" 2 "VC_LVBMS_LIN_SCHEDULE_DIAGNOSTIC" 1 "VC_LVBMS_LIN_SCHEDULE_RESET" 0 "VC_LVBMS_LIN_SCHEDULE_OFF" ;
VAL_ 609 VCFRONT_LVBatteryStatusForDrive 2 "LV_BATTERY_EXIT_DRIVE_REQUESTED" 1 "LV_BATTERY_READY_FOR_DRIVE" 0 "LV_BATTERY_NOT_READY_FOR_DRIVE" ;
VAL_ 609 VCFRONT_LVBatteryType 5 "LV_BATTERY_TYPE_TESLA_48V_LI_ION" 4 "LV_BATTERY_TYPE_TESLA_16V_LI_ION" 3 "LV_BATTERY_TYPE_CATL_LI_ION" 2 "LV_BATTERY_TYPE_CLARIOS_B24_FLOODED" 1 "LV_BATTERY_TYPE_ATLASBX_B24_FLOODED" 0 "LV_BATTERY_TYPE_UNKNOWN" ;
VAL_ 609 VCFRONT_LVBMS_LVBusVoltageSource 3 "VC_LVBMS_VOLTAGE_SOURCE_LVBMS" 2 "VC_LVBMS_VOLTAGE_SOURCE_VBAT_MONITOR" 1 "VC_LVBMS_VOLTAGE_SOURCE_IBS" 0 "VC_LVBMS_VOLTAGE_SOURCE_NONE" ;
VAL_ 609 VCFRONT_LVBMS_LVPackCurrentSourc 2 "VC_LV_PACK_CURRENT_SOURCE_LVBMS" 1 "VC_LV_PACK_CURRENT_SOURCE_IBS" 0 "VC_LV_PACK_CURRENT_SOURCE_NONE" ;
VAL_ 609 VCFRONT_LVBatterySupportRqrdTrig 14336 "LV_BATTERY_SUPPORT_REQUIRED_TRIGGER_SOC_IMBALANCE_AND_CORRECTION" 12288 "LV_BATTERY_SUPPORT_REQUIRED_TRIGGER_IMBALANCE_AND_CORRECTION" 10240 "LV_BATTERY_SUPPORT_REQUIRED_TRIGGER_SOC_AND_CORRECTION" 8192 "LV_BATTERY_SUPPORT_REQUIRED_TRIGGER_CORRECTION" 6144 "LV_BATTERY_SUPPORT_REQUIRED_TRIGGER_SOC_AND_IMBALANCE" 4096 "LV_BATTERY_SUPPORT_REQUIRED_TRIGGER_IMBALANCE" 2048 "LV_BATTERY_SUPPORT_REQUIRED_TRIGGER_SOC" 1024 "LV_BATTERY_SUPPORT_REQUIRED_TRIGGER_POST_OTA" 512 "LV_BATTERY_SUPPORT_REQUIRED_TRIGGER_EXIT_TRANSPORT_MODE" 256 "LV_BATTERY_SUPPORT_REQUIRED_TRIGGER_POWER_ON_RESET" 128 "LV_BATTERY_SUPPORT_REQUIRED_TRIGGER_PERIODIC_CHARGE" 64 "LV_BATTERY_SUPPORT_REQUIRED_TRIGGER_AH_COUNT" 32 "LV_BATTERY_SUPPORT_REQUIRED_TRIGGER_UNKNOWN_VOLTAGE" 20 "LV_BATTERY_SUPPORT_REQUIRED_TRIGGER_RAW_VC_VOLTAGES" 16 "LV_BATTERY_SUPPORT_REQUIRED_TRIGGER_VBAT_RAW_VOLTAGE" 12 "LV_BATTERY_SUPPORT_REQUIRED_TRIGGER_RAW_BATTERY_VOLTAGES" 10 "LV_BATTERY_SUPPORT_REQUIRED_TRIGGER_PACK_VOLTAGES" 8 "LV_BATTERY_SUPPORT_REQUIRED_TRIGGER_PACK_RAW_VOLTAGE" 5 "LV_BATTERY_SUPPORT_REQUIRED_TRIGGER_IBS_VOLTAGES" 4 "LV_BATTERY_SUPPORT_REQUIRED_TRIGGER_IBS_RAW_VOLTAGE" 3 "LV_BATTERY_SUPPORT_REQUIRED_TRIGGER_FILTERED_VOLTAGES" 2 "LV_BATTERY_SUPPORT_REQUIRED_TRIGGER_PACK_FILTERED_VOLTAGE" 1 "LV_BATTERY_SUPPORT_REQUIRED_TRIGGER_IBS_FILTERED_VOLTAGE" 0 "LV_BATTERY_SUPPORT_REQUIRED_TRIGGER_NONE" ;
VAL_ 609 VCFRONT_voltageProfile 3 "VOLTAGE_PROFILE_ALWAYS_CLOSED_CONTACTORS" 2 "VOLTAGE_PROFILE_REDUCED_FLOAT" 1 "VOLTAGE_PROFILE_FLOAT" 0 "VOLTAGE_PROFILE_CHARGE" ;
VAL_ 1847 VCFRONT_LVBMS_FWBuildType 4 "INFO_MFG_BUILD" 3 "INFO_TRACEABLE_CI_BUILD" 2 "INFO_LOCAL_BUILD" 1 "INFO_PLATFORM_BUILD" 0 "INFO_UNKNOWN_BUILD" ;
VAL_ 2017 VCFRONT_LVHealthStatus 3 "BACKUP_COMPROMISED" 2 "LATENT_FAULT" 1 "HEALTHY_LIMITED" 0 "DOMAIN_HEALTHY" ;
VAL_ 2017 VCFRONT_LVStatusForDrive 6 "STATUS_FOR_DRIVE_ACTIVE_DECEL" 5 "STATUS_FOR_DRIVE_PULL_TO_SHOULDER" 4 "STATUS_FOR_DRIVE_LIMP" 3 "STATUS_FOR_DRIVE_RETURN_TO_SERVICE" 2 "STATUS_FOR_DRIVE_READY_LIMITED" 1 "STATUS_FOR_DRIVE_READY" 0 "STATUS_FOR_DRIVE_NOT_READY" ;
VAL_ 545 VCFRONT_vehiclePowerState 3 "VEHICLE_POWER_STATE_DRIVE" 2 "VEHICLE_POWER_STATE_ACCESSORY" 1 "VEHICLE_POWER_STATE_CONDITIONING" 0 "VEHICLE_POWER_STATE_OFF" ;
VAL_ 545 VCFRONT_cpLVRequest 3 "LV_FAULT" 2 "LV_GOING_DOWN" 1 "LV_ON" 0 "LV_OFF" ;
VAL_ 545 VCFRONT_epasLVState 3 "LV_FAULT" 2 "LV_GOING_DOWN" 1 "LV_ON" 0 "LV_OFF" ;
VAL_ 545 VCFRONT_hvcLVRequest 3 "LV_FAULT" 2 "LV_GOING_DOWN" 1 "LV_ON" 0 "LV_OFF" ;
VAL_ 545 VCFRONT_tasLVState 3 "LV_FAULT" 2 "LV_GOING_DOWN" 1 "LV_ON" 0 "LV_OFF" ;
VAL_ 545 VCFRONT_pcsLVState 3 "LV_FAULT" 2 "LV_GOING_DOWN" 1 "LV_ON" 0 "LV_OFF" ;
VAL_ 545 VCFRONT_CMPDLVState 3 "LV_FAULT" 2 "LV_GOING_DOWN" 1 "LV_ON" 0 "LV_OFF" ;
VAL_ 545 VCFRONT_hcmlLVState 3 "LV_FAULT" 2 "LV_GOING_DOWN" 1 "LV_ON" 0 "LV_OFF" ;
VAL_ 545 VCFRONT_hcmrLVState 3 "LV_FAULT" 2 "LV_GOING_DOWN" 1 "LV_ON" 0 "LV_OFF" ;
VAL_ 545 VCFRONT_MCUAudioLVState 3 "LV_FAULT" 2 "LV_GOING_DOWN" 1 "LV_ON" 0 "LV_OFF" ;
VAL_ 545 VCFRONT_espValveLVState 3 "LV_FAULT" 2 "LV_GOING_DOWN" 1 "LV_ON" 0 "LV_OFF" ;
VAL_ 545 VCFRONT_MCUGraphicsLVState 3 "LV_FAULT" 2 "LV_GOING_DOWN" 1 "LV_ON" 0 "LV_OFF" ;
VAL_ 545 VC_hvStateRequest 7 "VC_HV_REQUEST_STATE_RESERVED" 2 "VC_HV_REQUEST_STATE_HV_UP" 1 "VC_HV_REQUEST_STATE_LV_SUPPORT_ONLY" 0 "VC_HV_REQUEST_STATE_NONE" ;
VAL_ 545 VC_persistAccPortPowerState 4 "STATE_KEEP_AWAKE_OVERRIDDEN_NOTIFY_USER" 3 "STATE_KEEP_AWAKE_ALLOW_SLEEP" 2 "STATE_KEEP_AWAKE_ACTIVE" 1 "STATE_KEEP_AWAKE_ARMED" 0 "STATE_KEEP_AWAKE_DISARMED" ;
VAL_ 700 VCFRONT_radiatorFanState 7 "VC_mlxControllerState_MIA" 6 "VC_mlxControllerState_FAULTED" 5 "VC_mlxControllerState_UV_TEST" 4 "VC_mlxControllerState_SELF_TEST" 3 "VC_mlxControllerState_STANDBY" 2 "VC_mlxControllerState_COLD_STARTUP" 1 "VC_mlxControllerState_ENABLE" 0 "VC_mlxControllerState_IDLE" ;
VAL_ 700 VCFRONT_mlxLINCurrentSchedule 2 "DIAGNOSTIC" 1 "NORMAL" 0 "OFF" ;
VAL_ 700 VCFRONT_pumpPowertrainState 7 "VC_mlxControllerState_MIA" 6 "VC_mlxControllerState_FAULTED" 5 "VC_mlxControllerState_UV_TEST" 4 "VC_mlxControllerState_SELF_TEST" 3 "VC_mlxControllerState_STANDBY" 2 "VC_mlxControllerState_COLD_STARTUP" 1 "VC_mlxControllerState_ENABLE" 0 "VC_mlxControllerState_IDLE" ;
VAL_ 700 VCFRONT_pumpBatteryState 7 "VC_mlxControllerState_MIA" 6 "VC_mlxControllerState_FAULTED" 5 "VC_mlxControllerState_UV_TEST" 4 "VC_mlxControllerState_SELF_TEST" 3 "VC_mlxControllerState_STANDBY" 2 "VC_mlxControllerState_COLD_STARTUP" 1 "VC_mlxControllerState_ENABLE" 0 "VC_mlxControllerState_IDLE" ;
